AUTOSAR XML (schema 4-2-2)
package /STELLANTIS/EPT/ASWCs
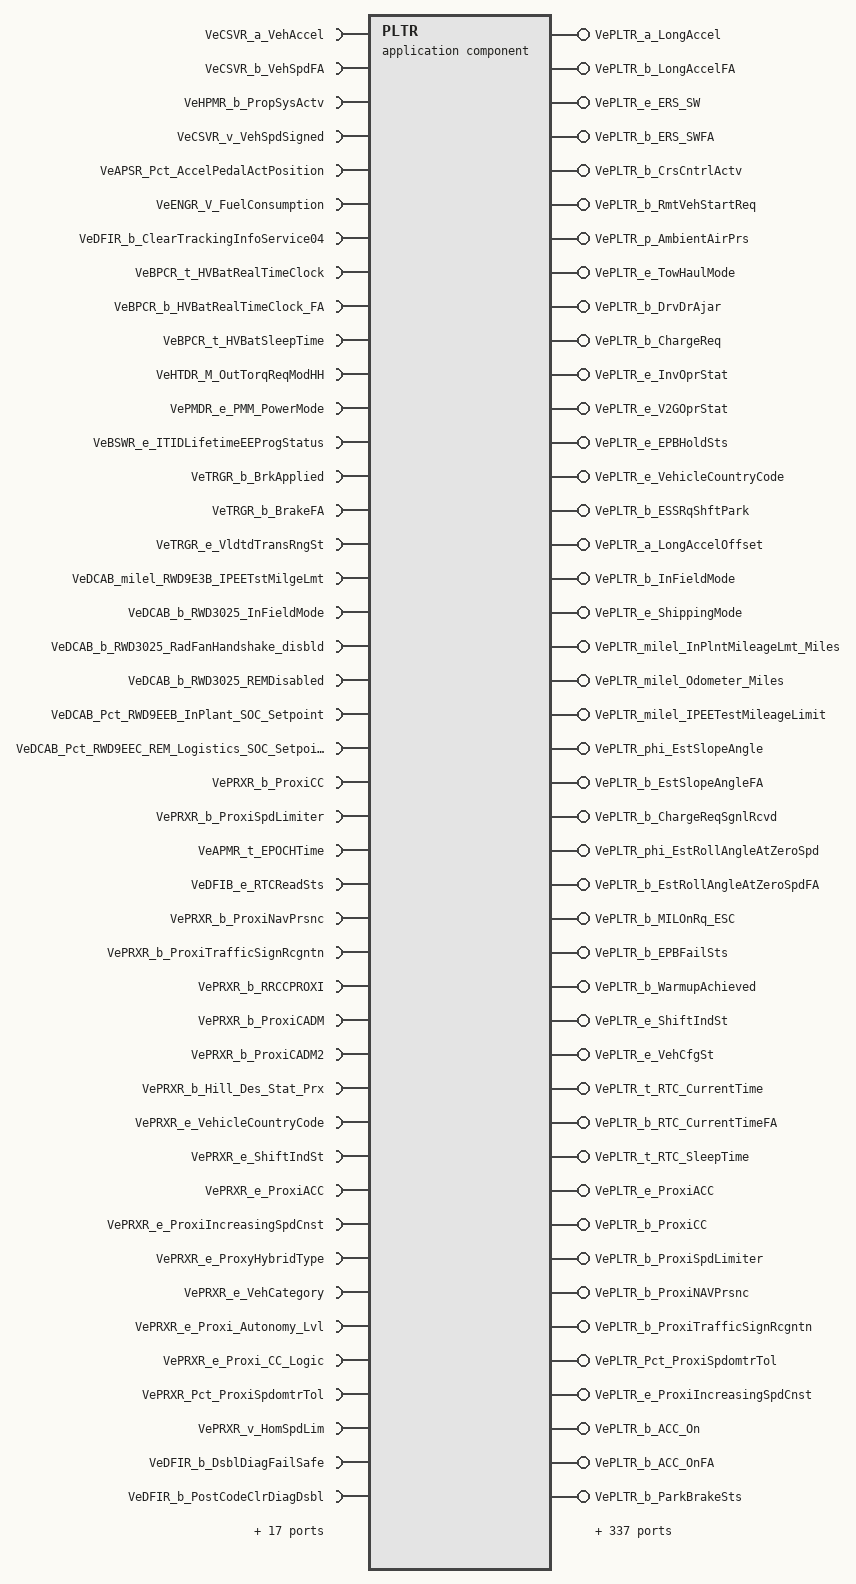
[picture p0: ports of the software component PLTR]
  application sw component type PLTR
    48 x require port:
      VeCSVR_a_VehAccel: nonqueued-receiver-com-spec{data-element=Value, init-value=0}, required-interface=VeCSVR_a_VehAccel
      VeCSVR_b_VehSpdFA: nonqueued-receiver-com-spec{data-element=Value, init-value=0}, required-interface=VeCSVR_b_VehSpdFA
      VeHPMR_b_PropSysActv: nonqueued-receiver-com-spec{data-element=Value, init-value=0}, required-interface=VeHPMR_b_PropSysActv
      VeCSVR_v_VehSpdSigned: nonqueued-receiver-com-spec{data-element=Value, init-value=0}, required-interface=VeCSVR_v_VehSpdSigned
      VeAPSR_Pct_AccelPedalActPosition: nonqueued-receiver-com-spec{data-element=Value, init-value=0}, required-interface=VeAPSR_Pct_AccelPedalActPosition
      VeENGR_V_FuelConsumption: nonqueued-receiver-com-spec{data-element=Value, init-value=0}, required-interface=VeENGR_V_FuelConsumption
      VeDFIR_b_ClearTrackingInfoService04: nonqueued-receiver-com-spec{data-element=Value, init-value=0}, required-interface=VeDFIR_b_ClearTrackingInfoService04
      VeBPCR_t_HVBatRealTimeClock: nonqueued-receiver-com-spec{data-element=Value, init-value=0}, required-interface=VeBPCR_t_HVBatRealTimeClock
      VeBPCR_b_HVBatRealTimeClock_FA: nonqueued-receiver-com-spec{data-element=Value, init-value=0}, required-interface=VeBPCR_b_HVBatRealTimeClock_FA
      VeBPCR_t_HVBatSleepTime: nonqueued-receiver-com-spec{data-element=Value, init-value=0}, required-interface=VeBPCR_t_HVBatSleepTime
      VeHTDR_M_OutTorqReqModHH: nonqueued-receiver-com-spec{data-element=Value, init-value=0}, required-interface=VeHTDR_M_OutTorqReqModHH
      VePMDR_e_PMM_PowerMode: nonqueued-receiver-com-spec{data-element=Value, init-value=CePMDR_e_PowerMode_Off}, required-interface=VePMDR_e_PMM_PowerMode
      VeBSWR_e_ITIDLifetimeEEProgStatus: nonqueued-receiver-com-spec{data-element=Value, init-value=0}, required-interface=VeBSWR_e_ITIDLifetimeEEProgStatus
      VeTRGR_b_BrkApplied: nonqueued-receiver-com-spec{data-element=Value, init-value=0}, required-interface=VeTRGR_b_BrkApplied
      VeTRGR_b_BrakeFA: nonqueued-receiver-com-spec{data-element=Value, init-value=0}, required-interface=VeTRGR_b_BrakeFA
      VeTRGR_e_VldtdTransRngSt: nonqueued-receiver-com-spec{data-element=Value, init-value=CeTRGR_e_NoSelectionAvailable}, required-interface=VeTRGR_e_VldtdTransRngSt
      VeDCAB_milel_RWD9E3B_IPEETstMilgeLmt: nonqueued-receiver-com-spec{data-element=Value, init-value=0}, required-interface=VeDCAB_milel_RWD9E3B_IPEETstMilgeLmt
      VeDCAB_b_RWD3025_InFieldMode: nonqueued-receiver-com-spec{data-element=Value, init-value=0}, required-interface=VeDCAB_b_RWD3025_InFieldMode
      VeDCAB_b_RWD3025_RadFanHandshake_disbld: nonqueued-receiver-com-spec{data-element=Value, init-value=0}, required-interface=VeDCAB_b_RWD3025_RadFanHandshake_disbld
      VeDCAB_b_RWD3025_REMDisabled: nonqueued-receiver-com-spec{data-element=Value, init-value=0}, required-interface=VeDCAB_b_RWD3025_REMDisabled
      VeDCAB_Pct_RWD9EEB_InPlant_SOC_Setpoint: nonqueued-receiver-com-spec{data-element=Value, init-value=0}, required-interface=VeDCAB_Pct_RWD9EEB_InPlant_SOC_Setpoint
      VeDCAB_Pct_RWD9EEC_REM_Logistics_SOC_Setpoint: nonqueued-receiver-com-spec{data-element=Value, init-value=0}, required-interface=VeDCAB_Pct_RWD9EEC_REM_Logistics_SOC_Setpoint
      VePRXR_b_ProxiCC: nonqueued-receiver-com-spec{data-element=Value, init-value=0}, required-interface=VePRXR_b_ProxiCC
      VePRXR_b_ProxiSpdLimiter: nonqueued-receiver-com-spec{data-element=Value, init-value=0}, required-interface=VePRXR_b_ProxiSpdLimiter
      VeAPMR_t_EPOCHTime: nonqueued-receiver-com-spec{data-element=Value, init-value=0}, required-interface=VeAPMR_t_EPOCHTime
      VeDFIB_e_RTCReadSts: nonqueued-receiver-com-spec{data-element=Value, init-value=CeDFIB_e_RTCCallInit}, required-interface=VeDFIB_e_RTCReadSts
      VePRXR_b_ProxiNavPrsnc: nonqueued-receiver-com-spec{data-element=Value, init-value=0}, required-interface=VePRXR_b_ProxiNavPrsnc
      VePRXR_b_ProxiTrafficSignRcgntn: nonqueued-receiver-com-spec{data-element=Value, init-value=0}, required-interface=VePRXR_b_ProxiTrafficSignRcgntn
      VePRXR_b_RRCCPROXI: nonqueued-receiver-com-spec{data-element=Value, init-value=0}, required-interface=VePRXR_b_RRCCPROXI
      VePRXR_b_ProxiCADM: nonqueued-receiver-com-spec{data-element=Value, init-value=0}, required-interface=VePRXR_b_ProxiCADM
      VePRXR_b_ProxiCADM2: nonqueued-receiver-com-spec{data-element=Value, init-value=0}, required-interface=VePRXR_b_ProxiCADM2
      VePRXR_b_Hill_Des_Stat_Prx: nonqueued-receiver-com-spec{data-element=Value, init-value=0}, required-interface=VePRXR_b_Hill_Des_Stat_Prx
      VePRXR_e_VehicleCountryCode: nonqueued-receiver-com-spec{data-element=Value, init-value=CePRXR_e_VCC_OTHERS}, required-interface=VePRXR_e_VehicleCountryCode
      VePRXR_e_ShiftIndSt: nonqueued-receiver-com-spec{data-element=Value, init-value=CePRXR_e_NotPresent}, required-interface=VePRXR_e_ShiftIndSt
      VePRXR_e_ProxiACC: nonqueued-receiver-com-spec{data-element=Value, init-value=CePRXR_e_ACC_Absent}, required-interface=VePRXR_e_ProxiACC
      VePRXR_e_ProxiIncreasingSpdCnst: nonqueued-receiver-com-spec{data-element=Value, init-value=CePRXR_e_Increasing_0}, required-interface=VePRXR_e_ProxiIncreasingSpdCnst
      VePRXR_e_ProxyHybridType: nonqueued-receiver-com-spec{data-element=Value, init-value=CePRXR_e_NotApplicable}, required-interface=VePRXR_e_ProxyHybridType
      VePRXR_e_VehCategory: nonqueued-receiver-com-spec{data-element=Value, init-value=CePRXR_e_Category_M1}, required-interface=VePRXR_e_VehCategory
      VePRXR_e_Proxi_Autonomy_Lvl: nonqueued-receiver-com-spec{data-element=Value, init-value=CePRXR_e_None_Level1}, required-interface=VePRXR_e_Proxi_Autonomy_Lvl
      VePRXR_e_Proxi_CC_Logic: nonqueued-receiver-com-spec{data-element=Value, init-value=CePRXR_e_Logic1}, required-interface=VePRXR_e_Proxi_CC_Logic
      VePRXR_Pct_ProxiSpdomtrTol: nonqueued-receiver-com-spec{data-element=Value, init-value=0}, required-interface=VePRXR_Pct_ProxiSpdomtrTol
      VePRXR_v_HomSpdLim: nonqueued-receiver-com-spec{data-element=Value, init-value=0}, required-interface=VePRXR_v_HomSpdLim
      VeDFIR_b_DsblDiagFailSafe: nonqueued-receiver-com-spec{data-element=Value, init-value=0}, required-interface=VeDFIR_b_DsblDiagFailSafe
      VeDFIR_b_PostCodeClrDiagDsbl: nonqueued-receiver-com-spec{data-element=Value, init-value=0}, required-interface=VeDFIR_b_PostCodeClrDiagDsbl
      VeDFIR_b_IsDiagGlobalConditionsValid: nonqueued-receiver-com-spec{data-element=Value, init-value=0}, required-interface=VeDFIR_b_IsDiagGlobalConditionsValid
      VeDMAB_y_StatusByte_IgnKeyOffTmrPerfTooFast: nonqueued-receiver-com-spec{data-element=Value, init-value=0}, required-interface=VeDMAB_y_StatusByte_IgnKeyOffTmrPerfTooFast
      VeDFIB_b_RTCChipErr: nonqueued-receiver-com-spec{data-element=Value, init-value=0}, required-interface=VeDFIB_b_RTCChipErr
      VeDMAB_y_StatusByte_ECUInplantmodeAct: nonqueued-receiver-com-spec{data-element=Value, init-value=0}, required-interface=VeDMAB_y_StatusByte_ECUInplantmodeAct
    368 x provide port:
      VePLTR_a_LongAccel: nonqueued-sender-com-spec{data-element=Value, init-value=0}, provided-interface=VePLTR_a_LongAccel
      VePLTR_b_LongAccelFA: nonqueued-sender-com-spec{data-element=Value, init-value=0}, provided-interface=VePLTR_b_LongAccelFA
      VePLTR_e_ERS_SW: nonqueued-sender-com-spec{data-element=Value, init-value=CeTRGR_e_ERSBttn_NotActvtd}, provided-interface=VePLTR_e_ERS_SW
      VePLTR_b_ERS_SWFA: nonqueued-sender-com-spec{data-element=Value, init-value=0}, provided-interface=VePLTR_b_ERS_SWFA
      VePLTR_b_CrsCntrlActv: nonqueued-sender-com-spec{data-element=Value, init-value=0}, provided-interface=VePLTR_b_CrsCntrlActv
      VePLTR_b_RmtVehStartReq: nonqueued-sender-com-spec{data-element=Value, init-value=0}, provided-interface=VePLTR_b_RmtVehStartReq
      VePLTR_p_AmbientAirPrs: nonqueued-sender-com-spec{data-element=Value, init-value=0}, provided-interface=VePLTR_p_AmbientAirPrs
      VePLTR_e_TowHaulMode: nonqueued-sender-com-spec{data-element=Value, init-value=CePLTR_e_Towing_MD_RQ_OFF}, provided-interface=VePLTR_e_TowHaulMode
      VePLTR_b_DrvDrAjar: nonqueued-sender-com-spec{data-element=Value, init-value=0}, provided-interface=VePLTR_b_DrvDrAjar
      VePLTR_b_ChargeReq: nonqueued-sender-com-spec{data-element=Value, init-value=0}, provided-interface=VePLTR_b_ChargeReq
      VePLTR_e_InvOprStat: nonqueued-sender-com-spec{data-element=Value, init-value=CePLTR_e_NoPlgIn_Tools}, provided-interface=VePLTR_e_InvOprStat
      VePLTR_e_V2GOprStat: nonqueued-sender-com-spec{data-element=Value, init-value=CePLTR_e_NoPlgIn}, provided-interface=VePLTR_e_V2GOprStat
      VePLTR_e_EPBHoldSts: nonqueued-sender-com-spec{data-element=Value, init-value=CePLTR_e_EPBHoldSts_REL}, provided-interface=VePLTR_e_EPBHoldSts
      VePLTR_e_VehicleCountryCode: nonqueued-sender-com-spec{data-element=Value, init-value=CePLTR_e_VCC_OTHERS}, provided-interface=VePLTR_e_VehicleCountryCode
      VePLTR_b_ESSRqShftPark: nonqueued-sender-com-spec{data-element=Value, init-value=0}, provided-interface=VePLTR_b_ESSRqShftPark
      VePLTR_a_LongAccelOffset: nonqueued-sender-com-spec{data-element=Value, init-value=0}, provided-interface=VePLTR_a_LongAccelOffset
      VePLTR_b_InFieldMode: nonqueued-sender-com-spec{data-element=Value, init-value=0}, provided-interface=VePLTR_b_InFieldMode
      VePLTR_e_ShippingMode: nonqueued-sender-com-spec{data-element=Value, init-value=CePLTR_e_ShipingMode_CUST_MD}, provided-interface=VePLTR_e_ShippingMode
      VePLTR_milel_InPlntMileageLmt_Miles: nonqueued-sender-com-spec{data-element=Value, init-value=0}, provided-interface=VePLTR_milel_InPlntMileageLmt_Miles
      VePLTR_milel_Odometer_Miles: nonqueued-sender-com-spec{data-element=Value, init-value=0}, provided-interface=VePLTR_milel_Odometer_Miles
      VePLTR_milel_IPEETestMileageLimit: nonqueued-sender-com-spec{data-element=Value, init-value=0}, provided-interface=VePLTR_milel_IPEETestMileageLimit
      VePLTR_phi_EstSlopeAngle: nonqueued-sender-com-spec{data-element=Value, init-value=0}, provided-interface=VePLTR_phi_EstSlopeAngle
      VePLTR_b_EstSlopeAngleFA: nonqueued-sender-com-spec{data-element=Value, init-value=0}, provided-interface=VePLTR_b_EstSlopeAngleFA
      VePLTR_b_ChargeReqSgnlRcvd: nonqueued-sender-com-spec{data-element=Value, init-value=0}, provided-interface=VePLTR_b_ChargeReqSgnlRcvd
      VePLTR_phi_EstRollAngleAtZeroSpd: nonqueued-sender-com-spec{data-element=Value, init-value=0}, provided-interface=VePLTR_phi_EstRollAngleAtZeroSpd
      VePLTR_b_EstRollAngleAtZeroSpdFA: nonqueued-sender-com-spec{data-element=Value, init-value=0}, provided-interface=VePLTR_b_EstRollAngleAtZeroSpdFA
      VePLTR_b_MILOnRq_ESC: nonqueued-sender-com-spec{data-element=Value, init-value=0}, provided-interface=VePLTR_b_MILOnRq_ESC
      VePLTR_b_EPBFailSts: nonqueued-sender-com-spec{data-element=Value, init-value=0}, provided-interface=VePLTR_b_EPBFailSts
      VePLTR_b_WarmupAchieved: nonqueued-sender-com-spec{data-element=Value, init-value=0}, provided-interface=VePLTR_b_WarmupAchieved
      VePLTR_e_ShiftIndSt: nonqueued-sender-com-spec{data-element=Value, init-value=CePLTR_e_NotPresent}, provided-interface=VePLTR_e_ShiftIndSt
      VePLTR_e_VehCfgSt: nonqueued-sender-com-spec{data-element=Value, init-value=CePLTR_e_NotAvailable}, provided-interface=VePLTR_e_VehCfgSt
      VePLTR_t_RTC_CurrentTime: nonqueued-sender-com-spec{data-element=Value, init-value=0}, provided-interface=VePLTR_t_RTC_CurrentTime
      VePLTR_b_RTC_CurrentTimeFA: nonqueued-sender-com-spec{data-element=Value, init-value=0}, provided-interface=VePLTR_b_RTC_CurrentTimeFA
      VePLTR_t_RTC_SleepTime: nonqueued-sender-com-spec{data-element=Value, init-value=0}, provided-interface=VePLTR_t_RTC_SleepTime
      VePLTR_e_ProxiACC: nonqueued-sender-com-spec{data-element=Value, init-value=CePLTR_e_ACC_Absent}, provided-interface=VePLTR_e_ProxiACC
      VePLTR_b_ProxiCC: nonqueued-sender-com-spec{data-element=Value, init-value=0}, provided-interface=VePLTR_b_ProxiCC
      VePLTR_b_ProxiSpdLimiter: nonqueued-sender-com-spec{data-element=Value, init-value=0}, provided-interface=VePLTR_b_ProxiSpdLimiter
      VePLTR_b_ProxiNAVPrsnc: nonqueued-sender-com-spec{data-element=Value, init-value=0}, provided-interface=VePLTR_b_ProxiNAVPrsnc
      VePLTR_b_ProxiTrafficSignRcgntn: nonqueued-sender-com-spec{data-element=Value, init-value=0}, provided-interface=VePLTR_b_ProxiTrafficSignRcgntn
      VePLTR_Pct_ProxiSpdomtrTol: nonqueued-sender-com-spec{data-element=Value, init-value=0}, provided-interface=VePLTR_Pct_ProxiSpdomtrTol
      VePLTR_e_ProxiIncreasingSpdCnst: nonqueued-sender-com-spec{data-element=Value, init-value=CePLTR_e_Increasing_0}, provided-interface=VePLTR_e_ProxiIncreasingSpdCnst
      VePLTR_b_ACC_On: nonqueued-sender-com-spec{data-element=Value, init-value=0}, provided-interface=VePLTR_b_ACC_On
      VePLTR_b_ACC_OnFA: nonqueued-sender-com-spec{data-element=Value, init-value=0}, provided-interface=VePLTR_b_ACC_OnFA
      VePLTR_b_ParkBrakeSts: nonqueued-sender-com-spec{data-element=Value, init-value=0}, provided-interface=VePLTR_b_ParkBrakeSts
      VePLTR_b_SpeedUnit: nonqueued-sender-com-spec{data-element=Value, init-value=0}, provided-interface=VePLTR_b_SpeedUnit
      VePLTR_e_ACCSystemSts: nonqueued-sender-com-spec{data-element=Value, init-value=CePLTR_e_Off}, provided-interface=VePLTR_e_ACCSystemSts
      VePLTR_b_InternalLightSts: nonqueued-sender-com-spec{data-element=Value, init-value=0}, provided-interface=VePLTR_b_InternalLightSts
      VePLTR_b_RmtVehStartReqFA: nonqueued-sender-com-spec{data-element=Value, init-value=0}, provided-interface=VePLTR_b_RmtVehStartReqFA
      VePLTR_b_DrvDrAjarFA: nonqueued-sender-com-spec{data-element=Value, init-value=0}, provided-interface=VePLTR_b_DrvDrAjarFA
      VePLTR_i_ShippingModeRaw: nonqueued-sender-com-spec{data-element=Value, init-value=0}, provided-interface=VePLTR_i_ShippingModeRaw
      VePLTR_b_REMDisabled: nonqueued-sender-com-spec{data-element=Value, init-value=0}, provided-interface=VePLTR_b_REMDisabled
      VePLTR_Pct_InPlant_SOCSetPt: nonqueued-sender-com-spec{data-element=Value, init-value=0}, provided-interface=VePLTR_Pct_InPlant_SOCSetPt
      VePLTR_Pct_REMLogisticSOCSetPt: nonqueued-sender-com-spec{data-element=Value, init-value=0}, provided-interface=VePLTR_Pct_REMLogisticSOCSetPt
      VePLTR_b_InPlantAllowCharge: nonqueued-sender-com-spec{data-element=Value, init-value=0}, provided-interface=VePLTR_b_InPlantAllowCharge
      VePLTR_e_Prmry_TransShiftPstn: nonqueued-sender-com-spec{data-element=Value, init-value=CeTRGR_e_NoSelectionAvailable}, provided-interface=VePLTR_e_Prmry_TransShiftPstn
      VePLTR_b_Prmry_TransShiftPstnFA: nonqueued-sender-com-spec{data-element=Value, init-value=0}, provided-interface=VePLTR_b_Prmry_TransShiftPstnFA
      VePLTR_e_ESMTransRngSt: nonqueued-sender-com-spec{data-element=Value, init-value=CeTRGR_e_NoSelectionAvailable}, provided-interface=VePLTR_e_ESMTransRngSt
      VePLTR_e_AutoPosCorrMd: nonqueued-sender-com-spec{data-element=Value, init-value=CeTRGR_e_AutoPosCorrMd_Off}, provided-interface=VePLTR_e_AutoPosCorrMd
      VePLTR_b_ShftLckFlt: nonqueued-sender-com-spec{data-element=Value, init-value=0}, provided-interface=VePLTR_b_ShftLckFlt
      VePLTR_b_RackFaultFA: nonqueued-sender-com-spec{data-element=Value, init-value=0}, provided-interface=VePLTR_b_RackFaultFA
      VePLTR_b_ShftSnsFA: nonqueued-sender-com-spec{data-element=Value, init-value=0}, provided-interface=VePLTR_b_ShftSnsFA
      VePLTR_b_ShiftDspFlt: nonqueued-sender-com-spec{data-element=Value, init-value=0}, provided-interface=VePLTR_b_ShiftDspFlt
      VePLTR_y_GatedParkSwFlt: nonqueued-sender-com-spec{data-element=Value, init-value=0}, provided-interface=VePLTR_y_GatedParkSwFlt
      VePLTR_e_ShiftLeverPosReq: nonqueued-sender-com-spec{data-element=Value, init-value=CeTRGR_e_NoSelectionAvailable}, provided-interface=VePLTR_e_ShiftLeverPosReq
      VePLTR_b_ShiftLeverFailSts: nonqueued-sender-com-spec{data-element=Value, init-value=0}, provided-interface=VePLTR_b_ShiftLeverFailSts
      VePLTR_b_PRNDFailSts: nonqueued-sender-com-spec{data-element=Value, init-value=0}, provided-interface=VePLTR_b_PRNDFailSts
      VePLTR_b_RFHub_ForcePark: nonqueued-sender-com-spec{data-element=Value, init-value=0}, provided-interface=VePLTR_b_RFHub_ForcePark
      VePLTR_e_Scndry_TransShiftPstn: nonqueued-sender-com-spec{data-element=Value, init-value=CeTRGR_e_NoSelectionAvailable}, provided-interface=VePLTR_e_Scndry_TransShiftPstn
      VePLTR_b_Scndry_TransShiftPstnFA: nonqueued-sender-com-spec{data-element=Value, init-value=0}, provided-interface=VePLTR_b_Scndry_TransShiftPstnFA
      VePLTR_e_RationalisedRngSt: nonqueued-sender-com-spec{data-element=Value, init-value=CeTRGR_e_NoSelectionAvailable}, provided-interface=VePLTR_e_RationalisedRngSt
      VePLTR_e_ValidatePstn: nonqueued-sender-com-spec{data-element=Value, init-value=CeTRGR_e_NoSelectionAvailable}, provided-interface=VePLTR_e_ValidatePstn
      VePLTR_b_ManualMode: nonqueued-sender-com-spec{data-element=Value, init-value=0}, provided-interface=VePLTR_b_ManualMode
      VePLTR_e_ProxyHybridType: nonqueued-sender-com-spec{data-element=Value, init-value=CePLTR_e_NotApplicable}, provided-interface=VePLTR_e_ProxyHybridType
      VePLTR_b_EPBHoldStsFA: nonqueued-sender-com-spec{data-element=Value, init-value=0}, provided-interface=VePLTR_b_EPBHoldStsFA
      VePLTR_Cnt_TotalEngRunTime_Recent: nonqueued-sender-com-spec{data-element=Value, init-value=0}, provided-interface=VePLTR_Cnt_TotalEngRunTime_Recent
      VePLTR_Cnt_TotalEngRunTime_Lifetime: nonqueued-sender-com-spec{data-element=Value, init-value=0}, provided-interface=VePLTR_Cnt_TotalEngRunTime_Lifetime
      VePLTR_Cnt_TotalIdleEngRunTime_Recent: nonqueued-sender-com-spec{data-element=Value, init-value=0}, provided-interface=VePLTR_Cnt_TotalIdleEngRunTime_Recent
      VePLTR_Cnt_TotalIdleEngRunTime_Lifetime: nonqueued-sender-com-spec{data-element=Value, init-value=0}, provided-interface=VePLTR_Cnt_TotalIdleEngRunTime_Lifetime
      VePLTR_e_Proxi_Autonomy_Lvl: nonqueued-sender-com-spec{data-element=Value, init-value=CePLTR_e_None_Level1}, provided-interface=VePLTR_e_Proxi_Autonomy_Lvl
      VePLTR_e_Proxi_CC_Logic: nonqueued-sender-com-spec{data-element=Value, init-value=CePLTR_e_Logic1}, provided-interface=VePLTR_e_Proxi_CC_Logic
      VePLTR_b_Hill_Des_Stat_Prx: nonqueued-sender-com-spec{data-element=Value, init-value=0}, provided-interface=VePLTR_b_Hill_Des_Stat_Prx
      VePLTR_e_MRM_Status: nonqueued-sender-com-spec{data-element=Value, init-value=CePLTR_e_Not_Active}, provided-interface=VePLTR_e_MRM_Status
      VePLTR_b_MRM_Status_FA: nonqueued-sender-com-spec{data-element=Value, init-value=0}, provided-interface=VePLTR_b_MRM_Status_FA
      VePLTR_e_LSMDExtReleaseLockReq: nonqueued-sender-com-spec{data-element=Value, init-value=CePLTR_e_NotActive}, provided-interface=VePLTR_e_LSMDExtReleaseLockReq
      VePLTR_b_HotEnablerReq: nonqueued-sender-com-spec{data-element=Value, init-value=0}, provided-interface=VePLTR_b_HotEnablerReq
      VePLTR_b_SpeedUnit_FA: nonqueued-sender-com-spec{data-element=Value, init-value=0}, provided-interface=VePLTR_b_SpeedUnit_FA
      VePLTR_b_ACCSystemSts_FA: nonqueued-sender-com-spec{data-element=Value, init-value=0}, provided-interface=VePLTR_b_ACCSystemSts_FA
      VePLTR_Pct_EstSlopeAnglePct: nonqueued-sender-com-spec{data-element=Value, init-value=0}, provided-interface=VePLTR_Pct_EstSlopeAnglePct
      VePLTR_b_RadFanHndShk_dsbld: nonqueued-sender-com-spec{data-element=Value, init-value=0}, provided-interface=VePLTR_b_RadFanHndShk_dsbld
      VePLTR_v_HomSpdLim: nonqueued-sender-com-spec{data-element=Value, init-value=0}, provided-interface=VePLTR_v_HomSpdLim
      VePLTR_e_VehCategory: nonqueued-sender-com-spec{data-element=Value, init-value=CePLTR_e_Category_M1}, provided-interface=VePLTR_e_VehCategory
      VePLTR_b_HDCEnabledCAN: nonqueued-sender-com-spec{data-element=Value, init-value=0}, provided-interface=VePLTR_b_HDCEnabledCAN
      VePLTR_b_HDCEnabledCAN_FA: nonqueued-sender-com-spec{data-element=Value, init-value=0}, provided-interface=VePLTR_b_HDCEnabledCAN_FA
      VePLTR_phi_LwsAngle: nonqueued-sender-com-spec{data-element=Value, init-value=0}, provided-interface=VePLTR_phi_LwsAngle
      VePLTR_dphi_LwsSpeed: nonqueued-sender-com-spec{data-element=Value, init-value=0}, provided-interface=VePLTR_dphi_LwsSpeed
      VePLTR_e_LwsAngleType: nonqueued-sender-com-spec{data-element=Value, init-value=CePLTR_e_Absolute}, provided-interface=VePLTR_e_LwsAngleType
      VePLTR_a_LongAccel_ORC: nonqueued-sender-com-spec{data-element=Value, init-value=0}, provided-interface=VePLTR_a_LongAccel_ORC
      VePLTR_a_LatAccel_ORC: nonqueued-sender-com-spec{data-element=Value, init-value=0}, provided-interface=VePLTR_a_LatAccel_ORC
      VePLTR_dphi_YawRate_ORC: nonqueued-sender-com-spec{data-element=Value, init-value=0}, provided-interface=VePLTR_dphi_YawRate_ORC
      VePLTR_b_LongAccelFailSts_ORC: nonqueued-sender-com-spec{data-element=Value, init-value=0}, provided-interface=VePLTR_b_LongAccelFailSts_ORC
      VePLTR_b_LatAccelFailSts_ORC: nonqueued-sender-com-spec{data-element=Value, init-value=0}, provided-interface=VePLTR_b_LatAccelFailSts_ORC
      VePLTR_b_YawRateFailSts_ORC: nonqueued-sender-com-spec{data-element=Value, init-value=0}, provided-interface=VePLTR_b_YawRateFailSts_ORC
      VePLTR_e_MRM_Status_C2_FA: nonqueued-sender-com-spec{data-element=Value, init-value=0}, provided-interface=VePLTR_e_MRM_Status_C2_FA
      VePLTR_e_MRM_Status_C2: nonqueued-sender-com-spec{data-element=Value, init-value=CePLTR_e_Not_Active}, provided-interface=VePLTR_e_MRM_Status_C2
      VePLTR_b_ProxiCADM: nonqueued-sender-com-spec{data-element=Value, init-value=0}, provided-interface=VePLTR_b_ProxiCADM
      VePLTR_b_ProxiCADM2: nonqueued-sender-com-spec{data-element=Value, init-value=0}, provided-interface=VePLTR_b_ProxiCADM2
      VePLTR_W_Inverter_PowerDraw: nonqueued-sender-com-spec{data-element=Value, init-value=0}, provided-interface=VePLTR_W_Inverter_PowerDraw
      VePLTR_b_Inverter_PowerDraw_FA: nonqueued-sender-com-spec{data-element=Value, init-value=0}, provided-interface=VePLTR_b_Inverter_PowerDraw_FA
      VePLTR_b_Worksite_Inverter_Active: nonqueued-sender-com-spec{data-element=Value, init-value=0}, provided-interface=VePLTR_b_Worksite_Inverter_Active
      VePLTR_b_Worksite_Inverter_Active_FA: nonqueued-sender-com-spec{data-element=Value, init-value=0}, provided-interface=VePLTR_b_Worksite_Inverter_Active_FA
      VePLTR_e_Worksite_Inverter_Sts: nonqueued-sender-com-spec{data-element=Value, init-value=CePLTR_e_WSInverterSts_NOT_ACTIVE}, provided-interface=VePLTR_e_Worksite_Inverter_Sts
      VePLTR_b_DAI_Enbl: nonqueued-sender-com-spec{data-element=Value, init-value=0}, provided-interface=VePLTR_b_DAI_Enbl
      VePLTR_b_AmbientAirPrsFA: nonqueued-sender-com-spec{data-element=Value, init-value=0}, provided-interface=VePLTR_b_AmbientAirPrsFA
      VePLTR_pmbar_AmbientAirPrs: nonqueued-sender-com-spec{data-element=Value, init-value=0}, provided-interface=VePLTR_pmbar_AmbientAirPrs
      VePLTR_b_FuelLevelLowClster: nonqueued-sender-com-spec{data-element=Value, init-value=0}, provided-interface=VePLTR_b_FuelLevelLowClster
      VePLTR_b_CC_Type: nonqueued-sender-com-spec{data-element=Value, init-value=0}, provided-interface=VePLTR_b_CC_Type
      VePLTR_a_LatAccel: nonqueued-sender-com-spec{data-element=Value, init-value=0}, provided-interface=VePLTR_a_LatAccel
      VePLTR_b_DriverDetected: nonqueued-sender-com-spec{data-element=Value, init-value=0}, provided-interface=VePLTR_b_DriverDetected
      VePLTR_b_RRCCPROXI: nonqueued-sender-com-spec{data-element=Value, init-value=0}, provided-interface=VePLTR_b_RRCCPROXI
      VePLTR_e_BSM_AxleTrq_Enbld: nonqueued-sender-com-spec{data-element=Value, init-value=CePLTR_e_No_Req}, provided-interface=VePLTR_e_BSM_AxleTrq_Enbld
      VePLTR_e_FaultSts_ECUInplantmodeAct: nonqueued-sender-com-spec{data-element=Value, init-value=CeDFIB_e_Init}, provided-interface=VePLTR_e_FaultSts_ECUInplantmodeAct
      VePLTR_e_HAS_TelltaleSts: nonqueued-sender-com-spec{data-element=Value, init-value=CePLTR_e_HAS_TelltaleSts_OFF}, provided-interface=VePLTR_e_HAS_TelltaleSts
      VePLTR_b_HAS_TelltaleSts_FA: nonqueued-sender-com-spec{data-element=Value, init-value=0}, provided-interface=VePLTR_b_HAS_TelltaleSts_FA
      VePLTR_e_AEBSystemSts: nonqueued-sender-com-spec{data-element=Value, init-value=CePLTR_e_FCW_Off}, provided-interface=VePLTR_e_AEBSystemSts
      VePLTR_b_AEBSystemSts_FA: nonqueued-sender-com-spec{data-element=Value, init-value=0}, provided-interface=VePLTR_b_AEBSystemSts_FA
      VePLTR_e_Command_15Sts: nonqueued-sender-com-spec{data-element=Value, init-value=CePLTR_e_Not_Pressed}, provided-interface=VePLTR_e_Command_15Sts
      VePLTR_b_Command_15Sts_FA: nonqueued-sender-com-spec{data-element=Value, init-value=0}, provided-interface=VePLTR_b_Command_15Sts_FA
      VePLTR_b_LHRDoorSts: nonqueued-sender-com-spec{data-element=Value, init-value=0}, provided-interface=VePLTR_b_LHRDoorSts
      VePLTR_b_LHRDoorSts_FA: nonqueued-sender-com-spec{data-element=Value, init-value=0}, provided-interface=VePLTR_b_LHRDoorSts_FA
      VePLTR_b_PsngrDoorSts: nonqueued-sender-com-spec{data-element=Value, init-value=0}, provided-interface=VePLTR_b_PsngrDoorSts
      VePLTR_b_PsngrDoorSts_FA: nonqueued-sender-com-spec{data-element=Value, init-value=0}, provided-interface=VePLTR_b_PsngrDoorSts_FA
      VePLTR_b_ParkBrakeSts_FA: nonqueued-sender-com-spec{data-element=Value, init-value=0}, provided-interface=VePLTR_b_ParkBrakeSts_FA
      VePLTR_b_RHatchSts: nonqueued-sender-com-spec{data-element=Value, init-value=0}, provided-interface=VePLTR_b_RHatchSts
      VePLTR_b_RHatchSts_FA: nonqueued-sender-com-spec{data-element=Value, init-value=0}, provided-interface=VePLTR_b_RHatchSts_FA
      VePLTR_b_RHRDoorSts: nonqueued-sender-com-spec{data-element=Value, init-value=0}, provided-interface=VePLTR_b_RHRDoorSts
      VePLTR_b_RHRDoorSts_FA: nonqueued-sender-com-spec{data-element=Value, init-value=0}, provided-interface=VePLTR_b_RHRDoorSts_FA
      VePLTR_b_ImmoParkReq: nonqueued-sender-com-spec{data-element=Value, init-value=0}, provided-interface=VePLTR_b_ImmoParkReq
      VePLTR_b_LatAccelFA: nonqueued-sender-com-spec{data-element=Value, init-value=0}, provided-interface=VePLTR_b_LatAccelFA
      VePLTR_b_LwsAngleFA: nonqueued-sender-com-spec{data-element=Value, init-value=0}, provided-interface=VePLTR_b_LwsAngleFA
      VePLTR_e_eBurn_Stages: nonqueued-sender-com-spec{data-element=Value, init-value=CePLTR_e_eBurn_NormalStage}, provided-interface=VePLTR_e_eBurn_Stages
      VePLTR_b_eBurn_Stages_FA: nonqueued-sender-com-spec{data-element=Value, init-value=0}, provided-interface=VePLTR_b_eBurn_Stages_FA
      VePLTR_l_TravelDistance: nonqueued-sender-com-spec{data-element=Value, init-value=0}, provided-interface=VePLTR_l_TravelDistance
      VePLTR_b_TravelDistance_FA: nonqueued-sender-com-spec{data-element=Value, init-value=0}, provided-interface=VePLTR_b_TravelDistance_FA
      VePLTR_e_FaultSts_IgnKeyOffTmrPerfTooFast: nonqueued-sender-com-spec{data-element=Value, init-value=CeDFIB_e_Init}, provided-interface=VePLTR_e_FaultSts_IgnKeyOffTmrPerfTooFast
      VePLTR_t_HCPOffTime: nonqueued-sender-com-spec{data-element=Value, init-value=0}, provided-interface=VePLTR_t_HCPOffTime
      VePLTR_b_HCPOffTimeFA: nonqueued-sender-com-spec{data-element=Value, init-value=0}, provided-interface=VePLTR_b_HCPOffTimeFA
      VePLTR_b_BatteryWasDisconnected: nonqueued-sender-com-spec{data-element=Value, init-value=0}, provided-interface=VePLTR_b_BatteryWasDisconnected
      VePLTR_e_SelectSpdSts: nonqueued-sender-com-spec{data-element=Value, init-value=CePLTR_e_SelectSpdSts_OFF}, provided-interface=VePLTR_e_SelectSpdSts
      VePLTR_b_SelectSpdSts_FA: nonqueued-sender-com-spec{data-element=Value, init-value=0}, provided-interface=VePLTR_b_SelectSpdSts_FA
      VePLTR_e_ParkingGearShiftReq_BSM: nonqueued-sender-com-spec{data-element=Value, init-value=CePLTR_e_GearShiftReq_Idle}, provided-interface=VePLTR_e_ParkingGearShiftReq_BSM
      VePLTR_b_ParkingGearShiftReq_BSM_FA: nonqueued-sender-com-spec{data-element=Value, init-value=0}, provided-interface=VePLTR_b_ParkingGearShiftReq_BSM_FA
      VePLTR_Pct_Slope: nonqueued-sender-com-spec{data-element=Value, init-value=0}, provided-interface=VePLTR_Pct_Slope
      VePLTR_b_Slope_FA: nonqueued-sender-com-spec{data-element=Value, init-value=0}, provided-interface=VePLTR_b_Slope_FA
      VePLTR_y_FobSearchResult: nonqueued-sender-com-spec{data-element=Value, init-value=0}, provided-interface=VePLTR_y_FobSearchResult
      VePLTR_b_FobSearchResult_FA: nonqueued-sender-com-spec{data-element=Value, init-value=0}, provided-interface=VePLTR_b_FobSearchResult_FA
      VePLTR_b_Secure_Idle_Req: nonqueued-sender-com-spec{data-element=Value, init-value=0}, provided-interface=VePLTR_b_Secure_Idle_Req
      VePLTR_b_Secure_Idle_Req_FA: nonqueued-sender-com-spec{data-element=Value, init-value=0}, provided-interface=VePLTR_b_Secure_Idle_Req_FA
      VePLTR_e_HiBmLvr_Stat: nonqueued-sender-com-spec{data-element=Value, init-value=CePLTR_e_HiBmLvr_Stat_Idle}, provided-interface=VePLTR_e_HiBmLvr_Stat
      VePLTR_b_HiBmLvr_Stat_FA: nonqueued-sender-com-spec{data-element=Value, init-value=0}, provided-interface=VePLTR_b_HiBmLvr_Stat_FA
      VePLTR_b_RearFogLightSts: nonqueued-sender-com-spec{data-element=Value, init-value=0}, provided-interface=VePLTR_b_RearFogLightSts
      VePLTR_y_AUD_LVL: nonqueued-sender-com-spec{data-element=Value, init-value=0}, provided-interface=VePLTR_y_AUD_LVL
      VePLTR_b_AUD_LVL_FA: nonqueued-sender-com-spec{data-element=Value, init-value=0}, provided-interface=VePLTR_b_AUD_LVL_FA
      VePLTR_b_ADS_SrvSys: nonqueued-sender-com-spec{data-element=Value, init-value=0}, provided-interface=VePLTR_b_ADS_SrvSys
      VePLTR_b_ADS_SrvSys_FA: nonqueued-sender-com-spec{data-element=Value, init-value=0}, provided-interface=VePLTR_b_ADS_SrvSys_FA
      VePLTR_b_ASCM_Srv: nonqueued-sender-com-spec{data-element=Value, init-value=0}, provided-interface=VePLTR_b_ASCM_Srv
      VePLTR_b_ASCM_Srv_FA: nonqueued-sender-com-spec{data-element=Value, init-value=0}, provided-interface=VePLTR_b_ASCM_Srv_FA
      VePLTR_e_ASCM_Stat: nonqueued-sender-com-spec{data-element=Value, init-value=CePLTR_e_ASCM_Stat_NONE}, provided-interface=VePLTR_e_ASCM_Stat
      VePLTR_b_ASCM_Stat_FA: nonqueued-sender-com-spec{data-element=Value, init-value=0}, provided-interface=VePLTR_b_ASCM_Stat_FA
      VePLTR_b_ASCM_SysFail: nonqueued-sender-com-spec{data-element=Value, init-value=0}, provided-interface=VePLTR_b_ASCM_SysFail
      VePLTR_b_ASCM_SysFail_FA: nonqueued-sender-com-spec{data-element=Value, init-value=0}, provided-interface=VePLTR_b_ASCM_SysFail_FA
      VePLTR_b_DriverSeatBeltStsFA: nonqueued-sender-com-spec{data-element=Value, init-value=0}, provided-interface=VePLTR_b_DriverSeatBeltStsFA
      VePLTR_e_DriverSeatBeltSts: nonqueued-sender-com-spec{data-element=Value, init-value=CePLTR_e_DRV_SEATBELT_OK}, provided-interface=VePLTR_e_DriverSeatBeltSts
      VePLTR_kl_Odometer_Km: nonqueued-sender-com-spec{data-element=Value, init-value=0}, provided-interface=VePLTR_kl_Odometer_Km
      VePLTR_b_Odometer_KmFA: nonqueued-sender-com-spec{data-element=Value, init-value=0}, provided-interface=VePLTR_b_Odometer_KmFA
      VePLTR_dVh_FuelConsumption_avrg: nonqueued-sender-com-spec{data-element=Value, init-value=0}, provided-interface=VePLTR_dVh_FuelConsumption_avrg
      VePLTR_b_ClrTrackingInfo: nonqueued-sender-com-spec{data-element=Value, init-value=0}, provided-interface=VePLTR_b_ClrTrackingInfo
      VePLTR_e_ECMVtdFreeze: nonqueued-sender-com-spec{data-element=Value, init-value=CePLTR_e_NoReset}, provided-interface=VePLTR_e_ECMVtdFreeze
      VePLTR_b_ResetFlagLifetime_EEerror: nonqueued-sender-com-spec{data-element=Value, init-value=0}, provided-interface=VePLTR_b_ResetFlagLifetime_EEerror
      VePLTR_b_ResetFlagRecent_EEerror: nonqueued-sender-com-spec{data-element=Value, init-value=0}, provided-interface=VePLTR_b_ResetFlagRecent_EEerror
      FsftPLTR_Pct_Slope: server-com-spec=FsftPLTR_Pct_Slope, provided-interface=FsftPLTR_Pct_Slope
      FsftPLTR_a_LongAccel: server-com-spec=FsftPLTR_a_LongAccel, provided-interface=FsftPLTR_a_LongAccel
      FsftPLTR_a_LongAccelOffset: server-com-spec=FsftPLTR_a_LongAccelOffset, provided-interface=FsftPLTR_a_LongAccelOffset
      FsftPLTR_a_TransAccel: server-com-spec=FsftPLTR_a_TransAccel, provided-interface=FsftPLTR_a_TransAccel
      FsftPLTR_a_TransAccelOffset: server-com-spec=FsftPLTR_a_TransAccelOffset, provided-interface=FsftPLTR_a_TransAccelOffset
      FsftPLTR_b_ACC_On: server-com-spec=FsftPLTR_b_ACC_On, provided-interface=FsftPLTR_b_ACC_On
      FsftPLTR_b_ASCM_Srv: server-com-spec=FsftPLTR_b_ASCM_Srv, provided-interface=FsftPLTR_b_ASCM_Srv
      FsftPLTR_b_ASCM_SysFail: server-com-spec=FsftPLTR_b_ASCM_SysFail, provided-interface=FsftPLTR_b_ASCM_SysFail
      FsftPLTR_b_ASCM_SysSys: server-com-spec=FsftPLTR_b_ASCM_SysSys, provided-interface=FsftPLTR_b_ASCM_SysSys
      FsftPLTR_b_ChargeReq: server-com-spec=FsftPLTR_b_ChargeReq, provided-interface=FsftPLTR_b_ChargeReq
      FsftPLTR_b_DrvDrAjar: server-com-spec=FsftPLTR_b_DrvDrAjar, provided-interface=FsftPLTR_b_DrvDrAjar
      FsftPLTR_b_EPBFailSts: server-com-spec=FsftPLTR_b_EPBFailSts, provided-interface=FsftPLTR_b_EPBFailSts
      FsftPLTR_b_ESSActvEBrake: server-com-spec=FsftPLTR_b_ESSActvEBrake, provided-interface=FsftPLTR_b_ESSActvEBrake
      FsftPLTR_b_ESSRqShftPark: server-com-spec=FsftPLTR_b_ESSRqShftPark, provided-interface=FsftPLTR_b_ESSRqShftPark
      FsftPLTR_b_HDCEnabledCAN: server-com-spec=FsftPLTR_b_HDCEnabledCAN, provided-interface=FsftPLTR_b_HDCEnabledCAN
      FsftPLTR_b_ImmoParkReq: server-com-spec=FsftPLTR_b_ImmoParkReq, provided-interface=FsftPLTR_b_ImmoParkReq
      FsftPLTR_b_Inverter_PowerDraw: server-com-spec=FsftPLTR_b_Inverter_PowerDraw, provided-interface=FsftPLTR_b_Inverter_PowerDraw
      FsftPLTR_b_LHRDoorSts: server-com-spec=FsftPLTR_b_LHRDoorSts, provided-interface=FsftPLTR_b_LHRDoorSts
      FsftPLTR_b_MILOnRq_ESC: server-com-spec=FsftPLTR_b_MILOnRq_ESC, provided-interface=FsftPLTR_b_MILOnRq_ESC
      FsftPLTR_b_ParkBrakeSts: server-com-spec=FsftPLTR_b_ParkBrakeSts, provided-interface=FsftPLTR_b_ParkBrakeSts
      FsftPLTR_b_Prmry_AutoPosCorrMd: server-com-spec=FsftPLTR_b_Prmry_AutoPosCorrMd, provided-interface=FsftPLTR_b_Prmry_AutoPosCorrMd
      FsftPLTR_b_Prmry_ForcePark: server-com-spec=FsftPLTR_b_Prmry_ForcePark, provided-interface=FsftPLTR_b_Prmry_ForcePark
      FsftPLTR_b_Prmry_ManualMode: server-com-spec=FsftPLTR_b_Prmry_ManualMode, provided-interface=FsftPLTR_b_Prmry_ManualMode
      FsftPLTR_b_Prmry_PRNDFailSts: server-com-spec=FsftPLTR_b_Prmry_PRNDFailSts, provided-interface=FsftPLTR_b_Prmry_PRNDFailSts
      FsftPLTR_b_Prmry_PRND_ValidatePstn: server-com-spec=FsftPLTR_b_Prmry_PRND_ValidatePstn, provided-interface=FsftPLTR_b_Prmry_PRND_ValidatePstn
      FsftPLTR_b_Prmry_RackDetentSensorFA: server-com-spec=FsftPLTR_b_Prmry_RackDetentSensorFA, provided-interface=FsftPLTR_b_Prmry_RackDetentSensorFA
      FsftPLTR_b_Prmry_ShiftLeverFailSts: server-com-spec=FsftPLTR_b_Prmry_ShiftLeverFailSts, provided-interface=FsftPLTR_b_Prmry_ShiftLeverFailSts
      FsftPLTR_b_Prmry_ShiftLeverPositionReq: server-com-spec=FsftPLTR_b_Prmry_ShiftLeverPositionReq, provided-interface=FsftPLTR_b_Prmry_ShiftLeverPositionReq
      FsftPLTR_b_Prmry_ShiftLockFA: server-com-spec=FsftPLTR_b_Prmry_ShiftLockFA, provided-interface=FsftPLTR_b_Prmry_ShiftLockFA
      FsftPLTR_b_Prmry_ShiftSnsFA: server-com-spec=FsftPLTR_b_Prmry_ShiftSnsFA, provided-interface=FsftPLTR_b_Prmry_ShiftSnsFA
      FsftPLTR_b_Prmry_ShifterDispFA: server-com-spec=FsftPLTR_b_Prmry_ShifterDispFA, provided-interface=FsftPLTR_b_Prmry_ShifterDispFA
      FsftPLTR_b_Prmry_TransShiftPstn: server-com-spec=FsftPLTR_b_Prmry_TransShiftPstn, provided-interface=FsftPLTR_b_Prmry_TransShiftPstn
      FsftPLTR_b_PsngrDoorSts: server-com-spec=FsftPLTR_b_PsngrDoorSts, provided-interface=FsftPLTR_b_PsngrDoorSts
      FsftPLTR_b_RHRDoorSts: server-com-spec=FsftPLTR_b_RHRDoorSts, provided-interface=FsftPLTR_b_RHRDoorSts
      FsftPLTR_b_RHatchSts: server-com-spec=FsftPLTR_b_RHatchSts, provided-interface=FsftPLTR_b_RHatchSts
      FsftPLTR_b_RmtVehStartReq: server-com-spec=FsftPLTR_b_RmtVehStartReq, provided-interface=FsftPLTR_b_RmtVehStartReq
      FsftPLTR_b_Scndry_AutoPosCorrMd: server-com-spec=FsftPLTR_b_Scndry_AutoPosCorrMd, provided-interface=FsftPLTR_b_Scndry_AutoPosCorrMd
      FsftPLTR_b_Scndry_ForcePark: server-com-spec=FsftPLTR_b_Scndry_ForcePark, provided-interface=FsftPLTR_b_Scndry_ForcePark
      FsftPLTR_b_Scndry_PRNDFailSts: server-com-spec=FsftPLTR_b_Scndry_PRNDFailSts, provided-interface=FsftPLTR_b_Scndry_PRNDFailSts
      FsftPLTR_b_Scndry_PRND_ValidatePstn: server-com-spec=FsftPLTR_b_Scndry_PRND_ValidatePstn, provided-interface=FsftPLTR_b_Scndry_PRND_ValidatePstn
      FsftPLTR_b_Scndry_RackDetentSensorFA: server-com-spec=FsftPLTR_b_Scndry_RackDetentSensorFA, provided-interface=FsftPLTR_b_Scndry_RackDetentSensorFA
      FsftPLTR_b_Scndry_ShiftLeverFailSts: server-com-spec=FsftPLTR_b_Scndry_ShiftLeverFailSts, provided-interface=FsftPLTR_b_Scndry_ShiftLeverFailSts
      FsftPLTR_b_Scndry_ShiftLeverPositionReq: server-com-spec=FsftPLTR_b_Scndry_ShiftLeverPositionReq, provided-interface=FsftPLTR_b_Scndry_ShiftLeverPositionReq
      FsftPLTR_b_Scndry_ShiftLockFA: server-com-spec=FsftPLTR_b_Scndry_ShiftLockFA, provided-interface=FsftPLTR_b_Scndry_ShiftLockFA
      FsftPLTR_b_Scndry_ShiftSnsFA: server-com-spec=FsftPLTR_b_Scndry_ShiftSnsFA, provided-interface=FsftPLTR_b_Scndry_ShiftSnsFA
      FsftPLTR_b_Scndry_ShifterDispFA: server-com-spec=FsftPLTR_b_Scndry_ShifterDispFA, provided-interface=FsftPLTR_b_Scndry_ShifterDispFA
      FsftPLTR_b_Scndry_TransShiftPstn: server-com-spec=FsftPLTR_b_Scndry_TransShiftPstn, provided-interface=FsftPLTR_b_Scndry_TransShiftPstn
      FsftPLTR_b_Secure_Idle_Req: server-com-spec=FsftPLTR_b_Secure_Idle_Req, provided-interface=FsftPLTR_b_Secure_Idle_Req
      FsftPLTR_b_SpeedUnit: server-com-spec=FsftPLTR_b_SpeedUnit, provided-interface=FsftPLTR_b_SpeedUnit
      FsftPLTR_b_Worksite_Inverter_Active: server-com-spec=FsftPLTR_b_Worksite_Inverter_Active, provided-interface=FsftPLTR_b_Worksite_Inverter_Active
      FsftPLTR_e_ACCSystemSts: server-com-spec=FsftPLTR_e_ACCSystemSts, provided-interface=FsftPLTR_e_ACCSystemSts
      FsftPLTR_e_AEBSystemSts: server-com-spec=FsftPLTR_e_AEBSystemSts, provided-interface=FsftPLTR_e_AEBSystemSts
      FsftPLTR_e_ASCM_Stat: server-com-spec=FsftPLTR_e_ASCM_Stat, provided-interface=FsftPLTR_e_ASCM_Stat
      FsftPLTR_e_Command_15Sts: server-com-spec=FsftPLTR_e_Command_15Sts, provided-interface=FsftPLTR_e_Command_15Sts
      FsftPLTR_e_DriverDoorOnOffSts: server-com-spec=FsftPLTR_e_DriverDoorOnOffSts, provided-interface=FsftPLTR_e_DriverDoorOnOffSts
      FsftPLTR_e_DriverSeatBeltSts: server-com-spec=FsftPLTR_e_DriverSeatBeltSts, provided-interface=FsftPLTR_e_DriverSeatBeltSts
      FsftPLTR_e_DrvrSeatSnsrSts: server-com-spec=FsftPLTR_e_DrvrSeatSnsrSts, provided-interface=FsftPLTR_e_DrvrSeatSnsrSts
      FsftPLTR_e_EPBHoldSt: server-com-spec=FsftPLTR_e_EPBHoldSt, provided-interface=FsftPLTR_e_EPBHoldSt
      FsftPLTR_e_ERS_SW: server-com-spec=FsftPLTR_e_ERS_SW, provided-interface=FsftPLTR_e_ERS_SW
      FsftPLTR_e_HAS_TelltaleSts: server-com-spec=FsftPLTR_e_HAS_TelltaleSts, provided-interface=FsftPLTR_e_HAS_TelltaleSts
      FsftPLTR_e_HiBmLvr_Stat: server-com-spec=FsftPLTR_e_HiBmLvr_Stat, provided-interface=FsftPLTR_e_HiBmLvr_Stat
      FsftPLTR_e_LSMDExtReleaseLockReq: server-com-spec=FsftPLTR_e_LSMDExtReleaseLockReq, provided-interface=FsftPLTR_e_LSMDExtReleaseLockReq
      FsftPLTR_e_MRM_Status: server-com-spec=FsftPLTR_e_MRM_Status, provided-interface=FsftPLTR_e_MRM_Status
      FsftPLTR_e_MRM_Status_C2: server-com-spec=FsftPLTR_e_MRM_Status_C2, provided-interface=FsftPLTR_e_MRM_Status_C2
      FsftPLTR_e_ParkingGearShiftReq_BSM: server-com-spec=FsftPLTR_e_ParkingGearShiftReq_BSM, provided-interface=FsftPLTR_e_ParkingGearShiftReq_BSM
      FsftPLTR_e_SelectSpdSts: server-com-spec=FsftPLTR_e_SelectSpdSts, provided-interface=FsftPLTR_e_SelectSpdSts
      FsftPLTR_e_TowHaulMode: server-com-spec=FsftPLTR_e_TowHaulMode, provided-interface=FsftPLTR_e_TowHaulMode
      FsftPLTR_e_VehicleCountryCode: server-com-spec=FsftPLTR_e_VehicleCountryCode, provided-interface=FsftPLTR_e_VehicleCountryCode
      FsftPLTR_e_eBurn_Stages: server-com-spec=FsftPLTR_e_eBurn_Stages, provided-interface=FsftPLTR_e_eBurn_Stages
      FsftPLTR_l_Odometer_Km: server-com-spec=FsftPLTR_l_Odometer_Km, provided-interface=FsftPLTR_l_Odometer_Km
      FsftPLTR_l_TravelDistance: server-com-spec=FsftPLTR_l_TravelDistance, provided-interface=FsftPLTR_l_TravelDistance
      FsftPLTR_p_AmbientAirPrs: server-com-spec=FsftPLTR_p_AmbientAirPrs, provided-interface=FsftPLTR_p_AmbientAirPrs
      FsftPLTR_phi_LwsAngle: server-com-spec=FsftPLTR_phi_LwsAngle, provided-interface=FsftPLTR_phi_LwsAngle
      FsftPLTR_t_GPS_UTC_Second: server-com-spec=FsftPLTR_t_GPS_UTC_Second, provided-interface=FsftPLTR_t_GPS_UTC_Second
      FsftPLTR_tdy_GPS_Date_Day: server-com-spec=FsftPLTR_tdy_GPS_Date_Day, provided-interface=FsftPLTR_tdy_GPS_Date_Day
      FsftPLTR_thr_GPS_UTC_Hour: server-com-spec=FsftPLTR_thr_GPS_UTC_Hour, provided-interface=FsftPLTR_thr_GPS_UTC_Hour
      FsftPLTR_tmn_GPS_UTC_Minute: server-com-spec=FsftPLTR_tmn_GPS_UTC_Minute, provided-interface=FsftPLTR_tmn_GPS_UTC_Minute
      FsftPLTR_tmt_GPS_Date_Month: server-com-spec=FsftPLTR_tmt_GPS_Date_Month, provided-interface=FsftPLTR_tmt_GPS_Date_Month
      FsftPLTR_tyr_GPS_Date_Year: server-com-spec=FsftPLTR_tyr_GPS_Date_Year, provided-interface=FsftPLTR_tyr_GPS_Date_Year
      FsftPLTR_y_AUD_LVL: server-com-spec=FsftPLTR_y_AUD_LVL, provided-interface=FsftPLTR_y_AUD_LVL
      FsftPLTR_y_FobSearchResult: server-com-spec=FsftPLTR_y_FobSearchResult, provided-interface=FsftPLTR_y_FobSearchResult
      PokePLTR_Pct_Slope: server-com-spec{operation=PokePLTR_Pct_Slope, queue-length=1}, provided-interface=PokePLTR_Pct_Slope
      PokePLTR_ReInit_EEPROM: server-com-spec=PokePLTR_ReInit_EEPROM, provided-interface=PokePLTR_ReInit_EEPROM
      PokePLTR_W_Inverter_PowerDraw: server-com-spec{operation=PokePLTR_W_Inverter_PowerDraw, queue-length=1}, provided-interface=PokePLTR_W_Inverter_PowerDraw
      PokePLTR_a_LatAccel_ORC: server-com-spec{operation=PokePLTR_a_LatAccel_ORC, queue-length=1}, provided-interface=PokePLTR_a_LatAccel_ORC
      PokePLTR_a_LongAccel: server-com-spec{operation=PokePLTR_a_LongAccel, queue-length=1}, provided-interface=PokePLTR_a_LongAccel
      PokePLTR_a_LongAccelOffset: server-com-spec{operation=PokePLTR_a_LongAccelOffset, queue-length=1}, provided-interface=PokePLTR_a_LongAccelOffset
      PokePLTR_a_LongAccel_ORC: server-com-spec{operation=PokePLTR_a_LongAccel_ORC, queue-length=1}, provided-interface=PokePLTR_a_LongAccel_ORC
      PokePLTR_a_TransAccel: server-com-spec{operation=PokePLTR_a_TransAccel, queue-length=1}, provided-interface=PokePLTR_a_TransAccel
      PokePLTR_a_TransAccelOffset: server-com-spec{operation=PokePLTR_a_TransAccelOffset, queue-length=1}, provided-interface=PokePLTR_a_TransAccelOffset
      PokePLTR_b_ACCEnbld: server-com-spec{operation=PokePLTR_b_ACCEnbld, queue-length=1}, provided-interface=PokePLTR_b_ACCEnbld
      PokePLTR_b_ACC_On: server-com-spec{operation=PokePLTR_b_ACC_On, queue-length=1}, provided-interface=PokePLTR_b_ACC_On
      PokePLTR_b_ASCM_Srv: server-com-spec{operation=PokePLTR_b_ASCM_Srv, queue-length=1}, provided-interface=PokePLTR_b_ASCM_Srv
      PokePLTR_b_ASCM_SysFail: server-com-spec{operation=PokePLTR_b_ASCM_SysFail, queue-length=1}, provided-interface=PokePLTR_b_ASCM_SysFail
      PokePLTR_b_ASCM_SysSys: server-com-spec{operation=PokePLTR_b_ASCM_SysSys, queue-length=1}, provided-interface=PokePLTR_b_ASCM_SysSys
      PokePLTR_b_CC_Type: server-com-spec{operation=PokePLTR_b_CC_Type, queue-length=1}, provided-interface=PokePLTR_b_CC_Type
      PokePLTR_b_ChargeReq: server-com-spec{operation=PokePLTR_b_ChargeReq, queue-length=1}, provided-interface=PokePLTR_b_ChargeReq
      PokePLTR_b_CrsCntrlActv: server-com-spec{operation=PokePLTR_b_CrsCntrlActv, queue-length=1}, provided-interface=PokePLTR_b_CrsCntrlActv
      PokePLTR_b_DoorFailSts: server-com-spec{operation=PokePLTR_b_DoorFailSts, queue-length=1}, provided-interface=PokePLTR_b_DoorFailSts
      PokePLTR_b_DriverSeatBeltSts: server-com-spec{operation=PokePLTR_b_DriverSeatBeltSts, queue-length=1}, provided-interface=PokePLTR_b_DriverSeatBeltSts
      PokePLTR_b_DrvDrAjar: server-com-spec{operation=PokePLTR_b_DrvDrAjar, queue-length=1}, provided-interface=PokePLTR_b_DrvDrAjar
      PokePLTR_b_DrvrSeatSnsrFailSts: server-com-spec{operation=PokePLTR_b_DrvrSeatSnsrFailSts, queue-length=1}, provided-interface=PokePLTR_b_DrvrSeatSnsrFailSts
      PokePLTR_b_EPBFailSts: server-com-spec{operation=PokePLTR_b_EPBFailSts, queue-length=1}, provided-interface=PokePLTR_b_EPBFailSts
      PokePLTR_b_ESSActvEBrake: server-com-spec{operation=PokePLTR_b_ESSActvEBrake, queue-length=1}, provided-interface=PokePLTR_b_ESSActvEBrake
      PokePLTR_b_ESSRqShftPark: server-com-spec{operation=PokePLTR_b_ESSRqShftPark, queue-length=1}, provided-interface=PokePLTR_b_ESSRqShftPark
      PokePLTR_b_FuelLevelLowClster: server-com-spec{operation=PokePLTR_b_FuelLevelLowClster, queue-length=1}, provided-interface=PokePLTR_b_FuelLevelLowClster
      PokePLTR_b_HDCEnabledCAN: server-com-spec{operation=PokePLTR_b_HDCEnabledCAN, queue-length=1}, provided-interface=PokePLTR_b_HDCEnabledCAN
      PokePLTR_b_HotEnablerReq: server-com-spec{operation=PokePLTR_b_HotEnablerReq, queue-length=1}, provided-interface=PokePLTR_b_HotEnablerReq
      PokePLTR_b_ImmoParkReq: server-com-spec{operation=PokePLTR_b_ImmoParkReq, queue-length=1}, provided-interface=PokePLTR_b_ImmoParkReq
      PokePLTR_b_InPlantAllowCharge: server-com-spec{operation=PokePLTR_b_InPlantAllowCharge, queue-length=1}, provided-interface=PokePLTR_b_InPlantAllowCharge
      PokePLTR_b_InternalLightSts: server-com-spec{operation=PokePLTR_b_InternalLightSts, queue-length=1}, provided-interface=PokePLTR_b_InternalLightSts
      PokePLTR_b_LHRDoorSts: server-com-spec{operation=PokePLTR_b_LHRDoorSts, queue-length=1}, provided-interface=PokePLTR_b_LHRDoorSts
      PokePLTR_b_LatAccelFailSts_ORC: server-com-spec{operation=PokePLTR_b_LatAccelFailSts_ORC, queue-length=1}, provided-interface=PokePLTR_b_LatAccelFailSts_ORC
      PokePLTR_b_LongAccelFailSts_ORC: server-com-spec{operation=PokePLTR_b_LongAccelFailSts_ORC, queue-length=1}, provided-interface=PokePLTR_b_LongAccelFailSts_ORC
      PokePLTR_b_MILOnRq_ESC: server-com-spec{operation=PokePLTR_b_MILOnRq_ESC, queue-length=1}, provided-interface=PokePLTR_b_MILOnRq_ESC
      PokePLTR_b_ParkBrakeSts: server-com-spec{operation=PokePLTR_b_ParkBrakeSts, queue-length=1}, provided-interface=PokePLTR_b_ParkBrakeSts
      PokePLTR_b_Prmry_ManualMode: server-com-spec{operation=PokePLTR_b_Prmry_ManualMode, queue-length=1}, provided-interface=PokePLTR_b_Prmry_ManualMode
      PokePLTR_b_Prmry_PRNDFailSts: server-com-spec{operation=PokePLTR_b_Prmry_PRNDFailSts, queue-length=1}, provided-interface=PokePLTR_b_Prmry_PRNDFailSts
      PokePLTR_b_Prmry_RFHub_ForcePark: server-com-spec{operation=PokePLTR_b_Prmry_RFHub_ForcePark, queue-length=1}, provided-interface=PokePLTR_b_Prmry_RFHub_ForcePark
      PokePLTR_b_Prmry_RackDetentSensorFA: server-com-spec{operation=PokePLTR_b_Prmry_RackDetentSensorFA, queue-length=1}, provided-interface=PokePLTR_b_Prmry_RackDetentSensorFA
      PokePLTR_b_Prmry_ShiftLeverFailSts: server-com-spec{operation=PokePLTR_b_Prmry_ShiftLeverFailSts, queue-length=1}, provided-interface=PokePLTR_b_Prmry_ShiftLeverFailSts
      PokePLTR_b_Prmry_ShiftLockFA: server-com-spec{operation=PokePLTR_b_Prmry_ShiftLockFA, queue-length=1}, provided-interface=PokePLTR_b_Prmry_ShiftLockFA
      PokePLTR_b_Prmry_ShiftSnsFA: server-com-spec{operation=PokePLTR_b_Prmry_ShiftSnsFA, queue-length=1}, provided-interface=PokePLTR_b_Prmry_ShiftSnsFA
      PokePLTR_b_Prmry_ShifterDispFA: server-com-spec{operation=PokePLTR_b_Prmry_ShifterDispFA, queue-length=1}, provided-interface=PokePLTR_b_Prmry_ShifterDispFA
      PokePLTR_b_PsngrDoorSts: server-com-spec{operation=PokePLTR_b_PsngrDoorSts, queue-length=1}, provided-interface=PokePLTR_b_PsngrDoorSts
      PokePLTR_b_RHRDoorSts: server-com-spec{operation=PokePLTR_b_RHRDoorSts, queue-length=1}, provided-interface=PokePLTR_b_RHRDoorSts
      PokePLTR_b_RHatchSts: server-com-spec{operation=PokePLTR_b_RHatchSts, queue-length=1}, provided-interface=PokePLTR_b_RHatchSts
      PokePLTR_b_RearFogLightSts: server-com-spec{operation=PokePLTR_b_RearFogLightSts, queue-length=1}, provided-interface=PokePLTR_b_RearFogLightSts
      PokePLTR_b_RmtVehStartReq: server-com-spec{operation=PokePLTR_b_RmtVehStartReq, queue-length=1}, provided-interface=PokePLTR_b_RmtVehStartReq
      PokePLTR_b_Scndry_PRNDFailSts: server-com-spec{operation=PokePLTR_b_Scndry_PRNDFailSts, queue-length=1}, provided-interface=PokePLTR_b_Scndry_PRNDFailSts
      PokePLTR_b_Scndry_RFHub_ForcePark: server-com-spec{operation=PokePLTR_b_Scndry_RFHub_ForcePark, queue-length=1}, provided-interface=PokePLTR_b_Scndry_RFHub_ForcePark
      PokePLTR_b_Scndry_RackDetentSensorFA: server-com-spec{operation=PokePLTR_b_Scndry_RackDetentSensorFA, queue-length=1}, provided-interface=PokePLTR_b_Scndry_RackDetentSensorFA
      PokePLTR_b_Scndry_ShiftLeverFailSts: server-com-spec{operation=PokePLTR_b_Scndry_ShiftLeverFailSts, queue-length=1}, provided-interface=PokePLTR_b_Scndry_ShiftLeverFailSts
      PokePLTR_b_Scndry_ShiftLockFA: server-com-spec{operation=PokePLTR_b_Scndry_ShiftLockFA, queue-length=1}, provided-interface=PokePLTR_b_Scndry_ShiftLockFA
      PokePLTR_b_Scndry_ShiftSnsFA: server-com-spec{operation=PokePLTR_b_Scndry_ShiftSnsFA, queue-length=1}, provided-interface=PokePLTR_b_Scndry_ShiftSnsFA
      PokePLTR_b_Scndry_ShifterDispFA: server-com-spec{operation=PokePLTR_b_Scndry_ShifterDispFA, queue-length=1}, provided-interface=PokePLTR_b_Scndry_ShifterDispFA
      PokePLTR_b_Secure_Idle_Req: server-com-spec{operation=PokePLTR_b_Secure_Idle_Req, queue-length=1}, provided-interface=PokePLTR_b_Secure_Idle_Req
      PokePLTR_b_SpeedUnit: server-com-spec{operation=PokePLTR_b_SpeedUnit, queue-length=1}, provided-interface=PokePLTR_b_SpeedUnit
      PokePLTR_b_Worksite_Inverter_Active: server-com-spec{operation=PokePLTR_b_Worksite_Inverter_Active, queue-length=1}, provided-interface=PokePLTR_b_Worksite_Inverter_Active
      PokePLTR_b_YawRateFailSts_ORC: server-com-spec{operation=PokePLTR_b_YawRateFailSts_ORC, queue-length=1}, provided-interface=PokePLTR_b_YawRateFailSts_ORC
      PokePLTR_dphi_LwsSpeed: server-com-spec{operation=PokePLTR_dphi_LwsSpeed, queue-length=1}, provided-interface=PokePLTR_dphi_LwsSpeed
      PokePLTR_dphi_YawRate_ORC: server-com-spec{operation=PokePLTR_dphi_YawRate_ORC, queue-length=1}, provided-interface=PokePLTR_dphi_YawRate_ORC
      PokePLTR_e_ACCSystemSts: server-com-spec{operation=PokePLTR_e_ACCSystemSts, queue-length=1}, provided-interface=PokePLTR_e_ACCSystemSts
      PokePLTR_e_AEBSystemSts: server-com-spec{operation=PokePLTR_e_AEBSystemSts, queue-length=1}, provided-interface=PokePLTR_e_AEBSystemSts
      PokePLTR_e_ASCM_Stat: server-com-spec{operation=PokePLTR_e_ASCM_Stat, queue-length=1}, provided-interface=PokePLTR_e_ASCM_Stat
      PokePLTR_e_BSM_AxleTrq_Enbld: server-com-spec{operation=PokePLTR_e_BSM_AxleTrq_Enbld, queue-length=1}, provided-interface=PokePLTR_e_BSM_AxleTrq_Enbld
      PokePLTR_e_Command_15Sts: server-com-spec{operation=PokePLTR_e_Command_15Sts, queue-length=1}, provided-interface=PokePLTR_e_Command_15Sts
      PokePLTR_e_DriverDoorOnOffSts: server-com-spec{operation=PokePLTR_e_DriverDoorOnOffSts, queue-length=1}, provided-interface=PokePLTR_e_DriverDoorOnOffSts
      PokePLTR_e_DrvrSeatSnsrSts: server-com-spec{operation=PokePLTR_e_DrvrSeatSnsrSts, queue-length=1}, provided-interface=PokePLTR_e_DrvrSeatSnsrSts
      PokePLTR_e_ECMVtdFreeze: server-com-spec{operation=PokePLTR_e_ECMVtdFreeze, queue-length=1}, provided-interface=PokePLTR_e_ECMVtdFreeze
      PokePLTR_e_EPBHoldSt: server-com-spec{operation=PokePLTR_e_EPBHoldSt, queue-length=1}, provided-interface=PokePLTR_e_EPBHoldSt
      PokePLTR_e_ERS_SW: server-com-spec{operation=PokePLTR_e_ERS_SW, queue-length=1}, provided-interface=PokePLTR_e_ERS_SW
      PokePLTR_e_GatedParkSw_FaultSts: server-com-spec{operation=PokePLTR_e_GatedParkSw_FaultSts, queue-length=1}, provided-interface=PokePLTR_e_GatedParkSw_FaultSts
      PokePLTR_e_HAS_TelltaleSts: server-com-spec{operation=PokePLTR_e_HAS_TelltaleSts, queue-length=1}, provided-interface=PokePLTR_e_HAS_TelltaleSts
      PokePLTR_e_HiBmLvr_Stat: server-com-spec{operation=PokePLTR_e_HiBmLvr_Stat, queue-length=1}, provided-interface=PokePLTR_e_HiBmLvr_Stat
      PokePLTR_e_InvrOprStatus: server-com-spec{operation=PokePLTR_e_InvrOprStatus, queue-length=1}, provided-interface=PokePLTR_e_InvrOprStatus
      PokePLTR_e_LSMDExtReleaseLockReq: server-com-spec{operation=PokePLTR_e_LSMDExtReleaseLockReq, queue-length=1}, provided-interface=PokePLTR_e_LSMDExtReleaseLockReq
      PokePLTR_e_LwsAngleType: server-com-spec{operation=PokePLTR_e_LwsAngleType, queue-length=1}, provided-interface=PokePLTR_e_LwsAngleType
      PokePLTR_e_MRM_Status: server-com-spec{operation=PokePLTR_e_MRM_Status, queue-length=1}, provided-interface=PokePLTR_e_MRM_Status
      PokePLTR_e_MRM_Status_C2: server-com-spec{operation=PokePLTR_e_MRM_Status_C2, queue-length=1}, provided-interface=PokePLTR_e_MRM_Status_C2
      PokePLTR_e_ParkingGearShiftReq_BSM: server-com-spec{operation=PokePLTR_e_ParkingGearShiftReq_BSM, queue-length=1}, provided-interface=PokePLTR_e_ParkingGearShiftReq_BSM
      PokePLTR_e_Prmry_AutoPosCorrMd: server-com-spec{operation=PokePLTR_e_Prmry_AutoPosCorrMd, queue-length=1}, provided-interface=PokePLTR_e_Prmry_AutoPosCorrMd
      PokePLTR_e_Prmry_PRND_ValidatePstn: server-com-spec{operation=PokePLTR_e_Prmry_PRND_ValidatePstn, queue-length=1}, provided-interface=PokePLTR_e_Prmry_PRND_ValidatePstn
      PokePLTR_e_Prmry_ShiftLeverPositionReq: server-com-spec{operation=PokePLTR_e_Prmry_ShiftLeverPositionReq, queue-length=1}, provided-interface=PokePLTR_e_Prmry_ShiftLeverPositionReq
      PokePLTR_e_Prmry_TransShiftPstn: server-com-spec{operation=PokePLTR_e_Prmry_TransShiftPstn, queue-length=1}, provided-interface=PokePLTR_e_Prmry_TransShiftPstn
      PokePLTR_e_Scndry_AutoPosCorrMd: server-com-spec{operation=PokePLTR_e_Scndry_AutoPosCorrMd, queue-length=1}, provided-interface=PokePLTR_e_Scndry_AutoPosCorrMd
      PokePLTR_e_Scndry_PRND_ValidatePstn: server-com-spec{operation=PokePLTR_e_Scndry_PRND_ValidatePstn, queue-length=1}, provided-interface=PokePLTR_e_Scndry_PRND_ValidatePstn
      PokePLTR_e_Scndry_ShiftLeverPositionReq: server-com-spec{operation=PokePLTR_e_Scndry_ShiftLeverPositionReq, queue-length=1}, provided-interface=PokePLTR_e_Scndry_ShiftLeverPositionReq
      PokePLTR_e_Scndry_TransShiftPstn: server-com-spec{operation=PokePLTR_e_Scndry_TransShiftPstn, queue-length=1}, provided-interface=PokePLTR_e_Scndry_TransShiftPstn
      PokePLTR_e_SelectSpdSts: server-com-spec{operation=PokePLTR_e_SelectSpdSts, queue-length=1}, provided-interface=PokePLTR_e_SelectSpdSts
      PokePLTR_e_ShipingMode: server-com-spec{operation=PokePLTR_e_ShipingMode, queue-length=1}, provided-interface=PokePLTR_e_ShipingMode
      PokePLTR_e_TowHaulMode: server-com-spec{operation=PokePLTR_e_TowHaulMode, queue-length=1}, provided-interface=PokePLTR_e_TowHaulMode
      PokePLTR_e_V2GOprStat: server-com-spec{operation=PokePLTR_e_V2GOprStat, queue-length=1}, provided-interface=PokePLTR_e_V2GOprStat
      PokePLTR_e_VehCfgSt: server-com-spec{operation=PokePLTR_e_VehCfgSt, queue-length=1}, provided-interface=PokePLTR_e_VehCfgSt
      PokePLTR_e_Worksite_Inverter_Sts: server-com-spec{operation=PokePLTR_e_Worksite_Inverter_Sts, queue-length=1}, provided-interface=PokePLTR_e_Worksite_Inverter_Sts
      PokePLTR_e_eBurn_Stages: server-com-spec{operation=PokePLTR_e_eBurn_Stages, queue-length=1}, provided-interface=PokePLTR_e_eBurn_Stages
      PokePLTR_l_Odometer_Km: server-com-spec{operation=PokePLTR_l_Odometer_Km, queue-length=1}, provided-interface=PokePLTR_l_Odometer_Km
      PokePLTR_l_TravelDistance: server-com-spec{operation=PokePLTR_l_TravelDistance, queue-length=1}, provided-interface=PokePLTR_l_TravelDistance
      PokePLTR_p_AmbientAirPrs: server-com-spec{operation=PokePLTR_p_AmbientAirPrs, queue-length=1}, provided-interface=PokePLTR_p_AmbientAirPrs
      PokePLTR_phi_LwsAngle: server-com-spec{operation=PokePLTR_phi_LwsAngle, queue-length=1}, provided-interface=PokePLTR_phi_LwsAngle
      PokePLTR_t_GPS_UTC_Second: server-com-spec{operation=PokePLTR_t_GPS_UTC_Second, queue-length=1}, provided-interface=PokePLTR_t_GPS_UTC_Second
      PokePLTR_tdy_GPS_Date_Day: server-com-spec{operation=PokePLTR_tdy_GPS_Date_Day, queue-length=1}, provided-interface=PokePLTR_tdy_GPS_Date_Day
      PokePLTR_thr_GPS_UTC_Hour: server-com-spec{operation=PokePLTR_thr_GPS_UTC_Hour, queue-length=1}, provided-interface=PokePLTR_thr_GPS_UTC_Hour
      PokePLTR_tmn_GPS_UTC_Minute: server-com-spec{operation=PokePLTR_tmn_GPS_UTC_Minute, queue-length=1}, provided-interface=PokePLTR_tmn_GPS_UTC_Minute
      PokePLTR_tmt_GPS_Date_Month: server-com-spec{operation=PokePLTR_tmt_GPS_Date_Month, queue-length=1}, provided-interface=PokePLTR_tmt_GPS_Date_Month
      PokePLTR_tyr_GPS_Date_Year: server-com-spec{operation=PokePLTR_tyr_GPS_Date_Year, queue-length=1}, provided-interface=PokePLTR_tyr_GPS_Date_Year
      PokePLTR_y_AUD_LVL: server-com-spec{operation=PokePLTR_y_AUD_LVL, queue-length=1}, provided-interface=PokePLTR_y_AUD_LVL
      PokePLTR_y_FobSearchResult: server-com-spec{operation=PokePLTR_y_FobSearchResult, queue-length=1}, provided-interface=PokePLTR_y_FobSearchResult
      TmotPLTR_b_ChargeReq: server-com-spec=TmotPLTR_b_ChargeReq, provided-interface=TmotPLTR_b_ChargeReq
    13 x require port:
      EePLTR_t_RTCTime_Rx: nv-require-com-spec{init-value=0, variable=EePLTR_t_RTCTime}, required-interface=EePLTR_t_RTCTime
      EePLTR_e_RTCStatus_Rx: nv-require-com-spec{init-value=0, variable=EePLTR_e_RTCStatus}, required-interface=EePLTR_e_RTCStatus
      EePLTR_t_PowerdownTime_Rx: nv-require-com-spec{init-value=0, variable=EePLTR_t_PowerdownTime}, required-interface=EePLTR_t_PowerdownTime
      EePLTR_e_ShippingMode_Rx: nv-require-com-spec{init-value=0, variable=EePLTR_e_ShippingMode}, required-interface=EePLTR_e_ShippingMode
      EePLTR_b_RTC_CurrentTimeFA_Rx: nv-require-com-spec{init-value=0, variable=EePLTR_b_RTC_CurrentTimeFA}, required-interface=EePLTR_b_RTC_CurrentTimeFA
      AePLTR_b_InFieldMode_Rx: nv-require-com-spec{init-value=0, variable=AePLTR_b_InFieldMode}, required-interface=AePLTR_b_InFieldMode
      AePLTR_milel_IPEETestMileageLimit_Rx: nv-require-com-spec{init-value=0, variable=AePLTR_milel_IPEETestMileageLimit}, required-interface=AePLTR_milel_IPEETestMileageLimit
      AePLTR_Pct_IP_SOCSetPt_Rx: nv-require-com-spec{init-value=0, variable=AePLTR_Pct_IP_SOCSetPt}, required-interface=AePLTR_Pct_IP_SOCSetPt
      AePLTR_Pct_CS_SOCSetPt_Rx: nv-require-com-spec{init-value=0, variable=AePLTR_Pct_CS_SOCSetPt}, required-interface=AePLTR_Pct_CS_SOCSetPt
      AePLTR_b_RadFanHandshake_disbld_Rx: nv-require-com-spec{init-value=0, variable=AePLTR_b_RadFanHandshake_disbld}, required-interface=AePLTR_b_RadFanHandshake_disbld
      AePLTR_b_REMDisabled_Rx: nv-require-com-spec{init-value=0, variable=AePLTR_b_REMDisabled}, required-interface=AePLTR_b_REMDisabled
      AePLTR_milel_OdometerLimit_Rx: nv-require-com-spec{init-value=0, variable=AePLTR_milel_OdometerLimit}, required-interface=AePLTR_milel_OdometerLimit
      AePLTR_b_PwrOffOk_Rx: nv-require-com-spec{init-value=0, variable=AePLTR_b_PwrOffOk}, required-interface=AePLTR_b_PwrOffOk
    13 x provide port:
      EePLTR_t_RTCTime: nv-provide-com-spec{ram-block-init-value=0, variable=EePLTR_t_RTCTime}, provided-interface=EePLTR_t_RTCTime
      EePLTR_e_RTCStatus: nv-provide-com-spec{ram-block-init-value=0, variable=EePLTR_e_RTCStatus}, provided-interface=EePLTR_e_RTCStatus
      EePLTR_t_PowerdownTime: nv-provide-com-spec{ram-block-init-value=0, variable=EePLTR_t_PowerdownTime}, provided-interface=EePLTR_t_PowerdownTime
      EePLTR_e_ShippingMode: nv-provide-com-spec{ram-block-init-value=0, variable=EePLTR_e_ShippingMode}, provided-interface=EePLTR_e_ShippingMode
      EePLTR_b_RTC_CurrentTimeFA: nv-provide-com-spec{ram-block-init-value=0, variable=EePLTR_b_RTC_CurrentTimeFA}, provided-interface=EePLTR_b_RTC_CurrentTimeFA
      AePLTR_b_InFieldMode: nv-provide-com-spec{ram-block-init-value=0, variable=AePLTR_b_InFieldMode}, provided-interface=AePLTR_b_InFieldMode
      AePLTR_milel_IPEETestMileageLimit: nv-provide-com-spec{ram-block-init-value=0, variable=AePLTR_milel_IPEETestMileageLimit}, provided-interface=AePLTR_milel_IPEETestMileageLimit
      AePLTR_Pct_IP_SOCSetPt: nv-provide-com-spec{ram-block-init-value=0, variable=AePLTR_Pct_IP_SOCSetPt}, provided-interface=AePLTR_Pct_IP_SOCSetPt
      AePLTR_Pct_CS_SOCSetPt: nv-provide-com-spec{ram-block-init-value=0, variable=AePLTR_Pct_CS_SOCSetPt}, provided-interface=AePLTR_Pct_CS_SOCSetPt
      AePLTR_b_RadFanHandshake_disbld: nv-provide-com-spec{ram-block-init-value=0, variable=AePLTR_b_RadFanHandshake_disbld}, provided-interface=AePLTR_b_RadFanHandshake_disbld
      AePLTR_b_REMDisabled: nv-provide-com-spec{ram-block-init-value=0, variable=AePLTR_b_REMDisabled}, provided-interface=AePLTR_b_REMDisabled
      AePLTR_milel_OdometerLimit: nv-provide-com-spec{ram-block-init-value=0, variable=AePLTR_milel_OdometerLimit}, provided-interface=AePLTR_milel_OdometerLimit
      AePLTR_b_PwrOffOk: nv-provide-com-spec{ram-block-init-value=0, variable=AePLTR_b_PwrOffOk}, provided-interface=AePLTR_b_PwrOffOk
    behavior IB_PLTR: data-type-mapping=msADTtoIDTMapping, handle-termination-and-restart=NO-SUPPORT, included-data-type-set=data-type=TePLTR_e_RTCSyncDiagStat
      4 x timing event:
        Event_MedTEB: start-on-event=PLTR_MedTEB, period=0.01
        Event_MedTED: start-on-event=PLTR_MedTED, period=0.02
        Event_MedTEH: start-on-event=PLTR_MedTEH, period=0.1
        Event_SlowTEF: start-on-event=PLTR_SlowTEF, period=1
      189 x operation invoked event:
        Event_FsftPLTR_Pct_Slope: start-on-event=FsftPLTR_Pct_Slope, operation=FsftPLTR_Pct_Slope.FsftPLTR_Pct_Slope
        Event_FsftPLTR_a_LongAccel: start-on-event=FsftPLTR_a_LongAccel, operation=FsftPLTR_a_LongAccel.FsftPLTR_a_LongAccel
        Event_FsftPLTR_a_LongAccelOffset: start-on-event=FsftPLTR_a_LongAccelOffset, operation=FsftPLTR_a_LongAccelOffset.FsftPLTR_a_LongAccelOffset
        Event_FsftPLTR_a_TransAccel: start-on-event=FsftPLTR_a_TransAccel, operation=FsftPLTR_a_TransAccel.FsftPLTR_a_TransAccel
        Event_FsftPLTR_a_TransAccelOffset: start-on-event=FsftPLTR_a_TransAccelOffset, operation=FsftPLTR_a_TransAccelOffset.FsftPLTR_a_TransAccelOffset
        Event_FsftPLTR_b_ACC_On: start-on-event=FsftPLTR_b_ACC_On, operation=FsftPLTR_b_ACC_On.FsftPLTR_b_ACC_On
        Event_FsftPLTR_b_ASCM_Srv: start-on-event=FsftPLTR_b_ASCM_Srv, operation=FsftPLTR_b_ASCM_Srv.FsftPLTR_b_ASCM_Srv
        Event_FsftPLTR_b_ASCM_SysFail: start-on-event=FsftPLTR_b_ASCM_SysFail, operation=FsftPLTR_b_ASCM_SysFail.FsftPLTR_b_ASCM_SysFail
        Event_FsftPLTR_b_ASCM_SysSys: start-on-event=FsftPLTR_b_ASCM_SysSys, operation=FsftPLTR_b_ASCM_SysSys.FsftPLTR_b_ASCM_SysSys
        Event_FsftPLTR_b_ChargeReq: start-on-event=FsftPLTR_b_ChargeReq, operation=FsftPLTR_b_ChargeReq.FsftPLTR_b_ChargeReq
        Event_FsftPLTR_b_DrvDrAjar: start-on-event=FsftPLTR_b_DrvDrAjar, operation=FsftPLTR_b_DrvDrAjar.FsftPLTR_b_DrvDrAjar
        Event_FsftPLTR_b_EPBFailSts: start-on-event=FsftPLTR_b_EPBFailSts, operation=FsftPLTR_b_EPBFailSts.FsftPLTR_b_EPBFailSts
        Event_FsftPLTR_b_ESSActvEBrake: start-on-event=FsftPLTR_b_ESSActvEBrake, operation=FsftPLTR_b_ESSActvEBrake.FsftPLTR_b_ESSActvEBrake
        Event_FsftPLTR_b_ESSRqShftPark: start-on-event=FsftPLTR_b_ESSRqShftPark, operation=FsftPLTR_b_ESSRqShftPark.FsftPLTR_b_ESSRqShftPark
        Event_FsftPLTR_b_HDCEnabledCAN: start-on-event=FsftPLTR_b_HDCEnabledCAN, operation=FsftPLTR_b_HDCEnabledCAN.FsftPLTR_b_HDCEnabledCAN
        Event_FsftPLTR_b_ImmoParkReq: start-on-event=FsftPLTR_b_ImmoParkReq, operation=FsftPLTR_b_ImmoParkReq.FsftPLTR_b_ImmoParkReq
        Event_FsftPLTR_b_Inverter_PowerDraw: start-on-event=FsftPLTR_b_Inverter_PowerDraw, operation=FsftPLTR_b_Inverter_PowerDraw.FsftPLTR_b_Inverter_PowerDraw
        Event_FsftPLTR_b_LHRDoorSts: start-on-event=FsftPLTR_b_LHRDoorSts, operation=FsftPLTR_b_LHRDoorSts.FsftPLTR_b_LHRDoorSts
        Event_FsftPLTR_b_MILOnRq_ESC: start-on-event=FsftPLTR_b_MILOnRq_ESC, operation=FsftPLTR_b_MILOnRq_ESC.FsftPLTR_b_MILOnRq_ESC
        Event_FsftPLTR_b_ParkBrakeSts: start-on-event=FsftPLTR_b_ParkBrakeSts, operation=FsftPLTR_b_ParkBrakeSts.FsftPLTR_b_ParkBrakeSts
        Event_FsftPLTR_b_Prmry_AutoPosCorrMd: start-on-event=FsftPLTR_b_Prmry_AutoPosCorrMd, operation=FsftPLTR_b_Prmry_AutoPosCorrMd.FsftPLTR_b_Prmry_AutoPosCorrMd
        Event_FsftPLTR_b_Prmry_ForcePark: start-on-event=FsftPLTR_b_Prmry_ForcePark, operation=FsftPLTR_b_Prmry_ForcePark.FsftPLTR_b_Prmry_ForcePark
        Event_FsftPLTR_b_Prmry_ManualMode: start-on-event=FsftPLTR_b_Prmry_ManualMode, operation=FsftPLTR_b_Prmry_ManualMode.FsftPLTR_b_Prmry_ManualMode
        Event_FsftPLTR_b_Prmry_PRNDFailSts: start-on-event=FsftPLTR_b_Prmry_PRNDFailSts, operation=FsftPLTR_b_Prmry_PRNDFailSts.FsftPLTR_b_Prmry_PRNDFailSts
        Event_FsftPLTR_b_Prmry_PRND_ValidatePstn: start-on-event=FsftPLTR_b_Prmry_PRND_ValidatePstn, operation=FsftPLTR_b_Prmry_PRND_ValidatePstn.FsftPLTR_b_Prmry_PRND_ValidatePstn
        Event_FsftPLTR_b_Prmry_RackDetentSensorFA: start-on-event=FsftPLTR_b_Prmry_RackDetentSensorFA, operation=FsftPLTR_b_Prmry_RackDetentSensorFA.FsftPLTR_b_Prmry_RackDetentSensorFA
        Event_FsftPLTR_b_Prmry_ShiftLeverFailSts: start-on-event=FsftPLTR_b_Prmry_ShiftLeverFailSts, operation=FsftPLTR_b_Prmry_ShiftLeverFailSts.FsftPLTR_b_Prmry_ShiftLeverFailSts
        Event_FsftPLTR_b_Prmry_ShiftLeverPositionReq: start-on-event=FsftPLTR_b_Prmry_ShiftLeverPositionReq, operation=FsftPLTR_b_Prmry_ShiftLeverPositionReq.FsftPLTR_b_Prmry_ShiftLeverPositionReq
        Event_FsftPLTR_b_Prmry_ShiftLockFA: start-on-event=FsftPLTR_b_Prmry_ShiftLockFA, operation=FsftPLTR_b_Prmry_ShiftLockFA.FsftPLTR_b_Prmry_ShiftLockFA
        Event_FsftPLTR_b_Prmry_ShiftSnsFA: start-on-event=FsftPLTR_b_Prmry_ShiftSnsFA, operation=FsftPLTR_b_Prmry_ShiftSnsFA.FsftPLTR_b_Prmry_ShiftSnsFA
        Event_FsftPLTR_b_Prmry_ShifterDispFA: start-on-event=FsftPLTR_b_Prmry_ShifterDispFA, operation=FsftPLTR_b_Prmry_ShifterDispFA.FsftPLTR_b_Prmry_ShifterDispFA
        Event_FsftPLTR_b_Prmry_TransShiftPstn: start-on-event=FsftPLTR_b_Prmry_TransShiftPstn, operation=FsftPLTR_b_Prmry_TransShiftPstn.FsftPLTR_b_Prmry_TransShiftPstn
        Event_FsftPLTR_b_PsngrDoorSts: start-on-event=FsftPLTR_b_PsngrDoorSts, operation=FsftPLTR_b_PsngrDoorSts.FsftPLTR_b_PsngrDoorSts
        Event_FsftPLTR_b_RHRDoorSts: start-on-event=FsftPLTR_b_RHRDoorSts, operation=FsftPLTR_b_RHRDoorSts.FsftPLTR_b_RHRDoorSts
        Event_FsftPLTR_b_RHatchSts: start-on-event=FsftPLTR_b_RHatchSts, operation=FsftPLTR_b_RHatchSts.FsftPLTR_b_RHatchSts
        Event_FsftPLTR_b_RmtVehStartReq: start-on-event=FsftPLTR_b_RmtVehStartReq, operation=FsftPLTR_b_RmtVehStartReq.FsftPLTR_b_RmtVehStartReq
        Event_FsftPLTR_b_Scndry_AutoPosCorrMd: start-on-event=FsftPLTR_b_Scndry_AutoPosCorrMd, operation=FsftPLTR_b_Scndry_AutoPosCorrMd.FsftPLTR_b_Scndry_AutoPosCorrMd
        Event_FsftPLTR_b_Scndry_ForcePark: start-on-event=FsftPLTR_b_Scndry_ForcePark, operation=FsftPLTR_b_Scndry_ForcePark.FsftPLTR_b_Scndry_ForcePark
        Event_FsftPLTR_b_Scndry_PRNDFailSts: start-on-event=FsftPLTR_b_Scndry_PRNDFailSts, operation=FsftPLTR_b_Scndry_PRNDFailSts.FsftPLTR_b_Scndry_PRNDFailSts
        Event_FsftPLTR_b_Scndry_PRND_ValidatePstn: start-on-event=FsftPLTR_b_Scndry_PRND_ValidatePstn, operation=FsftPLTR_b_Scndry_PRND_ValidatePstn.FsftPLTR_b_Scndry_PRND_ValidatePstn
        Event_FsftPLTR_b_Scndry_RackDetentSensorFA: start-on-event=FsftPLTR_b_Scndry_RackDetentSensorFA, operation=FsftPLTR_b_Scndry_RackDetentSensorFA.FsftPLTR_b_Scndry_RackDetentSensorFA
        Event_FsftPLTR_b_Scndry_ShiftLeverFailSts: start-on-event=FsftPLTR_b_Scndry_ShiftLeverFailSts, operation=FsftPLTR_b_Scndry_ShiftLeverFailSts.FsftPLTR_b_Scndry_ShiftLeverFailSts
        Event_FsftPLTR_b_Scndry_ShiftLeverPositionReq: start-on-event=FsftPLTR_b_Scndry_ShiftLeverPositionReq, operation=FsftPLTR_b_Scndry_ShiftLeverPositionReq.FsftPLTR_b_Scndry_ShiftLeverPositionReq
        Event_FsftPLTR_b_Scndry_ShiftLockFA: start-on-event=FsftPLTR_b_Scndry_ShiftLockFA, operation=FsftPLTR_b_Scndry_ShiftLockFA.FsftPLTR_b_Scndry_ShiftLockFA
        Event_FsftPLTR_b_Scndry_ShiftSnsFA: start-on-event=FsftPLTR_b_Scndry_ShiftSnsFA, operation=FsftPLTR_b_Scndry_ShiftSnsFA.FsftPLTR_b_Scndry_ShiftSnsFA
        Event_FsftPLTR_b_Scndry_ShifterDispFA: start-on-event=FsftPLTR_b_Scndry_ShifterDispFA, operation=FsftPLTR_b_Scndry_ShifterDispFA.FsftPLTR_b_Scndry_ShifterDispFA
        Event_FsftPLTR_b_Scndry_TransShiftPstn: start-on-event=FsftPLTR_b_Scndry_TransShiftPstn, operation=FsftPLTR_b_Scndry_TransShiftPstn.FsftPLTR_b_Scndry_TransShiftPstn
        Event_FsftPLTR_b_Secure_Idle_Req: start-on-event=FsftPLTR_b_Secure_Idle_Req, operation=FsftPLTR_b_Secure_Idle_Req.FsftPLTR_b_Secure_Idle_Req
        Event_FsftPLTR_b_SpeedUnit: start-on-event=FsftPLTR_b_SpeedUnit, operation=FsftPLTR_b_SpeedUnit.FsftPLTR_b_SpeedUnit
        Event_FsftPLTR_b_Worksite_Inverter_Active: start-on-event=FsftPLTR_b_Worksite_Inverter_Active, operation=FsftPLTR_b_Worksite_Inverter_Active.FsftPLTR_b_Worksite_Inverter_Active
        Event_FsftPLTR_e_ACCSystemSts: start-on-event=FsftPLTR_e_ACCSystemSts, operation=FsftPLTR_e_ACCSystemSts.FsftPLTR_e_ACCSystemSts
        Event_FsftPLTR_e_AEBSystemSts: start-on-event=FsftPLTR_e_AEBSystemSts, operation=FsftPLTR_e_AEBSystemSts.FsftPLTR_e_AEBSystemSts
        Event_FsftPLTR_e_ASCM_Stat: start-on-event=FsftPLTR_e_ASCM_Stat, operation=FsftPLTR_e_ASCM_Stat.FsftPLTR_e_ASCM_Stat
        Event_FsftPLTR_e_Command_15Sts: start-on-event=FsftPLTR_e_Command_15Sts, operation=FsftPLTR_e_Command_15Sts.FsftPLTR_e_Command_15Sts
        Event_FsftPLTR_e_DriverDoorOnOffSts: start-on-event=FsftPLTR_e_DriverDoorOnOffSts, operation=FsftPLTR_e_DriverDoorOnOffSts.FsftPLTR_e_DriverDoorOnOffSts
        Event_FsftPLTR_e_DriverSeatBeltSts: start-on-event=FsftPLTR_e_DriverSeatBeltSts, operation=FsftPLTR_e_DriverSeatBeltSts.FsftPLTR_e_DriverSeatBeltSts
        Event_FsftPLTR_e_DrvrSeatSnsrSts: start-on-event=FsftPLTR_e_DrvrSeatSnsrSts, operation=FsftPLTR_e_DrvrSeatSnsrSts.FsftPLTR_e_DrvrSeatSnsrSts
        Event_FsftPLTR_e_EPBHoldSt: start-on-event=FsftPLTR_e_EPBHoldSt, operation=FsftPLTR_e_EPBHoldSt.FsftPLTR_e_EPBHoldSt
        Event_FsftPLTR_e_ERS_SW: start-on-event=FsftPLTR_e_ERS_SW, operation=FsftPLTR_e_ERS_SW.FsftPLTR_e_ERS_SW
        Event_FsftPLTR_e_HAS_TelltaleSts: start-on-event=FsftPLTR_e_HAS_TelltaleSts, operation=FsftPLTR_e_HAS_TelltaleSts.FsftPLTR_e_HAS_TelltaleSts
        Event_FsftPLTR_e_HiBmLvr_Stat: start-on-event=FsftPLTR_e_HiBmLvr_Stat, operation=FsftPLTR_e_HiBmLvr_Stat.FsftPLTR_e_HiBmLvr_Stat
        Event_FsftPLTR_e_LSMDExtReleaseLockReq: start-on-event=FsftPLTR_e_LSMDExtReleaseLockReq, operation=FsftPLTR_e_LSMDExtReleaseLockReq.FsftPLTR_e_LSMDExtReleaseLockReq
        Event_FsftPLTR_e_MRM_Status: start-on-event=FsftPLTR_e_MRM_Status, operation=FsftPLTR_e_MRM_Status.FsftPLTR_e_MRM_Status
        Event_FsftPLTR_e_MRM_Status_C2: start-on-event=FsftPLTR_e_MRM_Status_C2, operation=FsftPLTR_e_MRM_Status_C2.FsftPLTR_e_MRM_Status_C2
        Event_FsftPLTR_e_ParkingGearShiftReq_BSM: start-on-event=FsftPLTR_e_ParkingGearShiftReq_BSM, operation=FsftPLTR_e_ParkingGearShiftReq_BSM.FsftPLTR_e_ParkingGearShiftReq_BSM
        Event_FsftPLTR_e_SelectSpdSts: start-on-event=FsftPLTR_e_SelectSpdSts, operation=FsftPLTR_e_SelectSpdSts.FsftPLTR_e_SelectSpdSts
        Event_FsftPLTR_e_TowHaulMode: start-on-event=FsftPLTR_e_TowHaulMode, operation=FsftPLTR_e_TowHaulMode.FsftPLTR_e_TowHaulMode
        Event_FsftPLTR_e_VehicleCountryCode: start-on-event=FsftPLTR_e_VehicleCountryCode, operation=FsftPLTR_e_VehicleCountryCode.FsftPLTR_e_VehicleCountryCode
        Event_FsftPLTR_e_eBurn_Stages: start-on-event=FsftPLTR_e_eBurn_Stages, operation=FsftPLTR_e_eBurn_Stages.FsftPLTR_e_eBurn_Stages
        Event_FsftPLTR_l_Odometer_Km: start-on-event=FsftPLTR_l_Odometer_Km, operation=FsftPLTR_l_Odometer_Km.FsftPLTR_l_Odometer_Km
        Event_FsftPLTR_l_TravelDistance: start-on-event=FsftPLTR_l_TravelDistance, operation=FsftPLTR_l_TravelDistance.FsftPLTR_l_TravelDistance
        Event_FsftPLTR_p_AmbientAirPrs: start-on-event=FsftPLTR_p_AmbientAirPrs, operation=FsftPLTR_p_AmbientAirPrs.FsftPLTR_p_AmbientAirPrs
        Event_FsftPLTR_phi_LwsAngle: start-on-event=FsftPLTR_phi_LwsAngle, operation=FsftPLTR_phi_LwsAngle.FsftPLTR_phi_LwsAngle
        Event_FsftPLTR_t_GPS_UTC_Second: start-on-event=FsftPLTR_t_GPS_UTC_Second, operation=FsftPLTR_t_GPS_UTC_Second.FsftPLTR_t_GPS_UTC_Second
        Event_FsftPLTR_tdy_GPS_Date_Day: start-on-event=FsftPLTR_tdy_GPS_Date_Day, operation=FsftPLTR_tdy_GPS_Date_Day.FsftPLTR_tdy_GPS_Date_Day
        Event_FsftPLTR_thr_GPS_UTC_Hour: start-on-event=FsftPLTR_thr_GPS_UTC_Hour, operation=FsftPLTR_thr_GPS_UTC_Hour.FsftPLTR_thr_GPS_UTC_Hour
        Event_FsftPLTR_tmn_GPS_UTC_Minute: start-on-event=FsftPLTR_tmn_GPS_UTC_Minute, operation=FsftPLTR_tmn_GPS_UTC_Minute.FsftPLTR_tmn_GPS_UTC_Minute
        Event_FsftPLTR_tmt_GPS_Date_Month: start-on-event=FsftPLTR_tmt_GPS_Date_Month, operation=FsftPLTR_tmt_GPS_Date_Month.FsftPLTR_tmt_GPS_Date_Month
        Event_FsftPLTR_tyr_GPS_Date_Year: start-on-event=FsftPLTR_tyr_GPS_Date_Year, operation=FsftPLTR_tyr_GPS_Date_Year.FsftPLTR_tyr_GPS_Date_Year
        Event_FsftPLTR_y_AUD_LVL: start-on-event=FsftPLTR_y_AUD_LVL, operation=FsftPLTR_y_AUD_LVL.FsftPLTR_y_AUD_LVL
        Event_FsftPLTR_y_FobSearchResult: start-on-event=FsftPLTR_y_FobSearchResult, operation=FsftPLTR_y_FobSearchResult.FsftPLTR_y_FobSearchResult
        Event_PokePLTR_Pct_Slope: start-on-event=PokePLTR_Pct_Slope, operation=PokePLTR_Pct_Slope.PokePLTR_Pct_Slope
        Event_PokePLTR_ReInit_EEPROM: start-on-event=PokePLTR_ReInit_EEPROM, operation=PokePLTR_ReInit_EEPROM.PokePLTR_ReInit_EEPROM
        Event_PokePLTR_W_Inverter_PowerDraw: start-on-event=PokePLTR_W_Inverter_PowerDraw, operation=PokePLTR_W_Inverter_PowerDraw.PokePLTR_W_Inverter_PowerDraw
        Event_PokePLTR_a_LatAccel_ORC: start-on-event=PokePLTR_a_LatAccel_ORC, operation=PokePLTR_a_LatAccel_ORC.PokePLTR_a_LatAccel_ORC
        Event_PokePLTR_a_LongAccel: start-on-event=PokePLTR_a_LongAccel, operation=PokePLTR_a_LongAccel.PokePLTR_a_LongAccel
        Event_PokePLTR_a_LongAccelOffset: start-on-event=PokePLTR_a_LongAccelOffset, operation=PokePLTR_a_LongAccelOffset.PokePLTR_a_LongAccelOffset
        Event_PokePLTR_a_LongAccel_ORC: start-on-event=PokePLTR_a_LongAccel_ORC, operation=PokePLTR_a_LongAccel_ORC.PokePLTR_a_LongAccel_ORC
        Event_PokePLTR_a_TransAccel: start-on-event=PokePLTR_a_TransAccel, operation=PokePLTR_a_TransAccel.PokePLTR_a_TransAccel
        Event_PokePLTR_a_TransAccelOffset: start-on-event=PokePLTR_a_TransAccelOffset, operation=PokePLTR_a_TransAccelOffset.PokePLTR_a_TransAccelOffset
        Event_PokePLTR_b_ACCEnbld: start-on-event=PokePLTR_b_ACCEnbld, operation=PokePLTR_b_ACCEnbld.PokePLTR_b_ACCEnbld
        Event_PokePLTR_b_ACC_On: start-on-event=PokePLTR_b_ACC_On, operation=PokePLTR_b_ACC_On.PokePLTR_b_ACC_On
        Event_PokePLTR_b_ASCM_Srv: start-on-event=PokePLTR_b_ASCM_Srv, operation=PokePLTR_b_ASCM_Srv.PokePLTR_b_ASCM_Srv
        Event_PokePLTR_b_ASCM_SysFail: start-on-event=PokePLTR_b_ASCM_SysFail, operation=PokePLTR_b_ASCM_SysFail.PokePLTR_b_ASCM_SysFail
        Event_PokePLTR_b_ASCM_SysSys: start-on-event=PokePLTR_b_ASCM_SysSys, operation=PokePLTR_b_ASCM_SysSys.PokePLTR_b_ASCM_SysSys
        Event_PokePLTR_b_CC_Type: start-on-event=PokePLTR_b_CC_Type, operation=PokePLTR_b_CC_Type.PokePLTR_b_CC_Type
        Event_PokePLTR_b_ChargeReq: start-on-event=PokePLTR_b_ChargeReq, operation=PokePLTR_b_ChargeReq.PokePLTR_b_ChargeReq
        Event_PokePLTR_b_CrsCntrlActv: start-on-event=PokePLTR_b_CrsCntrlActv, operation=PokePLTR_b_CrsCntrlActv.PokePLTR_b_CrsCntrlActv
        Event_PokePLTR_b_DoorFailSts: start-on-event=PokePLTR_b_DoorFailSts, operation=PokePLTR_b_DoorFailSts.PokePLTR_b_DoorFailSts
        Event_PokePLTR_b_DriverSeatBeltSts: start-on-event=PokePLTR_b_DriverSeatBeltSts, operation=PokePLTR_b_DriverSeatBeltSts.PokePLTR_b_DriverSeatBeltSts
        Event_PokePLTR_b_DrvDrAjar: start-on-event=PokePLTR_b_DrvDrAjar, operation=PokePLTR_b_DrvDrAjar.PokePLTR_b_DrvDrAjar
        Event_PokePLTR_b_DrvrSeatSnsrFailSts: start-on-event=PokePLTR_b_DrvrSeatSnsrFailSts, operation=PokePLTR_b_DrvrSeatSnsrFailSts.PokePLTR_b_DrvrSeatSnsrFailSts
        Event_PokePLTR_b_EPBFailSts: start-on-event=PokePLTR_b_EPBFailSts, operation=PokePLTR_b_EPBFailSts.PokePLTR_b_EPBFailSts
        Event_PokePLTR_b_ESSActvEBrake: start-on-event=PokePLTR_b_ESSActvEBrake, operation=PokePLTR_b_ESSActvEBrake.PokePLTR_b_ESSActvEBrake
        Event_PokePLTR_b_ESSRqShftPark: start-on-event=PokePLTR_b_ESSRqShftPark, operation=PokePLTR_b_ESSRqShftPark.PokePLTR_b_ESSRqShftPark
        Event_PokePLTR_b_FuelLevelLowClster: start-on-event=PokePLTR_b_FuelLevelLowClster, operation=PokePLTR_b_FuelLevelLowClster.PokePLTR_b_FuelLevelLowClster
        Event_PokePLTR_b_HDCEnabledCAN: start-on-event=PokePLTR_b_HDCEnabledCAN, operation=PokePLTR_b_HDCEnabledCAN.PokePLTR_b_HDCEnabledCAN
        Event_PokePLTR_b_HotEnablerReq: start-on-event=PokePLTR_b_HotEnablerReq, operation=PokePLTR_b_HotEnablerReq.PokePLTR_b_HotEnablerReq
        Event_PokePLTR_b_ImmoParkReq: start-on-event=PokePLTR_b_ImmoParkReq, operation=PokePLTR_b_ImmoParkReq.PokePLTR_b_ImmoParkReq
        Event_PokePLTR_b_InPlantAllowCharge: start-on-event=PokePLTR_b_InPlantAllowCharge, operation=PokePLTR_b_InPlantAllowCharge.PokePLTR_b_InPlantAllowCharge
        Event_PokePLTR_b_InternalLightSts: start-on-event=PokePLTR_b_InternalLightSts, operation=PokePLTR_b_InternalLightSts.PokePLTR_b_InternalLightSts
        Event_PokePLTR_b_LHRDoorSts: start-on-event=PokePLTR_b_LHRDoorSts, operation=PokePLTR_b_LHRDoorSts.PokePLTR_b_LHRDoorSts
        Event_PokePLTR_b_LatAccelFailSts_ORC: start-on-event=PokePLTR_b_LatAccelFailSts_ORC, operation=PokePLTR_b_LatAccelFailSts_ORC.PokePLTR_b_LatAccelFailSts_ORC
        Event_PokePLTR_b_LongAccelFailSts_ORC: start-on-event=PokePLTR_b_LongAccelFailSts_ORC, operation=PokePLTR_b_LongAccelFailSts_ORC.PokePLTR_b_LongAccelFailSts_ORC
        Event_PokePLTR_b_MILOnRq_ESC: start-on-event=PokePLTR_b_MILOnRq_ESC, operation=PokePLTR_b_MILOnRq_ESC.PokePLTR_b_MILOnRq_ESC
        Event_PokePLTR_b_ParkBrakeSts: start-on-event=PokePLTR_b_ParkBrakeSts, operation=PokePLTR_b_ParkBrakeSts.PokePLTR_b_ParkBrakeSts
        Event_PokePLTR_b_Prmry_ManualMode: start-on-event=PokePLTR_b_Prmry_ManualMode, operation=PokePLTR_b_Prmry_ManualMode.PokePLTR_b_Prmry_ManualMode
        Event_PokePLTR_b_Prmry_PRNDFailSts: start-on-event=PokePLTR_b_Prmry_PRNDFailSts, operation=PokePLTR_b_Prmry_PRNDFailSts.PokePLTR_b_Prmry_PRNDFailSts
        Event_PokePLTR_b_Prmry_RFHub_ForcePark: start-on-event=PokePLTR_b_Prmry_RFHub_ForcePark, operation=PokePLTR_b_Prmry_RFHub_ForcePark.PokePLTR_b_Prmry_RFHub_ForcePark
        Event_PokePLTR_b_Prmry_RackDetentSensorFA: start-on-event=PokePLTR_b_Prmry_RackDetentSensorFA, operation=PokePLTR_b_Prmry_RackDetentSensorFA.PokePLTR_b_Prmry_RackDetentSensorFA
        Event_PokePLTR_b_Prmry_ShiftLeverFailSts: start-on-event=PokePLTR_b_Prmry_ShiftLeverFailSts, operation=PokePLTR_b_Prmry_ShiftLeverFailSts.PokePLTR_b_Prmry_ShiftLeverFailSts
        Event_PokePLTR_b_Prmry_ShiftLockFA: start-on-event=PokePLTR_b_Prmry_ShiftLockFA, operation=PokePLTR_b_Prmry_ShiftLockFA.PokePLTR_b_Prmry_ShiftLockFA
        Event_PokePLTR_b_Prmry_ShiftSnsFA: start-on-event=PokePLTR_b_Prmry_ShiftSnsFA, operation=PokePLTR_b_Prmry_ShiftSnsFA.PokePLTR_b_Prmry_ShiftSnsFA
        Event_PokePLTR_b_Prmry_ShifterDispFA: start-on-event=PokePLTR_b_Prmry_ShifterDispFA, operation=PokePLTR_b_Prmry_ShifterDispFA.PokePLTR_b_Prmry_ShifterDispFA
        Event_PokePLTR_b_PsngrDoorSts: start-on-event=PokePLTR_b_PsngrDoorSts, operation=PokePLTR_b_PsngrDoorSts.PokePLTR_b_PsngrDoorSts
        Event_PokePLTR_b_RHRDoorSts: start-on-event=PokePLTR_b_RHRDoorSts, operation=PokePLTR_b_RHRDoorSts.PokePLTR_b_RHRDoorSts
        Event_PokePLTR_b_RHatchSts: start-on-event=PokePLTR_b_RHatchSts, operation=PokePLTR_b_RHatchSts.PokePLTR_b_RHatchSts
        Event_PokePLTR_b_RearFogLightSts: start-on-event=PokePLTR_b_RearFogLightSts, operation=PokePLTR_b_RearFogLightSts.PokePLTR_b_RearFogLightSts
        Event_PokePLTR_b_RmtVehStartReq: start-on-event=PokePLTR_b_RmtVehStartReq, operation=PokePLTR_b_RmtVehStartReq.PokePLTR_b_RmtVehStartReq
        Event_PokePLTR_b_Scndry_PRNDFailSts: start-on-event=PokePLTR_b_Scndry_PRNDFailSts, operation=PokePLTR_b_Scndry_PRNDFailSts.PokePLTR_b_Scndry_PRNDFailSts
        Event_PokePLTR_b_Scndry_RFHub_ForcePark: start-on-event=PokePLTR_b_Scndry_RFHub_ForcePark, operation=PokePLTR_b_Scndry_RFHub_ForcePark.PokePLTR_b_Scndry_RFHub_ForcePark
        Event_PokePLTR_b_Scndry_RackDetentSensorFA: start-on-event=PokePLTR_b_Scndry_RackDetentSensorFA, operation=PokePLTR_b_Scndry_RackDetentSensorFA.PokePLTR_b_Scndry_RackDetentSensorFA
        Event_PokePLTR_b_Scndry_ShiftLeverFailSts: start-on-event=PokePLTR_b_Scndry_ShiftLeverFailSts, operation=PokePLTR_b_Scndry_ShiftLeverFailSts.PokePLTR_b_Scndry_ShiftLeverFailSts
        Event_PokePLTR_b_Scndry_ShiftLockFA: start-on-event=PokePLTR_b_Scndry_ShiftLockFA, operation=PokePLTR_b_Scndry_ShiftLockFA.PokePLTR_b_Scndry_ShiftLockFA
        Event_PokePLTR_b_Scndry_ShiftSnsFA: start-on-event=PokePLTR_b_Scndry_ShiftSnsFA, operation=PokePLTR_b_Scndry_ShiftSnsFA.PokePLTR_b_Scndry_ShiftSnsFA
        Event_PokePLTR_b_Scndry_ShifterDispFA: start-on-event=PokePLTR_b_Scndry_ShifterDispFA, operation=PokePLTR_b_Scndry_ShifterDispFA.PokePLTR_b_Scndry_ShifterDispFA
        Event_PokePLTR_b_Secure_Idle_Req: start-on-event=PokePLTR_b_Secure_Idle_Req, operation=PokePLTR_b_Secure_Idle_Req.PokePLTR_b_Secure_Idle_Req
        Event_PokePLTR_b_SpeedUnit: start-on-event=PokePLTR_b_SpeedUnit, operation=PokePLTR_b_SpeedUnit.PokePLTR_b_SpeedUnit
        Event_PokePLTR_b_Worksite_Inverter_Active: start-on-event=PokePLTR_b_Worksite_Inverter_Active, operation=PokePLTR_b_Worksite_Inverter_Active.PokePLTR_b_Worksite_Inverter_Active
        Event_PokePLTR_b_YawRateFailSts_ORC: start-on-event=PokePLTR_b_YawRateFailSts_ORC, operation=PokePLTR_b_YawRateFailSts_ORC.PokePLTR_b_YawRateFailSts_ORC
        Event_PokePLTR_dphi_LwsSpeed: start-on-event=PokePLTR_dphi_LwsSpeed, operation=PokePLTR_dphi_LwsSpeed.PokePLTR_dphi_LwsSpeed
        Event_PokePLTR_dphi_YawRate_ORC: start-on-event=PokePLTR_dphi_YawRate_ORC, operation=PokePLTR_dphi_YawRate_ORC.PokePLTR_dphi_YawRate_ORC
        Event_PokePLTR_e_ACCSystemSts: start-on-event=PokePLTR_e_ACCSystemSts, operation=PokePLTR_e_ACCSystemSts.PokePLTR_e_ACCSystemSts
        Event_PokePLTR_e_AEBSystemSts: start-on-event=PokePLTR_e_AEBSystemSts, operation=PokePLTR_e_AEBSystemSts.PokePLTR_e_AEBSystemSts
        Event_PokePLTR_e_ASCM_Stat: start-on-event=PokePLTR_e_ASCM_Stat, operation=PokePLTR_e_ASCM_Stat.PokePLTR_e_ASCM_Stat
        Event_PokePLTR_e_BSM_AxleTrq_Enbld: start-on-event=PokePLTR_e_BSM_AxleTrq_Enbld, operation=PokePLTR_e_BSM_AxleTrq_Enbld.PokePLTR_e_BSM_AxleTrq_Enbld
        Event_PokePLTR_e_Command_15Sts: start-on-event=PokePLTR_e_Command_15Sts, operation=PokePLTR_e_Command_15Sts.PokePLTR_e_Command_15Sts
        Event_PokePLTR_e_DriverDoorOnOffSts: start-on-event=PokePLTR_e_DriverDoorOnOffSts, operation=PokePLTR_e_DriverDoorOnOffSts.PokePLTR_e_DriverDoorOnOffSts
        Event_PokePLTR_e_DrvrSeatSnsrSts: start-on-event=PokePLTR_e_DrvrSeatSnsrSts, operation=PokePLTR_e_DrvrSeatSnsrSts.PokePLTR_e_DrvrSeatSnsrSts
        Event_PokePLTR_e_ECMVtdFreeze: start-on-event=PokePLTR_e_ECMVtdFreeze, operation=PokePLTR_e_ECMVtdFreeze.PokePLTR_e_ECMVtdFreeze
        Event_PokePLTR_e_EPBHoldSt: start-on-event=PokePLTR_e_EPBHoldSt, operation=PokePLTR_e_EPBHoldSt.PokePLTR_e_EPBHoldSt
        Event_PokePLTR_e_ERS_SW: start-on-event=PokePLTR_e_ERS_SW, operation=PokePLTR_e_ERS_SW.PokePLTR_e_ERS_SW
        Event_PokePLTR_e_GatedParkSw_FaultSts: start-on-event=PokePLTR_e_GatedParkSw_FaultSts, operation=PokePLTR_e_GatedParkSw_FaultSts.PokePLTR_e_GatedParkSw_FaultSts
        Event_PokePLTR_e_HAS_TelltaleSts: start-on-event=PokePLTR_e_HAS_TelltaleSts, operation=PokePLTR_e_HAS_TelltaleSts.PokePLTR_e_HAS_TelltaleSts
        Event_PokePLTR_e_HiBmLvr_Stat: start-on-event=PokePLTR_e_HiBmLvr_Stat, operation=PokePLTR_e_HiBmLvr_Stat.PokePLTR_e_HiBmLvr_Stat
        Event_PokePLTR_e_InvrOprStatus: start-on-event=PokePLTR_e_InvrOprStatus, operation=PokePLTR_e_InvrOprStatus.PokePLTR_e_InvrOprStatus
        Event_PokePLTR_e_LSMDExtReleaseLockReq: start-on-event=PokePLTR_e_LSMDExtReleaseLockReq, operation=PokePLTR_e_LSMDExtReleaseLockReq.PokePLTR_e_LSMDExtReleaseLockReq
        Event_PokePLTR_e_LwsAngleType: start-on-event=PokePLTR_e_LwsAngleType, operation=PokePLTR_e_LwsAngleType.PokePLTR_e_LwsAngleType
        Event_PokePLTR_e_MRM_Status: start-on-event=PokePLTR_e_MRM_Status, operation=PokePLTR_e_MRM_Status.PokePLTR_e_MRM_Status
        Event_PokePLTR_e_MRM_Status_C2: start-on-event=PokePLTR_e_MRM_Status_C2, operation=PokePLTR_e_MRM_Status_C2.PokePLTR_e_MRM_Status_C2
        Event_PokePLTR_e_ParkingGearShiftReq_BSM: start-on-event=PokePLTR_e_ParkingGearShiftReq_BSM, operation=PokePLTR_e_ParkingGearShiftReq_BSM.PokePLTR_e_ParkingGearShiftReq_BSM
        Event_PokePLTR_e_Prmry_AutoPosCorrMd: start-on-event=PokePLTR_e_Prmry_AutoPosCorrMd, operation=PokePLTR_e_Prmry_AutoPosCorrMd.PokePLTR_e_Prmry_AutoPosCorrMd
        Event_PokePLTR_e_Prmry_PRND_ValidatePstn: start-on-event=PokePLTR_e_Prmry_PRND_ValidatePstn, operation=PokePLTR_e_Prmry_PRND_ValidatePstn.PokePLTR_e_Prmry_PRND_ValidatePstn
        Event_PokePLTR_e_Prmry_ShiftLeverPositionReq: start-on-event=PokePLTR_e_Prmry_ShiftLeverPositionReq, operation=PokePLTR_e_Prmry_ShiftLeverPositionReq.PokePLTR_e_Prmry_ShiftLeverPositionReq
        Event_PokePLTR_e_Prmry_TransShiftPstn: start-on-event=PokePLTR_e_Prmry_TransShiftPstn, operation=PokePLTR_e_Prmry_TransShiftPstn.PokePLTR_e_Prmry_TransShiftPstn
        Event_PokePLTR_e_Scndry_AutoPosCorrMd: start-on-event=PokePLTR_e_Scndry_AutoPosCorrMd, operation=PokePLTR_e_Scndry_AutoPosCorrMd.PokePLTR_e_Scndry_AutoPosCorrMd
        Event_PokePLTR_e_Scndry_PRND_ValidatePstn: start-on-event=PokePLTR_e_Scndry_PRND_ValidatePstn, operation=PokePLTR_e_Scndry_PRND_ValidatePstn.PokePLTR_e_Scndry_PRND_ValidatePstn
        Event_PokePLTR_e_Scndry_ShiftLeverPositionReq: start-on-event=PokePLTR_e_Scndry_ShiftLeverPositionReq, operation=PokePLTR_e_Scndry_ShiftLeverPositionReq.PokePLTR_e_Scndry_ShiftLeverPositionReq
        Event_PokePLTR_e_Scndry_TransShiftPstn: start-on-event=PokePLTR_e_Scndry_TransShiftPstn, operation=PokePLTR_e_Scndry_TransShiftPstn.PokePLTR_e_Scndry_TransShiftPstn
        Event_PokePLTR_e_SelectSpdSts: start-on-event=PokePLTR_e_SelectSpdSts, operation=PokePLTR_e_SelectSpdSts.PokePLTR_e_SelectSpdSts
        Event_PokePLTR_e_ShipingMode: start-on-event=PokePLTR_e_ShipingMode, operation=PokePLTR_e_ShipingMode.PokePLTR_e_ShipingMode
        Event_PokePLTR_e_TowHaulMode: start-on-event=PokePLTR_e_TowHaulMode, operation=PokePLTR_e_TowHaulMode.PokePLTR_e_TowHaulMode
        Event_PokePLTR_e_V2GOprStat: start-on-event=PokePLTR_e_V2GOprStat, operation=PokePLTR_e_V2GOprStat.PokePLTR_e_V2GOprStat
        Event_PokePLTR_e_VehCfgSt: start-on-event=PokePLTR_e_VehCfgSt, operation=PokePLTR_e_VehCfgSt.PokePLTR_e_VehCfgSt
        Event_PokePLTR_e_Worksite_Inverter_Sts: start-on-event=PokePLTR_e_Worksite_Inverter_Sts, operation=PokePLTR_e_Worksite_Inverter_Sts.PokePLTR_e_Worksite_Inverter_Sts
        Event_PokePLTR_e_eBurn_Stages: start-on-event=PokePLTR_e_eBurn_Stages, operation=PokePLTR_e_eBurn_Stages.PokePLTR_e_eBurn_Stages
        Event_PokePLTR_l_Odometer_Km: start-on-event=PokePLTR_l_Odometer_Km, operation=PokePLTR_l_Odometer_Km.PokePLTR_l_Odometer_Km
        Event_PokePLTR_l_TravelDistance: start-on-event=PokePLTR_l_TravelDistance, operation=PokePLTR_l_TravelDistance.PokePLTR_l_TravelDistance
        Event_PokePLTR_p_AmbientAirPrs: start-on-event=PokePLTR_p_AmbientAirPrs, operation=PokePLTR_p_AmbientAirPrs.PokePLTR_p_AmbientAirPrs
        Event_PokePLTR_phi_LwsAngle: start-on-event=PokePLTR_phi_LwsAngle, operation=PokePLTR_phi_LwsAngle.PokePLTR_phi_LwsAngle
        Event_PokePLTR_t_GPS_UTC_Second: start-on-event=PokePLTR_t_GPS_UTC_Second, operation=PokePLTR_t_GPS_UTC_Second.PokePLTR_t_GPS_UTC_Second
        Event_PokePLTR_tdy_GPS_Date_Day: start-on-event=PokePLTR_tdy_GPS_Date_Day, operation=PokePLTR_tdy_GPS_Date_Day.PokePLTR_tdy_GPS_Date_Day
        Event_PokePLTR_thr_GPS_UTC_Hour: start-on-event=PokePLTR_thr_GPS_UTC_Hour, operation=PokePLTR_thr_GPS_UTC_Hour.PokePLTR_thr_GPS_UTC_Hour
        Event_PokePLTR_tmn_GPS_UTC_Minute: start-on-event=PokePLTR_tmn_GPS_UTC_Minute, operation=PokePLTR_tmn_GPS_UTC_Minute.PokePLTR_tmn_GPS_UTC_Minute
        Event_PokePLTR_tmt_GPS_Date_Month: start-on-event=PokePLTR_tmt_GPS_Date_Month, operation=PokePLTR_tmt_GPS_Date_Month.PokePLTR_tmt_GPS_Date_Month
        Event_PokePLTR_tyr_GPS_Date_Year: start-on-event=PokePLTR_tyr_GPS_Date_Year, operation=PokePLTR_tyr_GPS_Date_Year.PokePLTR_tyr_GPS_Date_Year
        Event_PokePLTR_y_AUD_LVL: start-on-event=PokePLTR_y_AUD_LVL, operation=PokePLTR_y_AUD_LVL.PokePLTR_y_AUD_LVL
        Event_PokePLTR_y_FobSearchResult: start-on-event=PokePLTR_y_FobSearchResult, operation=PokePLTR_y_FobSearchResult.PokePLTR_y_FobSearchResult
        Event_TmotPLTR_b_ChargeReq: start-on-event=TmotPLTR_b_ChargeReq, operation=TmotPLTR_b_ChargeReq.TmotPLTR_b_ChargeReq
      init event Event_PLTR_ac_Init: start-on-event=PLTR_ac_Init
      init event Event_PwrOn: start-on-event=PLTR_PwrOn
      init event Event_PwrOff: start-on-event=PLTR_PwrOff
      4 x data received event:
        Event_DidWrite_RWD9E3B_IPEETstMilgeLmt: start-on-event=DidWrite_RWD9E3B_IPEETstMilgeLmt, data=VeDCAB_milel_RWD9E3B_IPEETstMilgeLmt.Value
        Event_DidWrite_RWD3025_HCPModEnblr_PLTR: start-on-event=DidWrite_RWD3025_HCPModEnblr_PLTR, data=VeDCAB_b_RWD3025_InFieldMode.Value
        Event_DidWrite_RWD9EEB_InPlant_SOC_Setpoint: start-on-event=DidWrite_RWD9EEB_InPlant_SOC_Setpoint, data=VeDCAB_Pct_RWD9EEB_InPlant_SOC_Setpoint.Value
        Event_DidWrite_RWD9EEC_REM_Logistics_SOC_Setpoint: start-on-event=DidWrite_RWD9EEC_REM_Logistics_SOC_Setpoint, data=VeDCAB_Pct_RWD9EEC_REM_Logistics_SOC_Setpoint.Value
      explicit-inter-runnable-variables:
        83 x data, all with category=VALUE, sw-calibration-access=READ-ONLY:
          VePLTR_a_LongAccel_write_IRV: type=Float, init-value=0
          VePLTR_a_LongAccelOffset_write_IRV: type=Float, init-value=0
          VePLTR_a_TransAccel_write_IRV: type=Float, init-value=0
          VePLTR_a_TransAccelOffset_write_IRV: type=Float, init-value=0
          VePLTR_b_LongAccelFA_write_IRV: type=Boolean, init-value=0
          VePLTR_b_LongAccelOffsetFA_write_IRV: type=Boolean, init-value=0
          VePLTR_b_TransAccelFA_write_IRV: type=Boolean, init-value=0
          VePLTR_b_TransAccelOffsetFA_write_IRV: type=Boolean, init-value=0
          VehSpd_write_IRV: type=Float, init-value=0
          OutTorqReqModHH_write_IRV: type=Float, init-value=0
          VePLTR_b_CrsCntrlActv_write_IRV: type=Boolean, init-value=0
          VePLTR_b_ACCEnbledInit_write_IRV: type=Boolean, init-value=0
          VePLTR_b_SpeedUnit_Init_write_IRV: type=Boolean, init-value=0
          TransShiftPosInitMSG_write_IRV: type=TeTRGR_e_TransRangeState, init-value=CeTRGR_e_NoSelectionAvailable
          VePLTR_b_Prmry_TransShiftPstnFA_write_IRV: type=Boolean, init-value=0
          AutoPosCorrMd_Init_write_IRV: type=TeTRGR_e_AutoPosCorrMd, init-value=CeTRGR_e_AutoPosCorrMd_Off
          VePLTR_b_Prmry_AutoPosCorrMdFA_write_IRV: type=Boolean, init-value=0
          VePLTR_b_Prmry_ShifterDispFAFA_write_IRV: type=Boolean, init-value=0
          VePLTR_b_Prmry_ShiftLockFAFA_write_IRV: type=Boolean, init-value=0
          VePLTR_b_Prmry_ShiftSnsFAFA_write_IRV: type=Boolean, init-value=0
          VePLTR_b_Prmry_RackDetentSensorFAFA_write_IRV: type=Boolean, init-value=0
          TransShiftPos_InitMSG_write_IRV: type=TeTRGR_e_TransRangeState, init-value=CeTRGR_e_NoSelectionAvailable
          VePLTR_b_Scndry_TransShiftPstnFA_write_IRV: type=Boolean, init-value=0
          AutoPosCorrMd_Ini_write_IRV: type=TeTRGR_e_AutoPosCorrMd, init-value=CeTRGR_e_AutoPosCorrMd_Off
          VePLTR_b_Scndry_AutoPosCorrMdFA_write_IRV: type=Boolean, init-value=0
          VePLTR_b_Scndry_ShifterDispFAFA_write_IRV: type=Boolean, init-value=0
          VePLTR_b_Scndry_ShiftLockFAFA_write_IRV: type=Boolean, init-value=0
          VePLTR_b_Scndry_ShiftSnsFAFA_write_IRV: type=Boolean, init-value=0
          VePLTR_b_Scndry_RackDetentSensorFAFA_write_IRV: type=Boolean, init-value=0
          HWIO_GatedParkSWFault_write_IRV: type=SInt16, init-value=0
          ShiftLeverPositionReq_Init_write_IRV: type=TeTRGR_e_TransRangeState, init-value=CeTRGR_e_NoSelectionAvailable
          VePLTR_b_Prmry_ShiftLeverPositionReqFA_write_IRV: type=Boolean, init-value=0
          VePLTR_b_Prmry_ShiftLeverFailStsFA_write_IRV: type=Boolean, init-value=0
          VePLTR_b_Prmry_PRNDFailStsFA_write_IRV: type=Boolean, init-value=0
          ShiftLeverPositionReq_Ini_write_IRV: type=TeTRGR_e_TransRangeState, init-value=CeTRGR_e_NoSelectionAvailable
          VePLTR_b_Scndry_ShiftLeverPositionReqFA_write_IRV: type=Boolean, init-value=0
          VePLTR_b_Scndry_ShiftLeverFailStsFA_write_IRV: type=Boolean, init-value=0
          VePLTR_b_Scndry_PRNDFailStsFA_write_IRV: type=Boolean, init-value=0
          RFHub_ForcePark_Init_write_IRV: type=Boolean, init-value=0
          VePLTR_b_Prmry_ForceParkFA_write_IRV: type=Boolean, init-value=0
          RFHUB_ForcePark_Init_PwrOn_1_IRV_IRV: type=Boolean, init-value=0
          VePLTR_b_Scndry_ForceParkFA_write_IRV: type=Boolean, init-value=0
          ManualMode_Init_write_IRV: type=Boolean, init-value=0
          VePLTR_b_Prmry_ManualModeFA_write_IRV: type=Boolean, init-value=0
          PRND_ValidatePstn_Init_write_IRV: type=TeTRGR_e_TransRangeState, init-value=CeTRGR_e_NoSelectionAvailable
          VePLTR_b_Prmry_PRND_ValidatePstnFA_write_IRV: type=Boolean, init-value=0
          PRND_ValidatePstn_InitSndry_write_IRV: type=TeTRGR_e_TransRangeState, init-value=CeTRGR_e_NoSelectionAvailable
          VePLTR_b_Scndry_PRND_ValidatePstnFA_write_IRV: type=Boolean, init-value=0
          VePLTR_b_DrvDrAjar_write_IRV: type=Boolean, init-value=0
          VePLTR_b_DoorFailSts_Init_write_IRV: type=Boolean, init-value=0
          VePLTR_e_DriverSeatBeltSts_write_IRV: type=TePLTR_e_DRV_SEATBELT, init-value=CePLTR_e_DRV_SEATBELT_OK
          VePLTR_b_DriverSeatBeltStsFA_write_IRV: type=Boolean, init-value=0
          DrvrSeatSnsrSts_Init_write_IRV: type=TePLTR_e_DrvrSeatSnsrSts, init-value=CePLTR_e_DrvrSeatSnsrSts_Init
          VePLTR_b_DrvrSeatSnsrSts_FA_write_IRV: type=Boolean, init-value=0
          DrvrSeatSnsr_FailSts_Init_write_IRV: type=Boolean, init-value=0
          DriverDetected_write_IRV: type=Boolean, init-value=0
          VePLTR_e_DriverDoorOnOffSts_Init_IRV: type=TePLTR_e_DrvrDoorOnOffSts, init-value=CePLTR_e_DOOR_ON
          VePLTR_b_DriverDoorOnOffSts_FA_IRV: type=Boolean, init-value=0
          Toggle_1s_write_IRV: type=Boolean, init-value=0
          VePLTR_p_AmbientAirPrs_write_IRV: type=Float, init-value=0
          VePLTR_e_RTCTestSyncReport_Init_IRV: type=TePLTR_e_RTCSyncDiagTestReport, init-value=CePLTR_e_RTCSyncDiag_NotTested
          HVBatRealTimeClock_BPCM_write_IRV: type=UInt32, init-value=0
          HVBatRealTimeClock_FA_BPCM_write_IRV: type=Boolean, init-value=0
          HVBatSleepTime_BPCM_write_IRV: type=UInt32, init-value=0
          VePLTR_e_ECMVtdFreezeInit_write_IRV: type=TePLTR_e_ECMVtdFreeze, init-value=CePLTR_e_NoReset
          VePLTI_kl_Odometer_Km_write_IRV: type=Float, init-value=0
          VePLTI_e_ShippingMode_write_IRV: type=TePLTR_e_ShipingMode, init-value=CePLTR_e_ShipingMode_CUST_MD
          FuelLevelLowClster_Init_write_IRV: type=Boolean, init-value=0
          VePLTR_tdy_GPS_Date_Day_PwrOn_IRV: type=Float, init-value=0
          VePLTR_tmt_GPS_Date_Month_PwrOn_IRV: type=Float, init-value=0
          VePLTR_tyr_GPS_Date_Year_PwrOn_IRV: type=Float, init-value=0
          VePLTR_thr_GPS_UTC_Hour_PwrOn_IRV: type=Float, init-value=0
          VePLTR_tmn_GPS_UTC_Minute_PwrOn_IRV: type=Float, init-value=0
          VePLTR_t_GPS_UTC_Second_PwrOn_IRV: type=Float, init-value=0
          VePLTR_b_GPS_Date_DayFA_write_IRV: type=Boolean, init-value=0
          VePLTR_b_GPS_Date_MonthFA_write_IRV: type=Boolean, init-value=0
          VePLTR_b_GPS_Date_YearFA_write_IRV: type=Boolean, init-value=0
          VePLTR_b_GPS_UTC_HourFA_write_IRV: type=Boolean, init-value=0
          VePLTR_b_GPS_UTC_MinuteFA_write_IRV: type=Boolean, init-value=0
          VePLTR_b_GPS_UTC_SecondFA_write_IRV: type=Boolean, init-value=0
          VePLTR_b_RTCFltDtctd_IRV: type=Boolean, init-value=0
          VePLTR_b_BatteryWasDisconnected_Init_write_IRV: type=Boolean, init-value=0
          VePLTI_b_RTC_CurrentTimeFA_Init_write_IRV: type=Boolean, init-value=0
      200 x runnable:
        PLTR_ac_Init
          data-send-points:
            42 x access:
              OUT_VePLTR_b_ResetFlagRecent_EEerror_Value: accessed-variable=VePLTR_b_ResetFlagRecent_EEerror.Value
              OUT_VePLTR_e_ERS_SW_Value: accessed-variable=VePLTR_e_ERS_SW.Value
              OUT_VePLTR_e_TowHaulMode_Value: accessed-variable=VePLTR_e_TowHaulMode.Value
              OUT_VePLTR_e_InvOprStat_Value: accessed-variable=VePLTR_e_InvOprStat.Value
              OUT_VePLTR_e_V2GOprStat_Value: accessed-variable=VePLTR_e_V2GOprStat.Value
              OUT_VePLTR_e_EPBHoldSts_Value: accessed-variable=VePLTR_e_EPBHoldSts.Value
              OUT_VePLTR_e_VehicleCountryCode_Value: accessed-variable=VePLTR_e_VehicleCountryCode.Value
              OUT_VePLTR_e_ShippingMode_Value: accessed-variable=VePLTR_e_ShippingMode.Value
              OUT_VePLTR_e_ShiftIndSt_Value: accessed-variable=VePLTR_e_ShiftIndSt.Value
              OUT_VePLTR_e_VehCfgSt_Value: accessed-variable=VePLTR_e_VehCfgSt.Value
              OUT_VePLTR_e_ProxiACC_Value: accessed-variable=VePLTR_e_ProxiACC.Value
              OUT_VePLTR_e_ProxiIncreasingSpdCnst_Value: accessed-variable=VePLTR_e_ProxiIncreasingSpdCnst.Value
              OUT_VePLTR_e_ACCSystemSts_Value: accessed-variable=VePLTR_e_ACCSystemSts.Value
              OUT_VePLTR_e_Prmry_TransShiftPstn_Value: accessed-variable=VePLTR_e_Prmry_TransShiftPstn.Value
              OUT_VePLTR_e_ESMTransRngSt_Value: accessed-variable=VePLTR_e_ESMTransRngSt.Value
              OUT_VePLTR_e_AutoPosCorrMd_Value: accessed-variable=VePLTR_e_AutoPosCorrMd.Value
              OUT_VePLTR_e_ShiftLeverPosReq_Value: accessed-variable=VePLTR_e_ShiftLeverPosReq.Value
              OUT_VePLTR_e_Scndry_TransShiftPstn_Value: accessed-variable=VePLTR_e_Scndry_TransShiftPstn.Value
              OUT_VePLTR_e_RationalisedRngSt_Value: accessed-variable=VePLTR_e_RationalisedRngSt.Value
              OUT_VePLTR_e_ValidatePstn_Value: accessed-variable=VePLTR_e_ValidatePstn.Value
              OUT_VePLTR_e_ProxyHybridType_Value: accessed-variable=VePLTR_e_ProxyHybridType.Value
              OUT_VePLTR_e_Proxi_Autonomy_Lvl_Value: accessed-variable=VePLTR_e_Proxi_Autonomy_Lvl.Value
              OUT_VePLTR_e_Proxi_CC_Logic_Value: accessed-variable=VePLTR_e_Proxi_CC_Logic.Value
              OUT_VePLTR_e_MRM_Status_Value: accessed-variable=VePLTR_e_MRM_Status.Value
              OUT_VePLTR_e_LSMDExtReleaseLockReq_Value: accessed-variable=VePLTR_e_LSMDExtReleaseLockReq.Value
              OUT_VePLTR_e_VehCategory_Value: accessed-variable=VePLTR_e_VehCategory.Value
              OUT_VePLTR_e_LwsAngleType_Value: accessed-variable=VePLTR_e_LwsAngleType.Value
              OUT_VePLTR_e_MRM_Status_C2_Value: accessed-variable=VePLTR_e_MRM_Status_C2.Value
              OUT_VePLTR_e_Worksite_Inverter_Sts_Value: accessed-variable=VePLTR_e_Worksite_Inverter_Sts.Value
              OUT_VePLTR_e_BSM_AxleTrq_Enbld_Value: accessed-variable=VePLTR_e_BSM_AxleTrq_Enbld.Value
              OUT_VePLTR_e_FaultSts_ECUInplantmodeAct_Value: accessed-variable=VePLTR_e_FaultSts_ECUInplantmodeAct.Value
              OUT_VePLTR_e_HAS_TelltaleSts_Value: accessed-variable=VePLTR_e_HAS_TelltaleSts.Value
              OUT_VePLTR_e_AEBSystemSts_Value: accessed-variable=VePLTR_e_AEBSystemSts.Value
              OUT_VePLTR_e_Command_15Sts_Value: accessed-variable=VePLTR_e_Command_15Sts.Value
              OUT_VePLTR_e_eBurn_Stages_Value: accessed-variable=VePLTR_e_eBurn_Stages.Value
              OUT_VePLTR_e_FaultSts_IgnKeyOffTmrPerfTooFast_Value: accessed-variable=VePLTR_e_FaultSts_IgnKeyOffTmrPerfTooFast.Value
              OUT_VePLTR_e_SelectSpdSts_Value: accessed-variable=VePLTR_e_SelectSpdSts.Value
              OUT_VePLTR_e_ParkingGearShiftReq_BSM_Value: accessed-variable=VePLTR_e_ParkingGearShiftReq_BSM.Value
              OUT_VePLTR_e_HiBmLvr_Stat_Value: accessed-variable=VePLTR_e_HiBmLvr_Stat.Value
              OUT_VePLTR_e_ASCM_Stat_Value: accessed-variable=VePLTR_e_ASCM_Stat.Value
              OUT_VePLTR_e_DriverSeatBeltSts_Value: accessed-variable=VePLTR_e_DriverSeatBeltSts.Value
              OUT_VePLTR_e_ECMVtdFreeze_Value: accessed-variable=VePLTR_e_ECMVtdFreeze.Value
          written-local-variables:
            access WV_VePLTI_b_RTC_CurrentTimeFA_Init_write_IRV: accessed-variable=VePLTI_b_RTC_CurrentTimeFA_Init_write_IRV
            access WV_VePLTR_b_BatteryWasDisconnected_Init_write_IRV: accessed-variable=VePLTR_b_BatteryWasDisconnected_Init_write_IRV
            access WV_VePLTR_b_RTCFltDtctd_IRV: accessed-variable=VePLTR_b_RTCFltDtctd_IRV
        PLTR_PwrOn
          data-receive-point-by-arguments:
            13 x access:
              IN_AePLTR_Pct_CS_SOCSetPt_Rx_AePLTR_Pct_CS_SOCSetPt: accessed-variable=AePLTR_Pct_CS_SOCSetPt_Rx.AePLTR_Pct_CS_SOCSetPt
              IN_AePLTR_Pct_IP_SOCSetPt_Rx_AePLTR_Pct_IP_SOCSetPt: accessed-variable=AePLTR_Pct_IP_SOCSetPt_Rx.AePLTR_Pct_IP_SOCSetPt
              IN_AePLTR_b_InFieldMode_Rx_AePLTR_b_InFieldMode: accessed-variable=AePLTR_b_InFieldMode_Rx.AePLTR_b_InFieldMode
              IN_AePLTR_b_PwrOffOk_Rx_AePLTR_b_PwrOffOk: accessed-variable=AePLTR_b_PwrOffOk_Rx.AePLTR_b_PwrOffOk
              IN_AePLTR_b_REMDisabled_Rx_AePLTR_b_REMDisabled: accessed-variable=AePLTR_b_REMDisabled_Rx.AePLTR_b_REMDisabled
              IN_AePLTR_b_RadFanHandshake_disbld_Rx_AePLTR_b_RadFanHandshake_disbld: accessed-variable=AePLTR_b_RadFanHandshake_disbld_Rx.AePLTR_b_RadFanHandshake_disbld
              IN_AePLTR_milel_IPEETestMileageLimit_Rx_AePLTR_milel_IPEETestMileageLimit: accessed-variable=AePLTR_milel_IPEETestMileageLimit_Rx.AePLTR_milel_IPEETestMileageLimit
              IN_AePLTR_milel_OdometerLimit_Rx_AePLTR_milel_OdometerLimit: accessed-variable=AePLTR_milel_OdometerLimit_Rx.AePLTR_milel_OdometerLimit
              IN_EePLTR_b_RTC_CurrentTimeFA_Rx_EePLTR_b_RTC_CurrentTimeFA: accessed-variable=EePLTR_b_RTC_CurrentTimeFA_Rx.EePLTR_b_RTC_CurrentTimeFA
              IN_EePLTR_e_RTCStatus_Rx_EePLTR_e_RTCStatus: accessed-variable=EePLTR_e_RTCStatus_Rx.EePLTR_e_RTCStatus
              IN_EePLTR_e_ShippingMode_Rx_EePLTR_e_ShippingMode: accessed-variable=EePLTR_e_ShippingMode_Rx.EePLTR_e_ShippingMode
              IN_EePLTR_t_PowerdownTime_Rx_EePLTR_t_PowerdownTime: accessed-variable=EePLTR_t_PowerdownTime_Rx.EePLTR_t_PowerdownTime
              IN_EePLTR_t_RTCTime_Rx_EePLTR_t_RTCTime: accessed-variable=EePLTR_t_RTCTime_Rx.EePLTR_t_RTCTime
          data-send-points:
            180 x access:
              OUT_VePLTR_W_Inverter_PowerDraw_Value: accessed-variable=VePLTR_W_Inverter_PowerDraw.Value
              OUT_VePLTR_e_TowHaulMode_Value: accessed-variable=VePLTR_e_TowHaulMode.Value
              OUT_VePLTR_b_CC_Type_Value: accessed-variable=VePLTR_b_CC_Type.Value
              OUT_VePLTR_b_ACCSystemSts_FA_Value: accessed-variable=VePLTR_b_ACCSystemSts_FA.Value
              OUT_VePLTR_b_AmbientAirPrsFA_Value: accessed-variable=VePLTR_b_AmbientAirPrsFA.Value
              OUT_VePLTR_b_FuelLevelLowClster_Value: accessed-variable=VePLTR_b_FuelLevelLowClster.Value
              OUT_VePLTR_b_RRCCPROXI_Value: accessed-variable=VePLTR_b_RRCCPROXI.Value
              OUT_VePLTR_b_RmtVehStartReq_Value: accessed-variable=VePLTR_b_RmtVehStartReq.Value
              OUT_VePLTR_b_HDCEnabledCAN_FA_Value: accessed-variable=VePLTR_b_HDCEnabledCAN_FA.Value
              OUT_VePLTR_phi_LwsAngle_Value: accessed-variable=VePLTR_phi_LwsAngle.Value
              OUT_VePLTR_dphi_LwsSpeed_Value: accessed-variable=VePLTR_dphi_LwsSpeed.Value
              OUT_VePLTR_p_AmbientAirPrs_Value: accessed-variable=VePLTR_p_AmbientAirPrs.Value
              OUT_VePLTR_e_LwsAngleType_Value: accessed-variable=VePLTR_e_LwsAngleType.Value
              OUT_VePLTR_b_RadFanHndShk_dsbld_Value: accessed-variable=VePLTR_b_RadFanHndShk_dsbld.Value
              OUT_VePLTR_b_ERS_SWFA_Value: accessed-variable=VePLTR_b_ERS_SWFA.Value
              OUT_VePLTR_e_BSM_AxleTrq_Enbld_Value: accessed-variable=VePLTR_e_BSM_AxleTrq_Enbld.Value
              OUT_VePLTR_a_LongAccel_ORC_Value: accessed-variable=VePLTR_a_LongAccel_ORC.Value
              OUT_VePLTR_a_LatAccel_ORC_Value: accessed-variable=VePLTR_a_LatAccel_ORC.Value
              OUT_VePLTR_dphi_YawRate_ORC_Value: accessed-variable=VePLTR_dphi_YawRate_ORC.Value
              OUT_VePLTR_b_LongAccelFA_Value: accessed-variable=VePLTR_b_LongAccelFA.Value
              OUT_VePLTR_v_HomSpdLim_Value: accessed-variable=VePLTR_v_HomSpdLim.Value
              OUT_VePLTR_b_ChargeReq_Value: accessed-variable=VePLTR_b_ChargeReq.Value
              OUT_VePLTR_e_InvOprStat_Value: accessed-variable=VePLTR_e_InvOprStat.Value
              OUT_VePLTR_e_V2GOprStat_Value: accessed-variable=VePLTR_e_V2GOprStat.Value
              OUT_VePLTR_b_LongAccelFailSts_ORC_Value: accessed-variable=VePLTR_b_LongAccelFailSts_ORC.Value
              OUT_VePLTR_b_LatAccelFailSts_ORC_Value: accessed-variable=VePLTR_b_LatAccelFailSts_ORC.Value
              OUT_VePLTR_e_EPBHoldSts_Value: accessed-variable=VePLTR_e_EPBHoldSts.Value
              OUT_VePLTR_b_YawRateFailSts_ORC_Value: accessed-variable=VePLTR_b_YawRateFailSts_ORC.Value
              OUT_VePLTR_b_ProxiCADM_Value: accessed-variable=VePLTR_b_ProxiCADM.Value
              OUT_VePLTR_b_ProxiCADM2_Value: accessed-variable=VePLTR_b_ProxiCADM2.Value
              OUT_VePLTR_e_VehCategory_Value: accessed-variable=VePLTR_e_VehCategory.Value
              OUT_VePLTR_b_ESSRqShftPark_Value: accessed-variable=VePLTR_b_ESSRqShftPark.Value
              OUT_VePLTR_a_LongAccelOffset_Value: accessed-variable=VePLTR_a_LongAccelOffset.Value
              OUT_VePLTR_e_ShiftIndSt_Value: accessed-variable=VePLTR_e_ShiftIndSt.Value
              OUT_VePLTR_a_LatAccel_Value: accessed-variable=VePLTR_a_LatAccel.Value
              OUT_VePLTR_b_DrvDrAjar_Value: accessed-variable=VePLTR_b_DrvDrAjar.Value
              OUT_VePLTR_b_MILOnRq_ESC_Value: accessed-variable=VePLTR_b_MILOnRq_ESC.Value
              OUT_VePLTR_b_EPBFailSts_Value: accessed-variable=VePLTR_b_EPBFailSts.Value
              OUT_VePLTR_e_VehCfgSt_Value: accessed-variable=VePLTR_e_VehCfgSt.Value
              OUT_VePLTR_b_Worksite_Inverter_Active_Value: accessed-variable=VePLTR_b_Worksite_Inverter_Active.Value
              OUT_VePLTR_e_Worksite_Inverter_Sts_Value: accessed-variable=VePLTR_e_Worksite_Inverter_Sts.Value
              OUT_VePLTR_e_ProxiACC_Value: accessed-variable=VePLTR_e_ProxiACC.Value
              OUT_VePLTR_b_HDCEnabledCAN_Value: accessed-variable=VePLTR_b_HDCEnabledCAN.Value
              OUT_VePLTR_b_ProxiCC_Value: accessed-variable=VePLTR_b_ProxiCC.Value
              OUT_VePLTR_b_ProxiSpdLimiter_Value: accessed-variable=VePLTR_b_ProxiSpdLimiter.Value
              OUT_VePLTR_b_ProxiNAVPrsnc_Value: accessed-variable=VePLTR_b_ProxiNAVPrsnc.Value
              OUT_VePLTR_b_ProxiTrafficSignRcgntn_Value: accessed-variable=VePLTR_b_ProxiTrafficSignRcgntn.Value
              OUT_VePLTR_Pct_ProxiSpdomtrTol_Value: accessed-variable=VePLTR_Pct_ProxiSpdomtrTol.Value
              OUT_VePLTR_b_ACC_On_Value: accessed-variable=VePLTR_b_ACC_On.Value
              OUT_VePLTR_e_ProxiIncreasingSpdCnst_Value: accessed-variable=VePLTR_e_ProxiIncreasingSpdCnst.Value
              OUT_VePLTR_b_ACC_OnFA_Value: accessed-variable=VePLTR_b_ACC_OnFA.Value
              OUT_VePLTR_b_ParkBrakeSts_Value: accessed-variable=VePLTR_b_ParkBrakeSts.Value
              OUT_VePLTR_a_LongAccel_Value: accessed-variable=VePLTR_a_LongAccel.Value
              OUT_VePLTR_e_ACCSystemSts_Value: accessed-variable=VePLTR_e_ACCSystemSts.Value
              OUT_VePLTR_b_InternalLightSts_Value: accessed-variable=VePLTR_b_InternalLightSts.Value
              OUT_VePLTR_b_RmtVehStartReqFA_Value: accessed-variable=VePLTR_b_RmtVehStartReqFA.Value
              OUT_VePLTR_b_DrvDrAjarFA_Value: accessed-variable=VePLTR_b_DrvDrAjarFA.Value
              OUT_VePLTR_i_ShippingModeRaw_Value: accessed-variable=VePLTR_i_ShippingModeRaw.Value
              OUT_VePLTR_b_REMDisabled_Value: accessed-variable=VePLTR_b_REMDisabled.Value
              OUT_VePLTR_Pct_REMLogisticSOCSetPt_Value: accessed-variable=VePLTR_Pct_REMLogisticSOCSetPt.Value
              OUT_VePLTR_Pct_InPlant_SOCSetPt_Value: accessed-variable=VePLTR_Pct_InPlant_SOCSetPt.Value
              OUT_VePLTR_e_ERS_SW_Value: accessed-variable=VePLTR_e_ERS_SW.Value
              OUT_VePLTR_b_Inverter_PowerDraw_FA_Value: accessed-variable=VePLTR_b_Inverter_PowerDraw_FA.Value
              OUT_VePLTR_b_Worksite_Inverter_Active_FA_Value: accessed-variable=VePLTR_b_Worksite_Inverter_Active_FA.Value
              OUT_VePLTR_b_InPlantAllowCharge_Value: accessed-variable=VePLTR_b_InPlantAllowCharge.Value
              OUT_VePLTR_e_ProxyHybridType_Value: accessed-variable=VePLTR_e_ProxyHybridType.Value
              OUT_VePLTR_b_EPBHoldStsFA_Value: accessed-variable=VePLTR_b_EPBHoldStsFA.Value
              OUT_VePLTR_e_Proxi_Autonomy_Lvl_Value: accessed-variable=VePLTR_e_Proxi_Autonomy_Lvl.Value
              OUT_VePLTR_e_Proxi_CC_Logic_Value: accessed-variable=VePLTR_e_Proxi_CC_Logic.Value
              OUT_VePLTR_b_Hill_Des_Stat_Prx_Value: accessed-variable=VePLTR_b_Hill_Des_Stat_Prx.Value
              OUT_VePLTR_e_MRM_Status_Value: accessed-variable=VePLTR_e_MRM_Status.Value
              OUT_VePLTR_b_MRM_Status_FA_Value: accessed-variable=VePLTR_b_MRM_Status_FA.Value
              OUT_VePLTR_e_MRM_Status_C2_FA_Value: accessed-variable=VePLTR_e_MRM_Status_C2_FA.Value
              OUT_VePLTR_e_MRM_Status_C2_Value: accessed-variable=VePLTR_e_MRM_Status_C2.Value
              OUT_VePLTR_e_LSMDExtReleaseLockReq_Value: accessed-variable=VePLTR_e_LSMDExtReleaseLockReq.Value
              OUT_VePLTR_b_HotEnablerReq_Value: accessed-variable=VePLTR_b_HotEnablerReq.Value
              OUT_VePLTR_b_SpeedUnit_FA_Value: accessed-variable=VePLTR_b_SpeedUnit_FA.Value
              OUT_VePLTR_e_Scndry_TransShiftPstn_Value: accessed-variable=VePLTR_e_Scndry_TransShiftPstn.Value
              OUT_VePLTR_b_Scndry_TransShiftPstnFA_Value: accessed-variable=VePLTR_b_Scndry_TransShiftPstnFA.Value
              OUT_VePLTR_e_Prmry_TransShiftPstn_Value: accessed-variable=VePLTR_e_Prmry_TransShiftPstn.Value
              OUT_VePLTR_b_Prmry_TransShiftPstnFA_Value: accessed-variable=VePLTR_b_Prmry_TransShiftPstnFA.Value
              OUT_VePLTR_b_InFieldMode_Value: accessed-variable=VePLTR_b_InFieldMode.Value
              OUT_VePLTR_b_DriverDetected_Value: accessed-variable=VePLTR_b_DriverDetected.Value
              OUT_VePLTR_Cnt_TotalEngRunTime_Recent_Value: accessed-variable=VePLTR_Cnt_TotalEngRunTime_Recent.Value
              OUT_VePLTR_Cnt_TotalEngRunTime_Lifetime_Value: accessed-variable=VePLTR_Cnt_TotalEngRunTime_Lifetime.Value
              OUT_VePLTR_Cnt_TotalIdleEngRunTime_Recent_Value: accessed-variable=VePLTR_Cnt_TotalIdleEngRunTime_Recent.Value
              OUT_VePLTR_Cnt_TotalIdleEngRunTime_Lifetime_Value: accessed-variable=VePLTR_Cnt_TotalIdleEngRunTime_Lifetime.Value
              OUT_VePLTR_t_RTC_CurrentTime_Value: accessed-variable=VePLTR_t_RTC_CurrentTime.Value
              OUT_VePLTR_b_RTC_CurrentTimeFA_Value: accessed-variable=VePLTR_b_RTC_CurrentTimeFA.Value
              OUT_VePLTR_t_RTC_SleepTime_Value: accessed-variable=VePLTR_t_RTC_SleepTime.Value
              OUT_VePLTR_pmbar_AmbientAirPrs_Value: accessed-variable=VePLTR_pmbar_AmbientAirPrs.Value
              OUT_VePLTR_b_CrsCntrlActv_Value: accessed-variable=VePLTR_b_CrsCntrlActv.Value
              OUT_VePLTR_e_VehicleCountryCode_Value: accessed-variable=VePLTR_e_VehicleCountryCode.Value
              OUT_VePLTR_e_ShippingMode_Value: accessed-variable=VePLTR_e_ShippingMode.Value
              OUT_VePLTR_milel_InPlntMileageLmt_Miles_Value: accessed-variable=VePLTR_milel_InPlntMileageLmt_Miles.Value
              OUT_VePLTR_milel_Odometer_Miles_Value: accessed-variable=VePLTR_milel_Odometer_Miles.Value
              OUT_VePLTR_milel_IPEETestMileageLimit_Value: accessed-variable=VePLTR_milel_IPEETestMileageLimit.Value
              OUT_VePLTR_phi_EstSlopeAngle_Value: accessed-variable=VePLTR_phi_EstSlopeAngle.Value
              OUT_VePLTR_b_EstSlopeAngleFA_Value: accessed-variable=VePLTR_b_EstSlopeAngleFA.Value
              OUT_VePLTR_b_ChargeReqSgnlRcvd_Value: accessed-variable=VePLTR_b_ChargeReqSgnlRcvd.Value
              OUT_VePLTR_phi_EstRollAngleAtZeroSpd_Value: accessed-variable=VePLTR_phi_EstRollAngleAtZeroSpd.Value
              OUT_VePLTR_b_EstRollAngleAtZeroSpdFA_Value: accessed-variable=VePLTR_b_EstRollAngleAtZeroSpdFA.Value
              OUT_VePLTR_b_WarmupAchieved_Value: accessed-variable=VePLTR_b_WarmupAchieved.Value
              OUT_VePLTR_b_SpeedUnit_Value: accessed-variable=VePLTR_b_SpeedUnit.Value
              OUT_VePLTR_e_ESMTransRngSt_Value: accessed-variable=VePLTR_e_ESMTransRngSt.Value
              OUT_VePLTR_e_AutoPosCorrMd_Value: accessed-variable=VePLTR_e_AutoPosCorrMd.Value
              OUT_VePLTR_b_ShftLckFlt_Value: accessed-variable=VePLTR_b_ShftLckFlt.Value
              OUT_VePLTR_b_RackFaultFA_Value: accessed-variable=VePLTR_b_RackFaultFA.Value
              OUT_VePLTR_b_ShftSnsFA_Value: accessed-variable=VePLTR_b_ShftSnsFA.Value
              OUT_VePLTR_b_ShiftDspFlt_Value: accessed-variable=VePLTR_b_ShiftDspFlt.Value
              OUT_VePLTR_y_GatedParkSwFlt_Value: accessed-variable=VePLTR_y_GatedParkSwFlt.Value
              OUT_VePLTR_e_ShiftLeverPosReq_Value: accessed-variable=VePLTR_e_ShiftLeverPosReq.Value
              OUT_VePLTR_b_ShiftLeverFailSts_Value: accessed-variable=VePLTR_b_ShiftLeverFailSts.Value
              OUT_VePLTR_b_PRNDFailSts_Value: accessed-variable=VePLTR_b_PRNDFailSts.Value
              OUT_VePLTR_b_RFHub_ForcePark_Value: accessed-variable=VePLTR_b_RFHub_ForcePark.Value
              OUT_VePLTR_e_RationalisedRngSt_Value: accessed-variable=VePLTR_e_RationalisedRngSt.Value
              OUT_VePLTR_e_ValidatePstn_Value: accessed-variable=VePLTR_e_ValidatePstn.Value
              OUT_VePLTR_b_ManualMode_Value: accessed-variable=VePLTR_b_ManualMode.Value
              OUT_VePLTR_Pct_EstSlopeAnglePct_Value: accessed-variable=VePLTR_Pct_EstSlopeAnglePct.Value
              OUT_VePLTR_b_DAI_Enbl_Value: accessed-variable=VePLTR_b_DAI_Enbl.Value
              OUT_VePLTR_b_ResetFlagRecent_EEerror_Value: accessed-variable=VePLTR_b_ResetFlagRecent_EEerror.Value
              OUT_VePLTR_dVh_FuelConsumption_avrg_Value: accessed-variable=VePLTR_dVh_FuelConsumption_avrg.Value
              OUT_VePLTR_b_ClrTrackingInfo_Value: accessed-variable=VePLTR_b_ClrTrackingInfo.Value
              OUT_VePLTR_b_ResetFlagLifetime_EEerror_Value: accessed-variable=VePLTR_b_ResetFlagLifetime_EEerror.Value
              OUT_VePLTR_e_FaultSts_ECUInplantmodeAct_Value: accessed-variable=VePLTR_e_FaultSts_ECUInplantmodeAct.Value
              OUT_VePLTR_e_HAS_TelltaleSts_Value: accessed-variable=VePLTR_e_HAS_TelltaleSts.Value
              OUT_VePLTR_b_HAS_TelltaleSts_FA_Value: accessed-variable=VePLTR_b_HAS_TelltaleSts_FA.Value
              OUT_VePLTR_e_AEBSystemSts_Value: accessed-variable=VePLTR_e_AEBSystemSts.Value
              OUT_VePLTR_b_AEBSystemSts_FA_Value: accessed-variable=VePLTR_b_AEBSystemSts_FA.Value
              OUT_VePLTR_e_Command_15Sts_Value: accessed-variable=VePLTR_e_Command_15Sts.Value
              OUT_VePLTR_b_Command_15Sts_FA_Value: accessed-variable=VePLTR_b_Command_15Sts_FA.Value
              OUT_VePLTR_b_LHRDoorSts_Value: accessed-variable=VePLTR_b_LHRDoorSts.Value
              OUT_VePLTR_b_LHRDoorSts_FA_Value: accessed-variable=VePLTR_b_LHRDoorSts_FA.Value
              OUT_VePLTR_b_ParkBrakeSts_FA_Value: accessed-variable=VePLTR_b_ParkBrakeSts_FA.Value
              OUT_VePLTR_b_PsngrDoorSts_Value: accessed-variable=VePLTR_b_PsngrDoorSts.Value
              OUT_VePLTR_b_PsngrDoorSts_FA_Value: accessed-variable=VePLTR_b_PsngrDoorSts_FA.Value
              OUT_VePLTR_b_RHatchSts_Value: accessed-variable=VePLTR_b_RHatchSts.Value
              OUT_VePLTR_b_RHatchSts_FA_Value: accessed-variable=VePLTR_b_RHatchSts_FA.Value
              OUT_VePLTR_b_RHRDoorSts_Value: accessed-variable=VePLTR_b_RHRDoorSts.Value
              OUT_VePLTR_b_RHRDoorSts_FA_Value: accessed-variable=VePLTR_b_RHRDoorSts_FA.Value
              OUT_VePLTR_b_ImmoParkReq_Value: accessed-variable=VePLTR_b_ImmoParkReq.Value
              OUT_VePLTR_b_LatAccelFA_Value: accessed-variable=VePLTR_b_LatAccelFA.Value
              OUT_VePLTR_b_LwsAngleFA_Value: accessed-variable=VePLTR_b_LwsAngleFA.Value
              OUT_VePLTR_e_eBurn_Stages_Value: accessed-variable=VePLTR_e_eBurn_Stages.Value
              OUT_VePLTR_b_eBurn_Stages_FA_Value: accessed-variable=VePLTR_b_eBurn_Stages_FA.Value
              OUT_VePLTR_l_TravelDistance_Value: accessed-variable=VePLTR_l_TravelDistance.Value
              OUT_VePLTR_b_TravelDistance_FA_Value: accessed-variable=VePLTR_b_TravelDistance_FA.Value
              OUT_VePLTR_e_FaultSts_IgnKeyOffTmrPerfTooFast_Value: accessed-variable=VePLTR_e_FaultSts_IgnKeyOffTmrPerfTooFast.Value
              OUT_VePLTR_t_HCPOffTime_Value: accessed-variable=VePLTR_t_HCPOffTime.Value
              OUT_VePLTR_b_HCPOffTimeFA_Value: accessed-variable=VePLTR_b_HCPOffTimeFA.Value
              OUT_VePLTR_b_BatteryWasDisconnected_Value: accessed-variable=VePLTR_b_BatteryWasDisconnected.Value
              OUT_AePLTR_b_PwrOffOk_AePLTR_b_PwrOffOk: accessed-variable=AePLTR_b_PwrOffOk.AePLTR_b_PwrOffOk
              OUT_VePLTR_e_SelectSpdSts_Value: accessed-variable=VePLTR_e_SelectSpdSts.Value
              OUT_VePLTR_b_SelectSpdSts_FA_Value: accessed-variable=VePLTR_b_SelectSpdSts_FA.Value
              OUT_VePLTR_e_ParkingGearShiftReq_BSM_Value: accessed-variable=VePLTR_e_ParkingGearShiftReq_BSM.Value
              OUT_VePLTR_b_ParkingGearShiftReq_BSM_FA_Value: accessed-variable=VePLTR_b_ParkingGearShiftReq_BSM_FA.Value
              OUT_VePLTR_Pct_Slope_Value: accessed-variable=VePLTR_Pct_Slope.Value
              OUT_VePLTR_b_Slope_FA_Value: accessed-variable=VePLTR_b_Slope_FA.Value
              OUT_VePLTR_y_FobSearchResult_Value: accessed-variable=VePLTR_y_FobSearchResult.Value
              OUT_VePLTR_b_FobSearchResult_FA_Value: accessed-variable=VePLTR_b_FobSearchResult_FA.Value
              OUT_VePLTR_b_Secure_Idle_Req_Value: accessed-variable=VePLTR_b_Secure_Idle_Req.Value
              OUT_VePLTR_b_Secure_Idle_Req_FA_Value: accessed-variable=VePLTR_b_Secure_Idle_Req_FA.Value
              OUT_VePLTR_e_HiBmLvr_Stat_Value: accessed-variable=VePLTR_e_HiBmLvr_Stat.Value
              OUT_VePLTR_b_HiBmLvr_Stat_FA_Value: accessed-variable=VePLTR_b_HiBmLvr_Stat_FA.Value
              OUT_VePLTR_b_RearFogLightSts_Value: accessed-variable=VePLTR_b_RearFogLightSts.Value
              OUT_VePLTR_y_AUD_LVL_Value: accessed-variable=VePLTR_y_AUD_LVL.Value
              OUT_VePLTR_b_AUD_LVL_FA_Value: accessed-variable=VePLTR_b_AUD_LVL_FA.Value
              OUT_VePLTR_b_ADS_SrvSys_Value: accessed-variable=VePLTR_b_ADS_SrvSys.Value
              OUT_VePLTR_b_ADS_SrvSys_FA_Value: accessed-variable=VePLTR_b_ADS_SrvSys_FA.Value
              OUT_VePLTR_b_ASCM_Srv_Value: accessed-variable=VePLTR_b_ASCM_Srv.Value
              OUT_VePLTR_b_ASCM_Srv_FA_Value: accessed-variable=VePLTR_b_ASCM_Srv_FA.Value
              OUT_VePLTR_e_ASCM_Stat_Value: accessed-variable=VePLTR_e_ASCM_Stat.Value
              OUT_VePLTR_b_ASCM_Stat_FA_Value: accessed-variable=VePLTR_b_ASCM_Stat_FA.Value
              OUT_VePLTR_b_ASCM_SysFail_Value: accessed-variable=VePLTR_b_ASCM_SysFail.Value
              OUT_VePLTR_b_ASCM_SysFail_FA_Value: accessed-variable=VePLTR_b_ASCM_SysFail_FA.Value
              OUT_VePLTR_e_DriverSeatBeltSts_Value: accessed-variable=VePLTR_e_DriverSeatBeltSts.Value
              OUT_VePLTR_b_DriverSeatBeltStsFA_Value: accessed-variable=VePLTR_b_DriverSeatBeltStsFA.Value
              OUT_VePLTR_kl_Odometer_Km_Value: accessed-variable=VePLTR_kl_Odometer_Km.Value
              OUT_VePLTR_b_Odometer_KmFA_Value: accessed-variable=VePLTR_b_Odometer_KmFA.Value
              OUT_VePLTR_e_ECMVtdFreeze_Value: accessed-variable=VePLTR_e_ECMVtdFreeze.Value
          read-local-variables:
            4 x access:
              RV_HVBatRealTimeClock_BPCM_write_IRV: accessed-variable=HVBatRealTimeClock_BPCM_write_IRV
              RV_HVBatRealTimeClock_FA_BPCM_write_IRV: accessed-variable=HVBatRealTimeClock_FA_BPCM_write_IRV
              RV_HVBatSleepTime_BPCM_write_IRV: accessed-variable=HVBatSleepTime_BPCM_write_IRV
              RV_VePLTR_p_AmbientAirPrs_write_IRV: accessed-variable=VePLTR_p_AmbientAirPrs_write_IRV
          written-local-variables:
            82 x access:
              WV_VePLTR_b_Scndry_AutoPosCorrMdFA_write_IRV: accessed-variable=VePLTR_b_Scndry_AutoPosCorrMdFA_write_IRV
              WV_VePLTR_b_Prmry_AutoPosCorrMdFA_write_IRV: accessed-variable=VePLTR_b_Prmry_AutoPosCorrMdFA_write_IRV
              WV_AutoPosCorrMd_Ini_write_IRV: accessed-variable=AutoPosCorrMd_Ini_write_IRV
              WV_AutoPosCorrMd_Init_write_IRV: accessed-variable=AutoPosCorrMd_Init_write_IRV
              WV_DriverDetected_write_IRV: accessed-variable=DriverDetected_write_IRV
              WV_VePLTR_b_DrvrSeatSnsrSts_FA_write_IRV: accessed-variable=VePLTR_b_DrvrSeatSnsrSts_FA_write_IRV
              WV_DrvrSeatSnsrSts_Init_write_IRV: accessed-variable=DrvrSeatSnsrSts_Init_write_IRV
              WV_DrvrSeatSnsr_FailSts_Init_write_IRV: accessed-variable=DrvrSeatSnsr_FailSts_Init_write_IRV
              WV_FuelLevelLowClster_Init_write_IRV: accessed-variable=FuelLevelLowClster_Init_write_IRV
              WV_HVBatRealTimeClock_BPCM_write_IRV: accessed-variable=HVBatRealTimeClock_BPCM_write_IRV
              WV_HVBatRealTimeClock_FA_BPCM_write_IRV: accessed-variable=HVBatRealTimeClock_FA_BPCM_write_IRV
              WV_HVBatSleepTime_BPCM_write_IRV: accessed-variable=HVBatSleepTime_BPCM_write_IRV
              WV_HWIO_GatedParkSWFault_write_IRV: accessed-variable=HWIO_GatedParkSWFault_write_IRV
              WV_VePLTR_b_Prmry_ManualModeFA_write_IRV: accessed-variable=VePLTR_b_Prmry_ManualModeFA_write_IRV
              WV_ManualMode_Init_write_IRV: accessed-variable=ManualMode_Init_write_IRV
              WV_OutTorqReqModHH_write_IRV: accessed-variable=OutTorqReqModHH_write_IRV
              WV_PRND_ValidatePstn_InitSndry_write_IRV: accessed-variable=PRND_ValidatePstn_InitSndry_write_IRV
              WV_PRND_ValidatePstn_Init_write_IRV: accessed-variable=PRND_ValidatePstn_Init_write_IRV
              WV_VePLTR_b_Scndry_ForceParkFA_write_IRV: accessed-variable=VePLTR_b_Scndry_ForceParkFA_write_IRV
              WV_RFHUB_ForcePark_Init_PwrOn_1_IRV_IRV: accessed-variable=RFHUB_ForcePark_Init_PwrOn_1_IRV_IRV
              WV_VePLTR_b_Prmry_ForceParkFA_write_IRV: accessed-variable=VePLTR_b_Prmry_ForceParkFA_write_IRV
              WV_RFHub_ForcePark_Init_write_IRV: accessed-variable=RFHub_ForcePark_Init_write_IRV
              WV_VePLTR_b_Scndry_RackDetentSensorFAFA_write_IRV: accessed-variable=VePLTR_b_Scndry_RackDetentSensorFAFA_write_IRV
              WV_VePLTR_b_Prmry_RackDetentSensorFAFA_write_IRV: accessed-variable=VePLTR_b_Prmry_RackDetentSensorFAFA_write_IRV
              WV_VePLTR_b_Scndry_ShifterDispFAFA_write_IRV: accessed-variable=VePLTR_b_Scndry_ShifterDispFAFA_write_IRV
              WV_VePLTR_b_Prmry_ShifterDispFAFA_write_IRV: accessed-variable=VePLTR_b_Prmry_ShifterDispFAFA_write_IRV
              WV_VePLTR_b_Scndry_ShiftLockFAFA_write_IRV: accessed-variable=VePLTR_b_Scndry_ShiftLockFAFA_write_IRV
              WV_VePLTR_b_Prmry_ShiftLockFAFA_write_IRV: accessed-variable=VePLTR_b_Prmry_ShiftLockFAFA_write_IRV
              WV_VePLTR_b_Scndry_ShiftSnsFAFA_write_IRV: accessed-variable=VePLTR_b_Scndry_ShiftSnsFAFA_write_IRV
              WV_VePLTR_b_Prmry_ShiftSnsFAFA_write_IRV: accessed-variable=VePLTR_b_Prmry_ShiftSnsFAFA_write_IRV
              WV_VePLTR_b_Prmry_PRNDFailStsFA_write_IRV: accessed-variable=VePLTR_b_Prmry_PRNDFailStsFA_write_IRV
              WV_VePLTR_b_Scndry_ShiftLeverFailStsFA_write_IRV: accessed-variable=VePLTR_b_Scndry_ShiftLeverFailStsFA_write_IRV
              WV_VePLTR_b_Prmry_ShiftLeverFailStsFA_write_IRV: accessed-variable=VePLTR_b_Prmry_ShiftLeverFailStsFA_write_IRV
              WV_VePLTR_b_Scndry_PRNDFailStsFA_write_IRV: accessed-variable=VePLTR_b_Scndry_PRNDFailStsFA_write_IRV
              WV_VePLTR_b_Scndry_ShiftLeverPositionReqFA_write_IRV: accessed-variable=VePLTR_b_Scndry_ShiftLeverPositionReqFA_write_IRV
              WV_VePLTR_b_Prmry_ShiftLeverPositionReqFA_write_IRV: accessed-variable=VePLTR_b_Prmry_ShiftLeverPositionReqFA_write_IRV
              WV_ShiftLeverPositionReq_Ini_write_IRV: accessed-variable=ShiftLeverPositionReq_Ini_write_IRV
              WV_ShiftLeverPositionReq_Init_write_IRV: accessed-variable=ShiftLeverPositionReq_Init_write_IRV
              WV_VePLTR_b_Prmry_TransShiftPstnFA_write_IRV: accessed-variable=VePLTR_b_Prmry_TransShiftPstnFA_write_IRV
              WV_VePLTR_b_Scndry_TransShiftPstnFA_write_IRV: accessed-variable=VePLTR_b_Scndry_TransShiftPstnFA_write_IRV
              WV_Toggle_1s_write_IRV: accessed-variable=Toggle_1s_write_IRV
              WV_TransShiftPosInitMSG_write_IRV: accessed-variable=TransShiftPosInitMSG_write_IRV
              WV_TransShiftPos_InitMSG_write_IRV: accessed-variable=TransShiftPos_InitMSG_write_IRV
              WV_VePLTI_b_RTC_CurrentTimeFA_Init_write_IRV: accessed-variable=VePLTI_b_RTC_CurrentTimeFA_Init_write_IRV
              WV_VePLTI_e_ShippingMode_write_IRV: accessed-variable=VePLTI_e_ShippingMode_write_IRV
              WV_VePLTI_kl_Odometer_Km_write_IRV: accessed-variable=VePLTI_kl_Odometer_Km_write_IRV
              WV_VePLTR_a_TransAccelOffset_write_IRV: accessed-variable=VePLTR_a_TransAccelOffset_write_IRV
              WV_VePLTR_a_TransAccel_write_IRV: accessed-variable=VePLTR_a_TransAccel_write_IRV
              WV_VePLTR_a_LongAccelOffset_write_IRV: accessed-variable=VePLTR_a_LongAccelOffset_write_IRV
              WV_VePLTR_a_LongAccel_write_IRV: accessed-variable=VePLTR_a_LongAccel_write_IRV
              WV_VePLTR_b_ACCEnbledInit_write_IRV: accessed-variable=VePLTR_b_ACCEnbledInit_write_IRV
              WV_VePLTR_b_BatteryWasDisconnected_Init_write_IRV: accessed-variable=VePLTR_b_BatteryWasDisconnected_Init_write_IRV
              WV_VePLTR_b_CrsCntrlActv_write_IRV: accessed-variable=VePLTR_b_CrsCntrlActv_write_IRV
              WV_VePLTR_b_DoorFailSts_Init_write_IRV: accessed-variable=VePLTR_b_DoorFailSts_Init_write_IRV
              WV_VePLTR_b_DriverDoorOnOffSts_FA_IRV: accessed-variable=VePLTR_b_DriverDoorOnOffSts_FA_IRV
              WV_VePLTR_b_DrvDrAjar_write_IRV: accessed-variable=VePLTR_b_DrvDrAjar_write_IRV
              WV_VePLTR_b_GPS_Date_DayFA_write_IRV: accessed-variable=VePLTR_b_GPS_Date_DayFA_write_IRV
              WV_VePLTR_b_GPS_Date_MonthFA_write_IRV: accessed-variable=VePLTR_b_GPS_Date_MonthFA_write_IRV
              WV_VePLTR_b_GPS_Date_YearFA_write_IRV: accessed-variable=VePLTR_b_GPS_Date_YearFA_write_IRV
              WV_VePLTR_b_GPS_UTC_HourFA_write_IRV: accessed-variable=VePLTR_b_GPS_UTC_HourFA_write_IRV
              WV_VePLTR_b_GPS_UTC_MinuteFA_write_IRV: accessed-variable=VePLTR_b_GPS_UTC_MinuteFA_write_IRV
              WV_VePLTR_b_GPS_UTC_SecondFA_write_IRV: accessed-variable=VePLTR_b_GPS_UTC_SecondFA_write_IRV
              WV_VePLTR_b_TransAccelFA_write_IRV: accessed-variable=VePLTR_b_TransAccelFA_write_IRV
              WV_VePLTR_b_TransAccelOffsetFA_write_IRV: accessed-variable=VePLTR_b_TransAccelOffsetFA_write_IRV
              WV_VePLTR_b_LongAccelFA_write_IRV: accessed-variable=VePLTR_b_LongAccelFA_write_IRV
              WV_VePLTR_b_LongAccelOffsetFA_write_IRV: accessed-variable=VePLTR_b_LongAccelOffsetFA_write_IRV
              WV_VePLTR_b_DriverSeatBeltStsFA_write_IRV: accessed-variable=VePLTR_b_DriverSeatBeltStsFA_write_IRV
              WV_VePLTR_b_SpeedUnit_Init_write_IRV: accessed-variable=VePLTR_b_SpeedUnit_Init_write_IRV
              WV_VePLTR_e_DriverDoorOnOffSts_Init_IRV: accessed-variable=VePLTR_e_DriverDoorOnOffSts_Init_IRV
              WV_VePLTR_e_ECMVtdFreezeInit_write_IRV: accessed-variable=VePLTR_e_ECMVtdFreezeInit_write_IRV
              WV_VePLTR_e_RTCTestSyncReport_Init_IRV: accessed-variable=VePLTR_e_RTCTestSyncReport_Init_IRV
              WV_VePLTR_e_DriverSeatBeltSts_write_IRV: accessed-variable=VePLTR_e_DriverSeatBeltSts_write_IRV
              WV_VePLTR_p_AmbientAirPrs_write_IRV: accessed-variable=VePLTR_p_AmbientAirPrs_write_IRV
              WV_VePLTR_t_GPS_UTC_Second_PwrOn_IRV: accessed-variable=VePLTR_t_GPS_UTC_Second_PwrOn_IRV
              WV_VePLTR_tdy_GPS_Date_Day_PwrOn_IRV: accessed-variable=VePLTR_tdy_GPS_Date_Day_PwrOn_IRV
              WV_VePLTR_thr_GPS_UTC_Hour_PwrOn_IRV: accessed-variable=VePLTR_thr_GPS_UTC_Hour_PwrOn_IRV
              WV_VePLTR_tmn_GPS_UTC_Minute_PwrOn_IRV: accessed-variable=VePLTR_tmn_GPS_UTC_Minute_PwrOn_IRV
              WV_VePLTR_tmt_GPS_Date_Month_PwrOn_IRV: accessed-variable=VePLTR_tmt_GPS_Date_Month_PwrOn_IRV
              WV_VePLTR_tyr_GPS_Date_Year_PwrOn_IRV: accessed-variable=VePLTR_tyr_GPS_Date_Year_PwrOn_IRV
              WV_VehSpd_write_IRV: accessed-variable=VehSpd_write_IRV
              WV_VePLTR_b_Scndry_PRND_ValidatePstnFA_write_IRV: accessed-variable=VePLTR_b_Scndry_PRND_ValidatePstnFA_write_IRV
              WV_VePLTR_b_Prmry_PRND_ValidatePstnFA_write_IRV: accessed-variable=VePLTR_b_Prmry_PRND_ValidatePstnFA_write_IRV
        PLTR_MedTEB
          data-receive-point-by-arguments:
            21 x access:
              IN_VeCSVR_a_VehAccel_Value: accessed-variable=VeCSVR_a_VehAccel.Value
              IN_VeCSVR_b_VehSpdFA_Value: accessed-variable=VeCSVR_b_VehSpdFA.Value
              IN_VePMDR_e_PMM_PowerMode_Value: accessed-variable=VePMDR_e_PMM_PowerMode.Value
              IN_VePRXR_Pct_ProxiSpdomtrTol_Value: accessed-variable=VePRXR_Pct_ProxiSpdomtrTol.Value
              IN_VePRXR_b_Hill_Des_Stat_Prx_Value: accessed-variable=VePRXR_b_Hill_Des_Stat_Prx.Value
              IN_VePRXR_b_ProxiCADM_Value: accessed-variable=VePRXR_b_ProxiCADM.Value
              IN_VePRXR_b_ProxiCADM2_Value: accessed-variable=VePRXR_b_ProxiCADM2.Value
              IN_VePRXR_b_ProxiCC_Value: accessed-variable=VePRXR_b_ProxiCC.Value
              IN_VePRXR_b_ProxiNavPrsnc_Value: accessed-variable=VePRXR_b_ProxiNavPrsnc.Value
              IN_VePRXR_b_ProxiSpdLimiter_Value: accessed-variable=VePRXR_b_ProxiSpdLimiter.Value
              IN_VePRXR_b_ProxiTrafficSignRcgntn_Value: accessed-variable=VePRXR_b_ProxiTrafficSignRcgntn.Value
              IN_VePRXR_b_RRCCPROXI_Value: accessed-variable=VePRXR_b_RRCCPROXI.Value
              IN_VePRXR_e_ProxiACC_Value: accessed-variable=VePRXR_e_ProxiACC.Value
              IN_VePRXR_e_ProxiIncreasingSpdCnst_Value: accessed-variable=VePRXR_e_ProxiIncreasingSpdCnst.Value
              IN_VePRXR_e_Proxi_Autonomy_Lvl_Value: accessed-variable=VePRXR_e_Proxi_Autonomy_Lvl.Value
              IN_VePRXR_e_Proxi_CC_Logic_Value: accessed-variable=VePRXR_e_Proxi_CC_Logic.Value
              IN_VePRXR_e_ProxyHybridType_Value: accessed-variable=VePRXR_e_ProxyHybridType.Value
              IN_VePRXR_e_ShiftIndSt_Value: accessed-variable=VePRXR_e_ShiftIndSt.Value
              IN_VePRXR_e_VehCategory_Value: accessed-variable=VePRXR_e_VehCategory.Value
              IN_VePRXR_e_VehicleCountryCode_Value: accessed-variable=VePRXR_e_VehicleCountryCode.Value
              IN_VePRXR_v_HomSpdLim_Value: accessed-variable=VePRXR_v_HomSpdLim.Value
          data-send-points:
            25 x access:
              OUT_VePLTR_b_CrsCntrlActv_Value: accessed-variable=VePLTR_b_CrsCntrlActv.Value
              OUT_VePLTR_phi_EstSlopeAngle_Value: accessed-variable=VePLTR_phi_EstSlopeAngle.Value
              OUT_VePLTR_b_EstSlopeAngleFA_Value: accessed-variable=VePLTR_b_EstSlopeAngleFA.Value
              OUT_VePLTR_phi_EstRollAngleAtZeroSpd_Value: accessed-variable=VePLTR_phi_EstRollAngleAtZeroSpd.Value
              OUT_VePLTR_b_EstRollAngleAtZeroSpdFA_Value: accessed-variable=VePLTR_b_EstRollAngleAtZeroSpdFA.Value
              OUT_VePLTR_Pct_EstSlopeAnglePct_Value: accessed-variable=VePLTR_Pct_EstSlopeAnglePct.Value
              OUT_VePLTR_b_ProxiCC_Value: accessed-variable=VePLTR_b_ProxiCC.Value
              OUT_VePLTR_b_ProxiSpdLimiter_Value: accessed-variable=VePLTR_b_ProxiSpdLimiter.Value
              OUT_VePLTR_b_ProxiNAVPrsnc_Value: accessed-variable=VePLTR_b_ProxiNAVPrsnc.Value
              OUT_VePLTR_b_ProxiTrafficSignRcgntn_Value: accessed-variable=VePLTR_b_ProxiTrafficSignRcgntn.Value
              OUT_VePLTR_b_RRCCPROXI_Value: accessed-variable=VePLTR_b_RRCCPROXI.Value
              OUT_VePLTR_b_ProxiCADM_Value: accessed-variable=VePLTR_b_ProxiCADM.Value
              OUT_VePLTR_b_ProxiCADM2_Value: accessed-variable=VePLTR_b_ProxiCADM2.Value
              OUT_VePLTR_b_Hill_Des_Stat_Prx_Value: accessed-variable=VePLTR_b_Hill_Des_Stat_Prx.Value
              OUT_VePLTR_e_VehicleCountryCode_Value: accessed-variable=VePLTR_e_VehicleCountryCode.Value
              OUT_VePLTR_e_ShiftIndSt_Value: accessed-variable=VePLTR_e_ShiftIndSt.Value
              OUT_VePLTR_e_ProxiACC_Value: accessed-variable=VePLTR_e_ProxiACC.Value
              OUT_VePLTR_e_ProxiIncreasingSpdCnst_Value: accessed-variable=VePLTR_e_ProxiIncreasingSpdCnst.Value
              OUT_VePLTR_e_ProxyHybridType_Value: accessed-variable=VePLTR_e_ProxyHybridType.Value
              OUT_VePLTR_e_VehCategory_Value: accessed-variable=VePLTR_e_VehCategory.Value
              OUT_VePLTR_e_Proxi_Autonomy_Lvl_Value: accessed-variable=VePLTR_e_Proxi_Autonomy_Lvl.Value
              OUT_VePLTR_e_Proxi_CC_Logic_Value: accessed-variable=VePLTR_e_Proxi_CC_Logic.Value
              OUT_VePLTR_Pct_ProxiSpdomtrTol_Value: accessed-variable=VePLTR_Pct_ProxiSpdomtrTol.Value
              OUT_VePLTR_v_HomSpdLim_Value: accessed-variable=VePLTR_v_HomSpdLim.Value
              OUT_VePLTR_b_SpeedUnit_Value: accessed-variable=VePLTR_b_SpeedUnit.Value
          read-local-variables:
            13 x access:
              RV_OutTorqReqModHH_write_IRV: accessed-variable=OutTorqReqModHH_write_IRV
              RV_VePLTR_a_LongAccelOffset_write_IRV: accessed-variable=VePLTR_a_LongAccelOffset_write_IRV
              RV_VePLTR_a_LongAccel_write_IRV: accessed-variable=VePLTR_a_LongAccel_write_IRV
              RV_VePLTR_a_TransAccelOffset_write_IRV: accessed-variable=VePLTR_a_TransAccelOffset_write_IRV
              RV_VePLTR_a_TransAccel_write_IRV: accessed-variable=VePLTR_a_TransAccel_write_IRV
              RV_VePLTR_b_ACCEnbledInit_write_IRV: accessed-variable=VePLTR_b_ACCEnbledInit_write_IRV
              RV_VePLTR_b_CrsCntrlActv_write_IRV: accessed-variable=VePLTR_b_CrsCntrlActv_write_IRV
              RV_VePLTR_b_LongAccelFA_write_IRV: accessed-variable=VePLTR_b_LongAccelFA_write_IRV
              RV_VePLTR_b_LongAccelOffsetFA_write_IRV: accessed-variable=VePLTR_b_LongAccelOffsetFA_write_IRV
              RV_VePLTR_b_SpeedUnit_Init_write_IRV: accessed-variable=VePLTR_b_SpeedUnit_Init_write_IRV
              RV_VePLTR_b_TransAccelFA_write_IRV: accessed-variable=VePLTR_b_TransAccelFA_write_IRV
              RV_VePLTR_b_TransAccelOffsetFA_write_IRV: accessed-variable=VePLTR_b_TransAccelOffsetFA_write_IRV
              RV_VehSpd_write_IRV: accessed-variable=VehSpd_write_IRV
        PLTR_MedTED
          data-receive-point-by-arguments:
            access IN_VeTRGR_b_BrakeFA_Value: accessed-variable=VeTRGR_b_BrakeFA.Value
            access IN_VeTRGR_b_BrkApplied_Value: accessed-variable=VeTRGR_b_BrkApplied.Value
            access IN_VeTRGR_e_VldtdTransRngSt_Value: accessed-variable=VeTRGR_e_VldtdTransRngSt.Value
          data-send-points:
            16 x access:
              OUT_VePLTR_e_ESMTransRngSt_Value: accessed-variable=VePLTR_e_ESMTransRngSt.Value
              OUT_VePLTR_e_AutoPosCorrMd_Value: accessed-variable=VePLTR_e_AutoPosCorrMd.Value
              OUT_VePLTR_b_ShftLckFlt_Value: accessed-variable=VePLTR_b_ShftLckFlt.Value
              OUT_VePLTR_b_RackFaultFA_Value: accessed-variable=VePLTR_b_RackFaultFA.Value
              OUT_VePLTR_b_ShftSnsFA_Value: accessed-variable=VePLTR_b_ShftSnsFA.Value
              OUT_VePLTR_b_ShiftDspFlt_Value: accessed-variable=VePLTR_b_ShiftDspFlt.Value
              OUT_VePLTR_y_GatedParkSwFlt_Value: accessed-variable=VePLTR_y_GatedParkSwFlt.Value
              OUT_VePLTR_e_ShiftLeverPosReq_Value: accessed-variable=VePLTR_e_ShiftLeverPosReq.Value
              OUT_VePLTR_b_ShiftLeverFailSts_Value: accessed-variable=VePLTR_b_ShiftLeverFailSts.Value
              OUT_VePLTR_b_PRNDFailSts_Value: accessed-variable=VePLTR_b_PRNDFailSts.Value
              OUT_VePLTR_b_RFHub_ForcePark_Value: accessed-variable=VePLTR_b_RFHub_ForcePark.Value
              OUT_VePLTR_e_RationalisedRngSt_Value: accessed-variable=VePLTR_e_RationalisedRngSt.Value
              OUT_VePLTR_e_ValidatePstn_Value: accessed-variable=VePLTR_e_ValidatePstn.Value
              OUT_VePLTR_b_ManualMode_Value: accessed-variable=VePLTR_b_ManualMode.Value
              OUT_VePLTR_b_DriverDetected_Value: accessed-variable=VePLTR_b_DriverDetected.Value
              OUT_VePLTR_b_DAI_Enbl_Value: accessed-variable=VePLTR_b_DAI_Enbl.Value
          read-local-variables:
            45 x access:
              RV_AutoPosCorrMd_Ini_write_IRV: accessed-variable=AutoPosCorrMd_Ini_write_IRV
              RV_AutoPosCorrMd_Init_write_IRV: accessed-variable=AutoPosCorrMd_Init_write_IRV
              RV_DriverDetected_write_IRV: accessed-variable=DriverDetected_write_IRV
              RV_DrvrSeatSnsrSts_Init_write_IRV: accessed-variable=DrvrSeatSnsrSts_Init_write_IRV
              RV_DrvrSeatSnsr_FailSts_Init_write_IRV: accessed-variable=DrvrSeatSnsr_FailSts_Init_write_IRV
              RV_HWIO_GatedParkSWFault_write_IRV: accessed-variable=HWIO_GatedParkSWFault_write_IRV
              RV_ManualMode_Init_write_IRV: accessed-variable=ManualMode_Init_write_IRV
              RV_PRND_ValidatePstn_InitSndry_write_IRV: accessed-variable=PRND_ValidatePstn_InitSndry_write_IRV
              RV_PRND_ValidatePstn_Init_write_IRV: accessed-variable=PRND_ValidatePstn_Init_write_IRV
              RV_RFHUB_ForcePark_Init_PwrOn_1_IRV_IRV: accessed-variable=RFHUB_ForcePark_Init_PwrOn_1_IRV_IRV
              RV_RFHub_ForcePark_Init_write_IRV: accessed-variable=RFHub_ForcePark_Init_write_IRV
              RV_ShiftLeverPositionReq_Ini_write_IRV: accessed-variable=ShiftLeverPositionReq_Ini_write_IRV
              RV_ShiftLeverPositionReq_Init_write_IRV: accessed-variable=ShiftLeverPositionReq_Init_write_IRV
              RV_TransShiftPosInitMSG_write_IRV: accessed-variable=TransShiftPosInitMSG_write_IRV
              RV_TransShiftPos_InitMSG_write_IRV: accessed-variable=TransShiftPos_InitMSG_write_IRV
              RV_VePLTR_b_DoorFailSts_Init_write_IRV: accessed-variable=VePLTR_b_DoorFailSts_Init_write_IRV
              RV_VePLTR_b_DriverDoorOnOffSts_FA_IRV: accessed-variable=VePLTR_b_DriverDoorOnOffSts_FA_IRV
              RV_VePLTR_b_DriverSeatBeltStsFA_write_IRV: accessed-variable=VePLTR_b_DriverSeatBeltStsFA_write_IRV
              RV_VePLTR_b_DrvDrAjar_write_IRV: accessed-variable=VePLTR_b_DrvDrAjar_write_IRV
              RV_VePLTR_b_DrvrSeatSnsrSts_FA_write_IRV: accessed-variable=VePLTR_b_DrvrSeatSnsrSts_FA_write_IRV
              RV_VePLTR_b_Prmry_AutoPosCorrMdFA_write_IRV: accessed-variable=VePLTR_b_Prmry_AutoPosCorrMdFA_write_IRV
              RV_VePLTR_b_Prmry_ForceParkFA_write_IRV: accessed-variable=VePLTR_b_Prmry_ForceParkFA_write_IRV
              RV_VePLTR_b_Prmry_ManualModeFA_write_IRV: accessed-variable=VePLTR_b_Prmry_ManualModeFA_write_IRV
              RV_VePLTR_b_Prmry_PRNDFailStsFA_write_IRV: accessed-variable=VePLTR_b_Prmry_PRNDFailStsFA_write_IRV
              RV_VePLTR_b_Prmry_PRND_ValidatePstnFA_write_IRV: accessed-variable=VePLTR_b_Prmry_PRND_ValidatePstnFA_write_IRV
              RV_VePLTR_b_Prmry_RackDetentSensorFAFA_write_IRV: accessed-variable=VePLTR_b_Prmry_RackDetentSensorFAFA_write_IRV
              RV_VePLTR_b_Prmry_ShiftLeverFailStsFA_write_IRV: accessed-variable=VePLTR_b_Prmry_ShiftLeverFailStsFA_write_IRV
              RV_VePLTR_b_Prmry_ShiftLeverPositionReqFA_write_IRV: accessed-variable=VePLTR_b_Prmry_ShiftLeverPositionReqFA_write_IRV
              RV_VePLTR_b_Prmry_ShiftLockFAFA_write_IRV: accessed-variable=VePLTR_b_Prmry_ShiftLockFAFA_write_IRV
              RV_VePLTR_b_Prmry_ShiftSnsFAFA_write_IRV: accessed-variable=VePLTR_b_Prmry_ShiftSnsFAFA_write_IRV
              RV_VePLTR_b_Prmry_ShifterDispFAFA_write_IRV: accessed-variable=VePLTR_b_Prmry_ShifterDispFAFA_write_IRV
              RV_VePLTR_b_Prmry_TransShiftPstnFA_write_IRV: accessed-variable=VePLTR_b_Prmry_TransShiftPstnFA_write_IRV
              RV_VePLTR_b_Scndry_AutoPosCorrMdFA_write_IRV: accessed-variable=VePLTR_b_Scndry_AutoPosCorrMdFA_write_IRV
              RV_VePLTR_b_Scndry_ForceParkFA_write_IRV: accessed-variable=VePLTR_b_Scndry_ForceParkFA_write_IRV
              RV_VePLTR_b_Scndry_PRNDFailStsFA_write_IRV: accessed-variable=VePLTR_b_Scndry_PRNDFailStsFA_write_IRV
              RV_VePLTR_b_Scndry_PRND_ValidatePstnFA_write_IRV: accessed-variable=VePLTR_b_Scndry_PRND_ValidatePstnFA_write_IRV
              RV_VePLTR_b_Scndry_RackDetentSensorFAFA_write_IRV: accessed-variable=VePLTR_b_Scndry_RackDetentSensorFAFA_write_IRV
              RV_VePLTR_b_Scndry_ShiftLeverFailStsFA_write_IRV: accessed-variable=VePLTR_b_Scndry_ShiftLeverFailStsFA_write_IRV
              RV_VePLTR_b_Scndry_ShiftLeverPositionReqFA_write_IRV: accessed-variable=VePLTR_b_Scndry_ShiftLeverPositionReqFA_write_IRV
              RV_VePLTR_b_Scndry_ShiftLockFAFA_write_IRV: accessed-variable=VePLTR_b_Scndry_ShiftLockFAFA_write_IRV
              RV_VePLTR_b_Scndry_ShiftSnsFAFA_write_IRV: accessed-variable=VePLTR_b_Scndry_ShiftSnsFAFA_write_IRV
              RV_VePLTR_b_Scndry_ShifterDispFAFA_write_IRV: accessed-variable=VePLTR_b_Scndry_ShifterDispFAFA_write_IRV
              RV_VePLTR_b_Scndry_TransShiftPstnFA_write_IRV: accessed-variable=VePLTR_b_Scndry_TransShiftPstnFA_write_IRV
              RV_VePLTR_e_DriverDoorOnOffSts_Init_IRV: accessed-variable=VePLTR_e_DriverDoorOnOffSts_Init_IRV
              RV_VePLTR_e_DriverSeatBeltSts_write_IRV: accessed-variable=VePLTR_e_DriverSeatBeltSts_write_IRV
          written-local-variables:
            access WV_DriverDetected_write_IRV: accessed-variable=DriverDetected_write_IRV
        PLTR_MedTEH
          data-receive-point-by-arguments:
            7 x access:
              IN_VeDFIB_b_RTCChipErr_Value: accessed-variable=VeDFIB_b_RTCChipErr.Value
              IN_VeDFIR_b_ClearTrackingInfoService04_Value: accessed-variable=VeDFIR_b_ClearTrackingInfoService04.Value
              IN_VeDFIR_b_DsblDiagFailSafe_Value: accessed-variable=VeDFIR_b_DsblDiagFailSafe.Value
              IN_VeDFIR_b_IsDiagGlobalConditionsValid_Value: accessed-variable=VeDFIR_b_IsDiagGlobalConditionsValid.Value
              IN_VeDFIR_b_PostCodeClrDiagDsbl_Value: accessed-variable=VeDFIR_b_PostCodeClrDiagDsbl.Value
              IN_VeDMAB_y_StatusByte_IgnKeyOffTmrPerfTooFast_Value: accessed-variable=VeDMAB_y_StatusByte_IgnKeyOffTmrPerfTooFast.Value
              IN_VeENGR_V_FuelConsumption_Value: accessed-variable=VeENGR_V_FuelConsumption.Value
          data-send-points:
            4 x access:
              OUT_VePLTR_dVh_FuelConsumption_avrg_Value: accessed-variable=VePLTR_dVh_FuelConsumption_avrg.Value
              OUT_VePLTR_b_ClrTrackingInfo_Value: accessed-variable=VePLTR_b_ClrTrackingInfo.Value
              OUT_VePLTR_pmbar_AmbientAirPrs_Value: accessed-variable=VePLTR_pmbar_AmbientAirPrs.Value
              OUT_VePLTR_e_FaultSts_IgnKeyOffTmrPerfTooFast_Value: accessed-variable=VePLTR_e_FaultSts_IgnKeyOffTmrPerfTooFast.Value
          read-local-variables:
            access RV_Toggle_1s_write_IRV: accessed-variable=Toggle_1s_write_IRV
            access RV_VePLTR_e_RTCTestSyncReport_Init_IRV: accessed-variable=VePLTR_e_RTCTestSyncReport_Init_IRV
            access RV_VePLTR_p_AmbientAirPrs_write_IRV: accessed-variable=VePLTR_p_AmbientAirPrs_write_IRV
          written-local-variables:
            access WV_VePLTR_b_RTCFltDtctd_IRV: accessed-variable=VePLTR_b_RTCFltDtctd_IRV
        PLTR_SlowTEF
          data-receive-point-by-arguments:
            14 x access:
              IN_VeAPMR_t_EPOCHTime_Value: accessed-variable=VeAPMR_t_EPOCHTime.Value
              IN_VeAPSR_Pct_AccelPedalActPosition_Value: accessed-variable=VeAPSR_Pct_AccelPedalActPosition.Value
              IN_VeBPCR_b_HVBatRealTimeClock_FA_Value: accessed-variable=VeBPCR_b_HVBatRealTimeClock_FA.Value
              IN_VeBPCR_t_HVBatRealTimeClock_Value: accessed-variable=VeBPCR_t_HVBatRealTimeClock.Value
              IN_VeBPCR_t_HVBatSleepTime_Value: accessed-variable=VeBPCR_t_HVBatSleepTime.Value
              IN_VeCSVR_v_VehSpdSigned_Value: accessed-variable=VeCSVR_v_VehSpdSigned.Value
              IN_VeDFIB_b_RTCChipErr_Value: accessed-variable=VeDFIB_b_RTCChipErr.Value
              IN_VeDFIB_e_RTCReadSts_Value: accessed-variable=VeDFIB_e_RTCReadSts.Value
              IN_VeDFIR_b_DsblDiagFailSafe_Value: accessed-variable=VeDFIR_b_DsblDiagFailSafe.Value
              IN_VeDFIR_b_IsDiagGlobalConditionsValid_Value: accessed-variable=VeDFIR_b_IsDiagGlobalConditionsValid.Value
              IN_VeDFIR_b_PostCodeClrDiagDsbl_Value: accessed-variable=VeDFIR_b_PostCodeClrDiagDsbl.Value
              IN_VeDMAB_y_StatusByte_ECUInplantmodeAct_Value: accessed-variable=VeDMAB_y_StatusByte_ECUInplantmodeAct.Value
              IN_VeHPMR_b_PropSysActv_Value: accessed-variable=VeHPMR_b_PropSysActv.Value
              IN_VeHTDR_M_OutTorqReqModHH_Value: accessed-variable=VeHTDR_M_OutTorqReqModHH.Value
          data-send-points:
            17 x access:
              OUT_VePLTR_b_InFieldMode_Value: accessed-variable=VePLTR_b_InFieldMode.Value
              OUT_VePLTR_e_ShippingMode_Value: accessed-variable=VePLTR_e_ShippingMode.Value
              OUT_VePLTR_milel_InPlntMileageLmt_Miles_Value: accessed-variable=VePLTR_milel_InPlntMileageLmt_Miles.Value
              OUT_VePLTR_milel_Odometer_Miles_Value: accessed-variable=VePLTR_milel_Odometer_Miles.Value
              OUT_VePLTR_milel_IPEETestMileageLimit_Value: accessed-variable=VePLTR_milel_IPEETestMileageLimit.Value
              OUT_VePLTR_b_WarmupAchieved_Value: accessed-variable=VePLTR_b_WarmupAchieved.Value
              OUT_VePLTR_t_RTC_CurrentTime_Value: accessed-variable=VePLTR_t_RTC_CurrentTime.Value
              OUT_VePLTR_b_RTC_CurrentTimeFA_Value: accessed-variable=VePLTR_b_RTC_CurrentTimeFA.Value
              OUT_VePLTR_t_RTC_SleepTime_Value: accessed-variable=VePLTR_t_RTC_SleepTime.Value
              OUT_VePLTR_e_FaultSts_ECUInplantmodeAct_Value: accessed-variable=VePLTR_e_FaultSts_ECUInplantmodeAct.Value
              OUT_AePLTR_b_InFieldMode_AePLTR_b_InFieldMode: accessed-variable=AePLTR_b_InFieldMode.AePLTR_b_InFieldMode
              OUT_VePLTR_b_FuelLevelLowClster_Value: accessed-variable=VePLTR_b_FuelLevelLowClster.Value
              OUT_VePLTR_t_HCPOffTime_Value: accessed-variable=VePLTR_t_HCPOffTime.Value
              OUT_VePLTR_b_HCPOffTimeFA_Value: accessed-variable=VePLTR_b_HCPOffTimeFA.Value
              OUT_AePLTR_milel_OdometerLimit_AePLTR_milel_OdometerLimit: accessed-variable=AePLTR_milel_OdometerLimit.AePLTR_milel_OdometerLimit
              OUT_VePLTR_b_BatteryWasDisconnected_Value: accessed-variable=VePLTR_b_BatteryWasDisconnected.Value
              OUT_VePLTR_e_ECMVtdFreeze_Value: accessed-variable=VePLTR_e_ECMVtdFreeze.Value
          read-local-variables:
            16 x access:
              RV_FuelLevelLowClster_Init_write_IRV: accessed-variable=FuelLevelLowClster_Init_write_IRV
              RV_VePLTI_b_RTC_CurrentTimeFA_Init_write_IRV: accessed-variable=VePLTI_b_RTC_CurrentTimeFA_Init_write_IRV
              RV_VePLTI_e_ShippingMode_write_IRV: accessed-variable=VePLTI_e_ShippingMode_write_IRV
              RV_VePLTI_kl_Odometer_Km_write_IRV: accessed-variable=VePLTI_kl_Odometer_Km_write_IRV
              RV_VePLTR_b_BatteryWasDisconnected_Init_write_IRV: accessed-variable=VePLTR_b_BatteryWasDisconnected_Init_write_IRV
              RV_VePLTR_b_GPS_Date_DayFA_write_IRV: accessed-variable=VePLTR_b_GPS_Date_DayFA_write_IRV
              RV_VePLTR_b_GPS_Date_MonthFA_write_IRV: accessed-variable=VePLTR_b_GPS_Date_MonthFA_write_IRV
              RV_VePLTR_b_GPS_Date_YearFA_write_IRV: accessed-variable=VePLTR_b_GPS_Date_YearFA_write_IRV
              RV_VePLTR_b_GPS_UTC_HourFA_write_IRV: accessed-variable=VePLTR_b_GPS_UTC_HourFA_write_IRV
              RV_VePLTR_b_GPS_UTC_MinuteFA_write_IRV: accessed-variable=VePLTR_b_GPS_UTC_MinuteFA_write_IRV
              RV_VePLTR_b_GPS_UTC_SecondFA_write_IRV: accessed-variable=VePLTR_b_GPS_UTC_SecondFA_write_IRV
              RV_VePLTR_b_RTCFltDtctd_IRV: accessed-variable=VePLTR_b_RTCFltDtctd_IRV
              RV_VePLTR_e_ECMVtdFreezeInit_write_IRV: accessed-variable=VePLTR_e_ECMVtdFreezeInit_write_IRV
              RV_VePLTR_t_GPS_UTC_Second_PwrOn_IRV: accessed-variable=VePLTR_t_GPS_UTC_Second_PwrOn_IRV
              RV_VePLTR_thr_GPS_UTC_Hour_PwrOn_IRV: accessed-variable=VePLTR_thr_GPS_UTC_Hour_PwrOn_IRV
              RV_VePLTR_tmn_GPS_UTC_Minute_PwrOn_IRV: accessed-variable=VePLTR_tmn_GPS_UTC_Minute_PwrOn_IRV
          written-local-variables:
            7 x access:
              WV_HVBatRealTimeClock_BPCM_write_IRV: accessed-variable=HVBatRealTimeClock_BPCM_write_IRV
              WV_HVBatRealTimeClock_FA_BPCM_write_IRV: accessed-variable=HVBatRealTimeClock_FA_BPCM_write_IRV
              WV_HVBatSleepTime_BPCM_write_IRV: accessed-variable=HVBatSleepTime_BPCM_write_IRV
              WV_OutTorqReqModHH_write_IRV: accessed-variable=OutTorqReqModHH_write_IRV
              WV_Toggle_1s_write_IRV: accessed-variable=Toggle_1s_write_IRV
              WV_VePLTR_e_RTCTestSyncReport_Init_IRV: accessed-variable=VePLTR_e_RTCTestSyncReport_Init_IRV
              WV_VehSpd_write_IRV: accessed-variable=VehSpd_write_IRV
        PLTR_PwrOff
          data-send-points:
            6 x access:
              OUT_EePLTR_t_RTCTime_EePLTR_t_RTCTime: accessed-variable=EePLTR_t_RTCTime.EePLTR_t_RTCTime
              OUT_EePLTR_e_RTCStatus_EePLTR_e_RTCStatus: accessed-variable=EePLTR_e_RTCStatus.EePLTR_e_RTCStatus
              OUT_EePLTR_t_PowerdownTime_EePLTR_t_PowerdownTime: accessed-variable=EePLTR_t_PowerdownTime.EePLTR_t_PowerdownTime
              OUT_EePLTR_e_ShippingMode_EePLTR_e_ShippingMode: accessed-variable=EePLTR_e_ShippingMode.EePLTR_e_ShippingMode
              OUT_AePLTR_b_PwrOffOk_AePLTR_b_PwrOffOk: accessed-variable=AePLTR_b_PwrOffOk.AePLTR_b_PwrOffOk
              OUT_EePLTR_b_RTC_CurrentTimeFA_EePLTR_b_RTC_CurrentTimeFA: accessed-variable=EePLTR_b_RTC_CurrentTimeFA.EePLTR_b_RTC_CurrentTimeFA
        DidWrite_RWD9E3B_IPEETstMilgeLmt
          data-receive-point-by-arguments:
            access IN_VeDCAB_milel_RWD9E3B_IPEETstMilgeLmt_Value: accessed-variable=VeDCAB_milel_RWD9E3B_IPEETstMilgeLmt.Value
          data-send-points:
            access OUT_AePLTR_milel_IPEETestMileageLimit_AePLTR_milel_IPEETestMileageLimit: accessed-variable=AePLTR_milel_IPEETestMileageLimit.AePLTR_milel_IPEETestMileageLimit
        DidWrite_RWD3025_HCPModEnblr_PLTR
          data-receive-point-by-arguments:
            access IN_VeDCAB_b_RWD3025_InFieldMode_Value: accessed-variable=VeDCAB_b_RWD3025_InFieldMode.Value
            access IN_VeDCAB_b_RWD3025_REMDisabled_Value: accessed-variable=VeDCAB_b_RWD3025_REMDisabled.Value
            access IN_VeDCAB_b_RWD3025_RadFanHandshake_disbld_Value: accessed-variable=VeDCAB_b_RWD3025_RadFanHandshake_disbld.Value
          data-send-points:
            5 x access:
              OUT_AePLTR_b_InFieldMode_AePLTR_b_InFieldMode: accessed-variable=AePLTR_b_InFieldMode.AePLTR_b_InFieldMode
              OUT_VePLTR_b_RadFanHndShk_dsbld_Value: accessed-variable=VePLTR_b_RadFanHndShk_dsbld.Value
              OUT_VePLTR_b_REMDisabled_Value: accessed-variable=VePLTR_b_REMDisabled.Value
              OUT_AePLTR_b_RadFanHandshake_disbld_AePLTR_b_RadFanHandshake_disbld: accessed-variable=AePLTR_b_RadFanHandshake_disbld.AePLTR_b_RadFanHandshake_disbld
              OUT_AePLTR_b_REMDisabled_AePLTR_b_REMDisabled: accessed-variable=AePLTR_b_REMDisabled.AePLTR_b_REMDisabled
        DidWrite_RWD9EEB_InPlant_SOC_Setpoint
          data-receive-point-by-arguments:
            access IN_VeDCAB_Pct_RWD9EEB_InPlant_SOC_Setpoint_Value: accessed-variable=VeDCAB_Pct_RWD9EEB_InPlant_SOC_Setpoint.Value
          data-send-points:
            access OUT_VePLTR_Pct_InPlant_SOCSetPt_Value: accessed-variable=VePLTR_Pct_InPlant_SOCSetPt.Value
            access OUT_AePLTR_Pct_IP_SOCSetPt_AePLTR_Pct_IP_SOCSetPt: accessed-variable=AePLTR_Pct_IP_SOCSetPt.AePLTR_Pct_IP_SOCSetPt
        DidWrite_RWD9EEC_REM_Logistics_SOC_Setpoint
          data-receive-point-by-arguments:
            access IN_VeDCAB_Pct_RWD9EEC_REM_Logistics_SOC_Setpoint_Value: accessed-variable=VeDCAB_Pct_RWD9EEC_REM_Logistics_SOC_Setpoint.Value
          data-send-points:
            access OUT_VePLTR_Pct_REMLogisticSOCSetPt_Value: accessed-variable=VePLTR_Pct_REMLogisticSOCSetPt.Value
            access OUT_AePLTR_Pct_CS_SOCSetPt_AePLTR_Pct_CS_SOCSetPt: accessed-variable=AePLTR_Pct_CS_SOCSetPt.AePLTR_Pct_CS_SOCSetPt
        FsftPLTR_Pct_Slope
          data-send-points:
            access OUT_VePLTR_b_Slope_FA_Value: accessed-variable=VePLTR_b_Slope_FA.Value
        FsftPLTR_a_LongAccel
          data-send-points:
            access OUT_VePLTR_a_LongAccel_Value: accessed-variable=VePLTR_a_LongAccel.Value
            access OUT_VePLTR_b_LongAccelFA_Value: accessed-variable=VePLTR_b_LongAccelFA.Value
          written-local-variables:
            access WV_VePLTR_a_LongAccel_write_IRV: accessed-variable=VePLTR_a_LongAccel_write_IRV
            access WV_VePLTR_b_LongAccelFA_write_IRV: accessed-variable=VePLTR_b_LongAccelFA_write_IRV
        FsftPLTR_a_LongAccelOffset
          data-send-points:
            access OUT_VePLTR_a_LongAccelOffset_Value: accessed-variable=VePLTR_a_LongAccelOffset.Value
          written-local-variables:
            access WV_VePLTR_a_LongAccelOffset_write_IRV: accessed-variable=VePLTR_a_LongAccelOffset_write_IRV
            access WV_VePLTR_b_LongAccelOffsetFA_write_IRV: accessed-variable=VePLTR_b_LongAccelOffsetFA_write_IRV
        FsftPLTR_a_TransAccel
          data-send-points:
            access OUT_VePLTR_a_LatAccel_Value: accessed-variable=VePLTR_a_LatAccel.Value
            access OUT_VePLTR_b_LatAccelFA_Value: accessed-variable=VePLTR_b_LatAccelFA.Value
          written-local-variables:
            access WV_VePLTR_a_TransAccel_write_IRV: accessed-variable=VePLTR_a_TransAccel_write_IRV
            access WV_VePLTR_b_TransAccelFA_write_IRV: accessed-variable=VePLTR_b_TransAccelFA_write_IRV
        FsftPLTR_a_TransAccelOffset
          written-local-variables:
            access WV_VePLTR_a_TransAccelOffset_write_IRV: accessed-variable=VePLTR_a_TransAccelOffset_write_IRV
            access WV_VePLTR_b_TransAccelOffsetFA_write_IRV: accessed-variable=VePLTR_b_TransAccelOffsetFA_write_IRV
        FsftPLTR_b_ACC_On
          data-send-points:
            access OUT_VePLTR_b_ACC_OnFA_Value: accessed-variable=VePLTR_b_ACC_OnFA.Value
        FsftPLTR_b_ASCM_Srv
          data-send-points:
            access OUT_VePLTR_b_ASCM_Srv_FA_Value: accessed-variable=VePLTR_b_ASCM_Srv_FA.Value
        FsftPLTR_b_ASCM_SysFail
          data-send-points:
            access OUT_VePLTR_b_ASCM_SysFail_FA_Value: accessed-variable=VePLTR_b_ASCM_SysFail_FA.Value
        FsftPLTR_b_ASCM_SysSys
          data-send-points:
            access OUT_VePLTR_b_ADS_SrvSys_FA_Value: accessed-variable=VePLTR_b_ADS_SrvSys_FA.Value
        FsftPLTR_b_ChargeReq
          data-send-points:
            access OUT_VePLTR_b_ChargeReq_Value: accessed-variable=VePLTR_b_ChargeReq.Value
            access OUT_VePLTR_b_ChargeReqSgnlRcvd_Value: accessed-variable=VePLTR_b_ChargeReqSgnlRcvd.Value
        FsftPLTR_b_DrvDrAjar
          data-send-points:
            access OUT_VePLTR_b_DrvDrAjarFA_Value: accessed-variable=VePLTR_b_DrvDrAjarFA.Value
        FsftPLTR_b_EPBFailSts
          data-send-points:
            access OUT_VePLTR_b_EPBFailSts_Value: accessed-variable=VePLTR_b_EPBFailSts.Value
        FsftPLTR_b_ESSActvEBrake
        FsftPLTR_b_ESSRqShftPark
          data-send-points:
            access OUT_VePLTR_b_ESSRqShftPark_Value: accessed-variable=VePLTR_b_ESSRqShftPark.Value
        FsftPLTR_b_HDCEnabledCAN
          data-send-points:
            access OUT_VePLTR_b_HDCEnabledCAN_Value: accessed-variable=VePLTR_b_HDCEnabledCAN.Value
            access OUT_VePLTR_b_HDCEnabledCAN_FA_Value: accessed-variable=VePLTR_b_HDCEnabledCAN_FA.Value
        FsftPLTR_b_ImmoParkReq
          data-send-points:
            access OUT_VePLTR_b_ImmoParkReq_Value: accessed-variable=VePLTR_b_ImmoParkReq.Value
        FsftPLTR_b_Inverter_PowerDraw
          data-send-points:
            access OUT_VePLTR_b_Inverter_PowerDraw_FA_Value: accessed-variable=VePLTR_b_Inverter_PowerDraw_FA.Value
        FsftPLTR_b_LHRDoorSts
          data-send-points:
            access OUT_VePLTR_b_LHRDoorSts_FA_Value: accessed-variable=VePLTR_b_LHRDoorSts_FA.Value
        FsftPLTR_b_MILOnRq_ESC
          data-send-points:
            access OUT_VePLTR_b_MILOnRq_ESC_Value: accessed-variable=VePLTR_b_MILOnRq_ESC.Value
        FsftPLTR_b_ParkBrakeSts
          data-send-points:
            access OUT_VePLTR_b_ParkBrakeSts_FA_Value: accessed-variable=VePLTR_b_ParkBrakeSts_FA.Value
        FsftPLTR_b_Prmry_AutoPosCorrMd
          written-local-variables:
            access WV_VePLTR_b_Prmry_AutoPosCorrMdFA_write_IRV: accessed-variable=VePLTR_b_Prmry_AutoPosCorrMdFA_write_IRV
        FsftPLTR_b_Prmry_ForcePark
          written-local-variables:
            access WV_VePLTR_b_Prmry_ForceParkFA_write_IRV: accessed-variable=VePLTR_b_Prmry_ForceParkFA_write_IRV
        FsftPLTR_b_Prmry_ManualMode
          written-local-variables:
            access WV_VePLTR_b_Prmry_ManualModeFA_write_IRV: accessed-variable=VePLTR_b_Prmry_ManualModeFA_write_IRV
        FsftPLTR_b_Prmry_PRNDFailSts
          written-local-variables:
            access WV_VePLTR_b_Prmry_PRNDFailStsFA_write_IRV: accessed-variable=VePLTR_b_Prmry_PRNDFailStsFA_write_IRV
        FsftPLTR_b_Prmry_PRND_ValidatePstn
          written-local-variables:
            access WV_VePLTR_b_Prmry_PRND_ValidatePstnFA_write_IRV: accessed-variable=VePLTR_b_Prmry_PRND_ValidatePstnFA_write_IRV
        FsftPLTR_b_Prmry_RackDetentSensorFA
          written-local-variables:
            access WV_VePLTR_b_Prmry_RackDetentSensorFAFA_write_IRV: accessed-variable=VePLTR_b_Prmry_RackDetentSensorFAFA_write_IRV
        FsftPLTR_b_Prmry_ShiftLeverFailSts
          written-local-variables:
            access WV_VePLTR_b_Prmry_ShiftLeverFailStsFA_write_IRV: accessed-variable=VePLTR_b_Prmry_ShiftLeverFailStsFA_write_IRV
        FsftPLTR_b_Prmry_ShiftLeverPositionReq
          written-local-variables:
            access WV_VePLTR_b_Prmry_ShiftLeverPositionReqFA_write_IRV: accessed-variable=VePLTR_b_Prmry_ShiftLeverPositionReqFA_write_IRV
        FsftPLTR_b_Prmry_ShiftLockFA
          written-local-variables:
            access WV_VePLTR_b_Prmry_ShiftLockFAFA_write_IRV: accessed-variable=VePLTR_b_Prmry_ShiftLockFAFA_write_IRV
        FsftPLTR_b_Prmry_ShiftSnsFA
          written-local-variables:
            access WV_VePLTR_b_Prmry_ShiftSnsFAFA_write_IRV: accessed-variable=VePLTR_b_Prmry_ShiftSnsFAFA_write_IRV
        FsftPLTR_b_Prmry_ShifterDispFA
          written-local-variables:
            access WV_VePLTR_b_Prmry_ShifterDispFAFA_write_IRV: accessed-variable=VePLTR_b_Prmry_ShifterDispFAFA_write_IRV
        FsftPLTR_b_Prmry_TransShiftPstn
          data-send-points:
            access OUT_VePLTR_b_Prmry_TransShiftPstnFA_Value: accessed-variable=VePLTR_b_Prmry_TransShiftPstnFA.Value
          written-local-variables:
            access WV_VePLTR_b_Prmry_TransShiftPstnFA_write_IRV: accessed-variable=VePLTR_b_Prmry_TransShiftPstnFA_write_IRV
        FsftPLTR_b_PsngrDoorSts
          data-send-points:
            access OUT_VePLTR_b_PsngrDoorSts_FA_Value: accessed-variable=VePLTR_b_PsngrDoorSts_FA.Value
        FsftPLTR_b_RHRDoorSts
          data-send-points:
            access OUT_VePLTR_b_RHRDoorSts_FA_Value: accessed-variable=VePLTR_b_RHRDoorSts_FA.Value
        FsftPLTR_b_RHatchSts
          data-send-points:
            access OUT_VePLTR_b_RHatchSts_FA_Value: accessed-variable=VePLTR_b_RHatchSts_FA.Value
        FsftPLTR_b_RmtVehStartReq
          data-send-points:
            access OUT_VePLTR_b_RmtVehStartReqFA_Value: accessed-variable=VePLTR_b_RmtVehStartReqFA.Value
        FsftPLTR_b_Scndry_AutoPosCorrMd
          written-local-variables:
            access WV_VePLTR_b_Scndry_AutoPosCorrMdFA_write_IRV: accessed-variable=VePLTR_b_Scndry_AutoPosCorrMdFA_write_IRV
        FsftPLTR_b_Scndry_ForcePark
          written-local-variables:
            access WV_VePLTR_b_Scndry_ForceParkFA_write_IRV: accessed-variable=VePLTR_b_Scndry_ForceParkFA_write_IRV
        FsftPLTR_b_Scndry_PRNDFailSts
          written-local-variables:
            access WV_VePLTR_b_Scndry_PRNDFailStsFA_write_IRV: accessed-variable=VePLTR_b_Scndry_PRNDFailStsFA_write_IRV
        FsftPLTR_b_Scndry_PRND_ValidatePstn
          written-local-variables:
            access WV_VePLTR_b_Scndry_PRND_ValidatePstnFA_write_IRV: accessed-variable=VePLTR_b_Scndry_PRND_ValidatePstnFA_write_IRV
        FsftPLTR_b_Scndry_RackDetentSensorFA
          written-local-variables:
            access WV_VePLTR_b_Scndry_RackDetentSensorFAFA_write_IRV: accessed-variable=VePLTR_b_Scndry_RackDetentSensorFAFA_write_IRV
        FsftPLTR_b_Scndry_ShiftLeverFailSts
          written-local-variables:
            access WV_VePLTR_b_Scndry_ShiftLeverFailStsFA_write_IRV: accessed-variable=VePLTR_b_Scndry_ShiftLeverFailStsFA_write_IRV
        FsftPLTR_b_Scndry_ShiftLeverPositionReq
          written-local-variables:
            access WV_VePLTR_b_Scndry_ShiftLeverPositionReqFA_write_IRV: accessed-variable=VePLTR_b_Scndry_ShiftLeverPositionReqFA_write_IRV
        FsftPLTR_b_Scndry_ShiftLockFA
          written-local-variables:
            access WV_VePLTR_b_Scndry_ShiftLockFAFA_write_IRV: accessed-variable=VePLTR_b_Scndry_ShiftLockFAFA_write_IRV
        FsftPLTR_b_Scndry_ShiftSnsFA
          written-local-variables:
            access WV_VePLTR_b_Scndry_ShiftSnsFAFA_write_IRV: accessed-variable=VePLTR_b_Scndry_ShiftSnsFAFA_write_IRV
        FsftPLTR_b_Scndry_ShifterDispFA
          written-local-variables:
            access WV_VePLTR_b_Scndry_ShifterDispFAFA_write_IRV: accessed-variable=VePLTR_b_Scndry_ShifterDispFAFA_write_IRV
        FsftPLTR_b_Scndry_TransShiftPstn
          data-send-points:
            access OUT_VePLTR_b_Scndry_TransShiftPstnFA_Value: accessed-variable=VePLTR_b_Scndry_TransShiftPstnFA.Value
          written-local-variables:
            access WV_VePLTR_b_Scndry_TransShiftPstnFA_write_IRV: accessed-variable=VePLTR_b_Scndry_TransShiftPstnFA_write_IRV
        FsftPLTR_b_Secure_Idle_Req
          data-send-points:
            access OUT_VePLTR_b_Secure_Idle_Req_FA_Value: accessed-variable=VePLTR_b_Secure_Idle_Req_FA.Value
        FsftPLTR_b_SpeedUnit
          data-send-points:
            access OUT_VePLTR_b_SpeedUnit_FA_Value: accessed-variable=VePLTR_b_SpeedUnit_FA.Value
        FsftPLTR_b_Worksite_Inverter_Active
          data-send-points:
            access OUT_VePLTR_b_Worksite_Inverter_Active_FA_Value: accessed-variable=VePLTR_b_Worksite_Inverter_Active_FA.Value
        FsftPLTR_e_ACCSystemSts
          data-send-points:
            access OUT_VePLTR_b_ACCSystemSts_FA_Value: accessed-variable=VePLTR_b_ACCSystemSts_FA.Value
        FsftPLTR_e_AEBSystemSts
          data-send-points:
            access OUT_VePLTR_b_AEBSystemSts_FA_Value: accessed-variable=VePLTR_b_AEBSystemSts_FA.Value
        FsftPLTR_e_ASCM_Stat
          data-send-points:
            access OUT_VePLTR_b_ASCM_Stat_FA_Value: accessed-variable=VePLTR_b_ASCM_Stat_FA.Value
        FsftPLTR_e_Command_15Sts
          data-send-points:
            access OUT_VePLTR_b_Command_15Sts_FA_Value: accessed-variable=VePLTR_b_Command_15Sts_FA.Value
        FsftPLTR_e_DriverDoorOnOffSts
          written-local-variables:
            access WV_VePLTR_b_DriverDoorOnOffSts_FA_IRV: accessed-variable=VePLTR_b_DriverDoorOnOffSts_FA_IRV
        FsftPLTR_e_DriverSeatBeltSts
          data-send-points:
            access OUT_VePLTR_e_DriverSeatBeltSts_Value: accessed-variable=VePLTR_e_DriverSeatBeltSts.Value
            access OUT_VePLTR_b_DriverSeatBeltStsFA_Value: accessed-variable=VePLTR_b_DriverSeatBeltStsFA.Value
          written-local-variables:
            access WV_VePLTR_b_DriverSeatBeltStsFA_write_IRV: accessed-variable=VePLTR_b_DriverSeatBeltStsFA_write_IRV
            access WV_VePLTR_e_DriverSeatBeltSts_write_IRV: accessed-variable=VePLTR_e_DriverSeatBeltSts_write_IRV
        FsftPLTR_e_DrvrSeatSnsrSts
          written-local-variables:
            access WV_VePLTR_b_DrvrSeatSnsrSts_FA_write_IRV: accessed-variable=VePLTR_b_DrvrSeatSnsrSts_FA_write_IRV
        FsftPLTR_e_EPBHoldSt
          data-send-points:
            access OUT_VePLTR_e_EPBHoldSts_Value: accessed-variable=VePLTR_e_EPBHoldSts.Value
            access OUT_VePLTR_b_EPBHoldStsFA_Value: accessed-variable=VePLTR_b_EPBHoldStsFA.Value
        FsftPLTR_e_ERS_SW
          data-send-points:
            access OUT_VePLTR_b_ERS_SWFA_Value: accessed-variable=VePLTR_b_ERS_SWFA.Value
        FsftPLTR_e_HAS_TelltaleSts
          data-send-points:
            access OUT_VePLTR_b_HAS_TelltaleSts_FA_Value: accessed-variable=VePLTR_b_HAS_TelltaleSts_FA.Value
        FsftPLTR_e_HiBmLvr_Stat
          data-send-points:
            access OUT_VePLTR_b_HiBmLvr_Stat_FA_Value: accessed-variable=VePLTR_b_HiBmLvr_Stat_FA.Value
        FsftPLTR_e_LSMDExtReleaseLockReq
        FsftPLTR_e_MRM_Status
          data-send-points:
            access OUT_VePLTR_b_MRM_Status_FA_Value: accessed-variable=VePLTR_b_MRM_Status_FA.Value
        FsftPLTR_e_MRM_Status_C2
          data-send-points:
            access OUT_VePLTR_e_MRM_Status_C2_FA_Value: accessed-variable=VePLTR_e_MRM_Status_C2_FA.Value
        FsftPLTR_e_ParkingGearShiftReq_BSM
          data-send-points:
            access OUT_VePLTR_b_ParkingGearShiftReq_BSM_FA_Value: accessed-variable=VePLTR_b_ParkingGearShiftReq_BSM_FA.Value
        FsftPLTR_e_SelectSpdSts
          data-send-points:
            access OUT_VePLTR_b_SelectSpdSts_FA_Value: accessed-variable=VePLTR_b_SelectSpdSts_FA.Value
        FsftPLTR_e_TowHaulMode
          data-send-points:
            access OUT_VePLTR_e_TowHaulMode_Value: accessed-variable=VePLTR_e_TowHaulMode.Value
        FsftPLTR_e_VehicleCountryCode
        FsftPLTR_e_eBurn_Stages
          data-send-points:
            access OUT_VePLTR_b_eBurn_Stages_FA_Value: accessed-variable=VePLTR_b_eBurn_Stages_FA.Value
        FsftPLTR_l_Odometer_Km
          data-send-points:
            access OUT_VePLTR_b_Odometer_KmFA_Value: accessed-variable=VePLTR_b_Odometer_KmFA.Value
        FsftPLTR_l_TravelDistance
          data-send-points:
            access OUT_VePLTR_b_TravelDistance_FA_Value: accessed-variable=VePLTR_b_TravelDistance_FA.Value
        FsftPLTR_p_AmbientAirPrs
          data-send-points:
            access OUT_VePLTR_p_AmbientAirPrs_Value: accessed-variable=VePLTR_p_AmbientAirPrs.Value
            access OUT_VePLTR_b_AmbientAirPrsFA_Value: accessed-variable=VePLTR_b_AmbientAirPrsFA.Value
          written-local-variables:
            access WV_VePLTR_p_AmbientAirPrs_write_IRV: accessed-variable=VePLTR_p_AmbientAirPrs_write_IRV
        FsftPLTR_phi_LwsAngle
          data-send-points:
            access OUT_VePLTR_b_LwsAngleFA_Value: accessed-variable=VePLTR_b_LwsAngleFA.Value
        FsftPLTR_t_GPS_UTC_Second
          written-local-variables:
            access WV_VePLTR_b_GPS_UTC_SecondFA_write_IRV: accessed-variable=VePLTR_b_GPS_UTC_SecondFA_write_IRV
        FsftPLTR_tdy_GPS_Date_Day
          written-local-variables:
            access WV_VePLTR_b_GPS_Date_DayFA_write_IRV: accessed-variable=VePLTR_b_GPS_Date_DayFA_write_IRV
        FsftPLTR_thr_GPS_UTC_Hour
          written-local-variables:
            access WV_VePLTR_b_GPS_UTC_HourFA_write_IRV: accessed-variable=VePLTR_b_GPS_UTC_HourFA_write_IRV
        FsftPLTR_tmn_GPS_UTC_Minute
          written-local-variables:
            access WV_VePLTR_b_GPS_UTC_MinuteFA_write_IRV: accessed-variable=VePLTR_b_GPS_UTC_MinuteFA_write_IRV
        FsftPLTR_tmt_GPS_Date_Month
          written-local-variables:
            access WV_VePLTR_b_GPS_Date_MonthFA_write_IRV: accessed-variable=VePLTR_b_GPS_Date_MonthFA_write_IRV
        FsftPLTR_tyr_GPS_Date_Year
          written-local-variables:
            access WV_VePLTR_b_GPS_Date_YearFA_write_IRV: accessed-variable=VePLTR_b_GPS_Date_YearFA_write_IRV
        FsftPLTR_y_AUD_LVL
          data-send-points:
            access OUT_VePLTR_b_AUD_LVL_FA_Value: accessed-variable=VePLTR_b_AUD_LVL_FA.Value
        FsftPLTR_y_FobSearchResult
          data-send-points:
            access OUT_VePLTR_b_FobSearchResult_FA_Value: accessed-variable=VePLTR_b_FobSearchResult_FA.Value
        PokePLTR_Pct_Slope
          data-send-points:
            access OUT_VePLTR_Pct_Slope_Value: accessed-variable=VePLTR_Pct_Slope.Value
            access OUT_VePLTR_b_Slope_FA_Value: accessed-variable=VePLTR_b_Slope_FA.Value
        PokePLTR_ReInit_EEPROM
          data-receive-point-by-arguments:
            access IN_VeBSWR_e_ITIDLifetimeEEProgStatus_Value: accessed-variable=VeBSWR_e_ITIDLifetimeEEProgStatus.Value
          data-send-points:
            access OUT_VePLTR_b_ResetFlagLifetime_EEerror_Value: accessed-variable=VePLTR_b_ResetFlagLifetime_EEerror.Value
        PokePLTR_W_Inverter_PowerDraw
          data-send-points:
            access OUT_VePLTR_W_Inverter_PowerDraw_Value: accessed-variable=VePLTR_W_Inverter_PowerDraw.Value
            access OUT_VePLTR_b_Inverter_PowerDraw_FA_Value: accessed-variable=VePLTR_b_Inverter_PowerDraw_FA.Value
        PokePLTR_a_LatAccel_ORC
          data-send-points:
            access OUT_VePLTR_a_LatAccel_ORC_Value: accessed-variable=VePLTR_a_LatAccel_ORC.Value
        PokePLTR_a_LongAccel
          data-send-points:
            access OUT_VePLTR_a_LongAccel_Value: accessed-variable=VePLTR_a_LongAccel.Value
            access OUT_VePLTR_b_LongAccelFA_Value: accessed-variable=VePLTR_b_LongAccelFA.Value
          written-local-variables:
            access WV_VePLTR_a_LongAccel_write_IRV: accessed-variable=VePLTR_a_LongAccel_write_IRV
            access WV_VePLTR_b_LongAccelFA_write_IRV: accessed-variable=VePLTR_b_LongAccelFA_write_IRV
        PokePLTR_a_LongAccelOffset
          data-send-points:
            access OUT_VePLTR_a_LongAccelOffset_Value: accessed-variable=VePLTR_a_LongAccelOffset.Value
          written-local-variables:
            access WV_VePLTR_a_LongAccelOffset_write_IRV: accessed-variable=VePLTR_a_LongAccelOffset_write_IRV
            access WV_VePLTR_b_LongAccelOffsetFA_write_IRV: accessed-variable=VePLTR_b_LongAccelOffsetFA_write_IRV
        PokePLTR_a_LongAccel_ORC
          data-send-points:
            access OUT_VePLTR_a_LongAccel_ORC_Value: accessed-variable=VePLTR_a_LongAccel_ORC.Value
        PokePLTR_a_TransAccel
          data-send-points:
            access OUT_VePLTR_a_LatAccel_Value: accessed-variable=VePLTR_a_LatAccel.Value
            access OUT_VePLTR_b_LatAccelFA_Value: accessed-variable=VePLTR_b_LatAccelFA.Value
          written-local-variables:
            access WV_VePLTR_a_TransAccel_write_IRV: accessed-variable=VePLTR_a_TransAccel_write_IRV
            access WV_VePLTR_b_TransAccelFA_write_IRV: accessed-variable=VePLTR_b_TransAccelFA_write_IRV
        PokePLTR_a_TransAccelOffset
          written-local-variables:
            access WV_VePLTR_a_TransAccelOffset_write_IRV: accessed-variable=VePLTR_a_TransAccelOffset_write_IRV
            access WV_VePLTR_b_TransAccelOffsetFA_write_IRV: accessed-variable=VePLTR_b_TransAccelOffsetFA_write_IRV
        PokePLTR_b_ACCEnbld
          written-local-variables:
            access WV_VePLTR_b_ACCEnbledInit_write_IRV: accessed-variable=VePLTR_b_ACCEnbledInit_write_IRV
        PokePLTR_b_ACC_On
          data-send-points:
            access OUT_VePLTR_b_ACC_On_Value: accessed-variable=VePLTR_b_ACC_On.Value
            access OUT_VePLTR_b_ACC_OnFA_Value: accessed-variable=VePLTR_b_ACC_OnFA.Value
        PokePLTR_b_ASCM_Srv
          data-send-points:
            access OUT_VePLTR_b_ASCM_Srv_Value: accessed-variable=VePLTR_b_ASCM_Srv.Value
            access OUT_VePLTR_b_ASCM_Srv_FA_Value: accessed-variable=VePLTR_b_ASCM_Srv_FA.Value
        PokePLTR_b_ASCM_SysFail
          data-send-points:
            access OUT_VePLTR_b_ASCM_SysFail_Value: accessed-variable=VePLTR_b_ASCM_SysFail.Value
            access OUT_VePLTR_b_ASCM_SysFail_FA_Value: accessed-variable=VePLTR_b_ASCM_SysFail_FA.Value
        PokePLTR_b_ASCM_SysSys
          data-send-points:
            access OUT_VePLTR_b_ADS_SrvSys_Value: accessed-variable=VePLTR_b_ADS_SrvSys.Value
            access OUT_VePLTR_b_ADS_SrvSys_FA_Value: accessed-variable=VePLTR_b_ADS_SrvSys_FA.Value
        PokePLTR_b_CC_Type
          data-send-points:
            access OUT_VePLTR_b_CC_Type_Value: accessed-variable=VePLTR_b_CC_Type.Value
        PokePLTR_b_ChargeReq
          data-send-points:
            access OUT_VePLTR_b_ChargeReq_Value: accessed-variable=VePLTR_b_ChargeReq.Value
            access OUT_VePLTR_b_ChargeReqSgnlRcvd_Value: accessed-variable=VePLTR_b_ChargeReqSgnlRcvd.Value
        PokePLTR_b_CrsCntrlActv
          written-local-variables:
            access WV_VePLTR_b_CrsCntrlActv_write_IRV: accessed-variable=VePLTR_b_CrsCntrlActv_write_IRV
        PokePLTR_b_DoorFailSts
          written-local-variables:
            access WV_VePLTR_b_DoorFailSts_Init_write_IRV: accessed-variable=VePLTR_b_DoorFailSts_Init_write_IRV
        PokePLTR_b_DriverSeatBeltSts
          data-send-points:
            access OUT_VePLTR_e_DriverSeatBeltSts_Value: accessed-variable=VePLTR_e_DriverSeatBeltSts.Value
            access OUT_VePLTR_b_DriverSeatBeltStsFA_Value: accessed-variable=VePLTR_b_DriverSeatBeltStsFA.Value
          written-local-variables:
            access WV_VePLTR_b_DriverSeatBeltStsFA_write_IRV: accessed-variable=VePLTR_b_DriverSeatBeltStsFA_write_IRV
            access WV_VePLTR_e_DriverSeatBeltSts_write_IRV: accessed-variable=VePLTR_e_DriverSeatBeltSts_write_IRV
        PokePLTR_b_DrvDrAjar
          data-send-points:
            access OUT_VePLTR_b_DrvDrAjar_Value: accessed-variable=VePLTR_b_DrvDrAjar.Value
          written-local-variables:
            access WV_VePLTR_b_DrvDrAjar_write_IRV: accessed-variable=VePLTR_b_DrvDrAjar_write_IRV
        PokePLTR_b_DrvrSeatSnsrFailSts
          written-local-variables:
            access WV_DrvrSeatSnsr_FailSts_Init_write_IRV: accessed-variable=DrvrSeatSnsr_FailSts_Init_write_IRV
        PokePLTR_b_EPBFailSts
          data-send-points:
            access OUT_VePLTR_b_EPBFailSts_Value: accessed-variable=VePLTR_b_EPBFailSts.Value
        PokePLTR_b_ESSActvEBrake
        PokePLTR_b_ESSRqShftPark
          data-send-points:
            access OUT_VePLTR_b_ESSRqShftPark_Value: accessed-variable=VePLTR_b_ESSRqShftPark.Value
        PokePLTR_b_FuelLevelLowClster
          written-local-variables:
            access WV_FuelLevelLowClster_Init_write_IRV: accessed-variable=FuelLevelLowClster_Init_write_IRV
        PokePLTR_b_HDCEnabledCAN
          data-send-points:
            access OUT_VePLTR_b_HDCEnabledCAN_Value: accessed-variable=VePLTR_b_HDCEnabledCAN.Value
            access OUT_VePLTR_b_HDCEnabledCAN_FA_Value: accessed-variable=VePLTR_b_HDCEnabledCAN_FA.Value
        PokePLTR_b_HotEnablerReq
          data-send-points:
            access OUT_VePLTR_b_HotEnablerReq_Value: accessed-variable=VePLTR_b_HotEnablerReq.Value
        PokePLTR_b_ImmoParkReq
          data-send-points:
            access OUT_VePLTR_b_ImmoParkReq_Value: accessed-variable=VePLTR_b_ImmoParkReq.Value
        PokePLTR_b_InPlantAllowCharge
          data-send-points:
            access OUT_VePLTR_b_InPlantAllowCharge_Value: accessed-variable=VePLTR_b_InPlantAllowCharge.Value
        PokePLTR_b_InternalLightSts
          data-send-points:
            access OUT_VePLTR_b_InternalLightSts_Value: accessed-variable=VePLTR_b_InternalLightSts.Value
        PokePLTR_b_LHRDoorSts
          data-send-points:
            access OUT_VePLTR_b_LHRDoorSts_Value: accessed-variable=VePLTR_b_LHRDoorSts.Value
            access OUT_VePLTR_b_LHRDoorSts_FA_Value: accessed-variable=VePLTR_b_LHRDoorSts_FA.Value
        PokePLTR_b_LatAccelFailSts_ORC
          data-send-points:
            access OUT_VePLTR_b_LatAccelFailSts_ORC_Value: accessed-variable=VePLTR_b_LatAccelFailSts_ORC.Value
        PokePLTR_b_LongAccelFailSts_ORC
          data-send-points:
            access OUT_VePLTR_b_LongAccelFailSts_ORC_Value: accessed-variable=VePLTR_b_LongAccelFailSts_ORC.Value
        PokePLTR_b_MILOnRq_ESC
          data-send-points:
            access OUT_VePLTR_b_MILOnRq_ESC_Value: accessed-variable=VePLTR_b_MILOnRq_ESC.Value
        PokePLTR_b_ParkBrakeSts
          data-send-points:
            access OUT_VePLTR_b_ParkBrakeSts_Value: accessed-variable=VePLTR_b_ParkBrakeSts.Value
            access OUT_VePLTR_b_ParkBrakeSts_FA_Value: accessed-variable=VePLTR_b_ParkBrakeSts_FA.Value
        PokePLTR_b_Prmry_ManualMode
          written-local-variables:
            access WV_VePLTR_b_Prmry_ManualModeFA_write_IRV: accessed-variable=VePLTR_b_Prmry_ManualModeFA_write_IRV
            access WV_ManualMode_Init_write_IRV: accessed-variable=ManualMode_Init_write_IRV
        PokePLTR_b_Prmry_PRNDFailSts
          written-local-variables:
            access WV_VePLTR_b_Prmry_PRNDFailStsFA_write_IRV: accessed-variable=VePLTR_b_Prmry_PRNDFailStsFA_write_IRV
        PokePLTR_b_Prmry_RFHub_ForcePark
          written-local-variables:
            access WV_VePLTR_b_Prmry_ForceParkFA_write_IRV: accessed-variable=VePLTR_b_Prmry_ForceParkFA_write_IRV
            access WV_RFHub_ForcePark_Init_write_IRV: accessed-variable=RFHub_ForcePark_Init_write_IRV
        PokePLTR_b_Prmry_RackDetentSensorFA
          written-local-variables:
            access WV_VePLTR_b_Prmry_RackDetentSensorFAFA_write_IRV: accessed-variable=VePLTR_b_Prmry_RackDetentSensorFAFA_write_IRV
        PokePLTR_b_Prmry_ShiftLeverFailSts
          written-local-variables:
            access WV_VePLTR_b_Prmry_ShiftLeverFailStsFA_write_IRV: accessed-variable=VePLTR_b_Prmry_ShiftLeverFailStsFA_write_IRV
        PokePLTR_b_Prmry_ShiftLockFA
          written-local-variables:
            access WV_VePLTR_b_Prmry_ShiftLockFAFA_write_IRV: accessed-variable=VePLTR_b_Prmry_ShiftLockFAFA_write_IRV
        PokePLTR_b_Prmry_ShiftSnsFA
          written-local-variables:
            access WV_VePLTR_b_Prmry_ShiftSnsFAFA_write_IRV: accessed-variable=VePLTR_b_Prmry_ShiftSnsFAFA_write_IRV
        PokePLTR_b_Prmry_ShifterDispFA
          written-local-variables:
            access WV_VePLTR_b_Prmry_ShifterDispFAFA_write_IRV: accessed-variable=VePLTR_b_Prmry_ShifterDispFAFA_write_IRV
        PokePLTR_b_PsngrDoorSts
          data-send-points:
            access OUT_VePLTR_b_PsngrDoorSts_Value: accessed-variable=VePLTR_b_PsngrDoorSts.Value
            access OUT_VePLTR_b_PsngrDoorSts_FA_Value: accessed-variable=VePLTR_b_PsngrDoorSts_FA.Value
        PokePLTR_b_RHRDoorSts
          data-send-points:
            access OUT_VePLTR_b_RHRDoorSts_Value: accessed-variable=VePLTR_b_RHRDoorSts.Value
            access OUT_VePLTR_b_RHRDoorSts_FA_Value: accessed-variable=VePLTR_b_RHRDoorSts_FA.Value
        PokePLTR_b_RHatchSts
          data-send-points:
            access OUT_VePLTR_b_RHatchSts_Value: accessed-variable=VePLTR_b_RHatchSts.Value
            access OUT_VePLTR_b_RHatchSts_FA_Value: accessed-variable=VePLTR_b_RHatchSts_FA.Value
        PokePLTR_b_RearFogLightSts
          data-send-points:
            access OUT_VePLTR_b_RearFogLightSts_Value: accessed-variable=VePLTR_b_RearFogLightSts.Value
        PokePLTR_b_RmtVehStartReq
          data-send-points:
            access OUT_VePLTR_b_RmtVehStartReq_Value: accessed-variable=VePLTR_b_RmtVehStartReq.Value
        PokePLTR_b_Scndry_PRNDFailSts
          written-local-variables:
            access WV_VePLTR_b_Scndry_PRNDFailStsFA_write_IRV: accessed-variable=VePLTR_b_Scndry_PRNDFailStsFA_write_IRV
        PokePLTR_b_Scndry_RFHub_ForcePark
          written-local-variables:
            access WV_VePLTR_b_Scndry_ForceParkFA_write_IRV: accessed-variable=VePLTR_b_Scndry_ForceParkFA_write_IRV
            access WV_RFHUB_ForcePark_Init_PwrOn_1_IRV_IRV: accessed-variable=RFHUB_ForcePark_Init_PwrOn_1_IRV_IRV
        PokePLTR_b_Scndry_RackDetentSensorFA
          written-local-variables:
            access WV_VePLTR_b_Scndry_RackDetentSensorFAFA_write_IRV: accessed-variable=VePLTR_b_Scndry_RackDetentSensorFAFA_write_IRV
        PokePLTR_b_Scndry_ShiftLeverFailSts
          written-local-variables:
            access WV_VePLTR_b_Scndry_ShiftLeverFailStsFA_write_IRV: accessed-variable=VePLTR_b_Scndry_ShiftLeverFailStsFA_write_IRV
        PokePLTR_b_Scndry_ShiftLockFA
          written-local-variables:
            access WV_VePLTR_b_Scndry_ShiftLockFAFA_write_IRV: accessed-variable=VePLTR_b_Scndry_ShiftLockFAFA_write_IRV
        PokePLTR_b_Scndry_ShiftSnsFA
          written-local-variables:
            access WV_VePLTR_b_Scndry_ShiftSnsFAFA_write_IRV: accessed-variable=VePLTR_b_Scndry_ShiftSnsFAFA_write_IRV
        PokePLTR_b_Scndry_ShifterDispFA
          written-local-variables:
            access WV_VePLTR_b_Scndry_ShifterDispFAFA_write_IRV: accessed-variable=VePLTR_b_Scndry_ShifterDispFAFA_write_IRV
        PokePLTR_b_Secure_Idle_Req
          data-send-points:
            access OUT_VePLTR_b_Secure_Idle_Req_Value: accessed-variable=VePLTR_b_Secure_Idle_Req.Value
            access OUT_VePLTR_b_Secure_Idle_Req_FA_Value: accessed-variable=VePLTR_b_Secure_Idle_Req_FA.Value
        PokePLTR_b_SpeedUnit
          written-local-variables:
            access WV_VePLTR_b_SpeedUnit_Init_write_IRV: accessed-variable=VePLTR_b_SpeedUnit_Init_write_IRV
        PokePLTR_b_Worksite_Inverter_Active
          data-send-points:
            access OUT_VePLTR_b_Worksite_Inverter_Active_Value: accessed-variable=VePLTR_b_Worksite_Inverter_Active.Value
            access OUT_VePLTR_b_Worksite_Inverter_Active_FA_Value: accessed-variable=VePLTR_b_Worksite_Inverter_Active_FA.Value
        PokePLTR_b_YawRateFailSts_ORC
          data-send-points:
            access OUT_VePLTR_b_YawRateFailSts_ORC_Value: accessed-variable=VePLTR_b_YawRateFailSts_ORC.Value
        PokePLTR_dphi_LwsSpeed
          data-send-points:
            access OUT_VePLTR_dphi_LwsSpeed_Value: accessed-variable=VePLTR_dphi_LwsSpeed.Value
        PokePLTR_dphi_YawRate_ORC
          data-send-points:
            access OUT_VePLTR_dphi_YawRate_ORC_Value: accessed-variable=VePLTR_dphi_YawRate_ORC.Value
        PokePLTR_e_ACCSystemSts
          data-send-points:
            access OUT_VePLTR_e_ACCSystemSts_Value: accessed-variable=VePLTR_e_ACCSystemSts.Value
            access OUT_VePLTR_b_ACCSystemSts_FA_Value: accessed-variable=VePLTR_b_ACCSystemSts_FA.Value
        PokePLTR_e_AEBSystemSts
          data-send-points:
            access OUT_VePLTR_e_AEBSystemSts_Value: accessed-variable=VePLTR_e_AEBSystemSts.Value
            access OUT_VePLTR_b_AEBSystemSts_FA_Value: accessed-variable=VePLTR_b_AEBSystemSts_FA.Value
        PokePLTR_e_ASCM_Stat
          data-send-points:
            access OUT_VePLTR_e_ASCM_Stat_Value: accessed-variable=VePLTR_e_ASCM_Stat.Value
            access OUT_VePLTR_b_ASCM_Stat_FA_Value: accessed-variable=VePLTR_b_ASCM_Stat_FA.Value
        PokePLTR_e_BSM_AxleTrq_Enbld
          data-send-points:
            access OUT_VePLTR_e_BSM_AxleTrq_Enbld_Value: accessed-variable=VePLTR_e_BSM_AxleTrq_Enbld.Value
        PokePLTR_e_Command_15Sts
          data-send-points:
            access OUT_VePLTR_e_Command_15Sts_Value: accessed-variable=VePLTR_e_Command_15Sts.Value
            access OUT_VePLTR_b_Command_15Sts_FA_Value: accessed-variable=VePLTR_b_Command_15Sts_FA.Value
        PokePLTR_e_DriverDoorOnOffSts
          written-local-variables:
            access WV_VePLTR_b_DriverDoorOnOffSts_FA_IRV: accessed-variable=VePLTR_b_DriverDoorOnOffSts_FA_IRV
            access WV_VePLTR_e_DriverDoorOnOffSts_Init_IRV: accessed-variable=VePLTR_e_DriverDoorOnOffSts_Init_IRV
        PokePLTR_e_DrvrSeatSnsrSts
          written-local-variables:
            access WV_VePLTR_b_DrvrSeatSnsrSts_FA_write_IRV: accessed-variable=VePLTR_b_DrvrSeatSnsrSts_FA_write_IRV
            access WV_DrvrSeatSnsrSts_Init_write_IRV: accessed-variable=DrvrSeatSnsrSts_Init_write_IRV
        PokePLTR_e_ECMVtdFreeze
          written-local-variables:
            access WV_VePLTR_e_ECMVtdFreezeInit_write_IRV: accessed-variable=VePLTR_e_ECMVtdFreezeInit_write_IRV
        PokePLTR_e_EPBHoldSt
          data-send-points:
            access OUT_VePLTR_e_EPBHoldSts_Value: accessed-variable=VePLTR_e_EPBHoldSts.Value
            access OUT_VePLTR_b_EPBHoldStsFA_Value: accessed-variable=VePLTR_b_EPBHoldStsFA.Value
        PokePLTR_e_ERS_SW
          data-send-points:
            access OUT_VePLTR_e_ERS_SW_Value: accessed-variable=VePLTR_e_ERS_SW.Value
            access OUT_VePLTR_b_ERS_SWFA_Value: accessed-variable=VePLTR_b_ERS_SWFA.Value
        PokePLTR_e_GatedParkSw_FaultSts
          written-local-variables:
            access WV_HWIO_GatedParkSWFault_write_IRV: accessed-variable=HWIO_GatedParkSWFault_write_IRV
        PokePLTR_e_HAS_TelltaleSts
          data-send-points:
            access OUT_VePLTR_e_HAS_TelltaleSts_Value: accessed-variable=VePLTR_e_HAS_TelltaleSts.Value
            access OUT_VePLTR_b_HAS_TelltaleSts_FA_Value: accessed-variable=VePLTR_b_HAS_TelltaleSts_FA.Value
        PokePLTR_e_HiBmLvr_Stat
          data-send-points:
            access OUT_VePLTR_e_HiBmLvr_Stat_Value: accessed-variable=VePLTR_e_HiBmLvr_Stat.Value
            access OUT_VePLTR_b_HiBmLvr_Stat_FA_Value: accessed-variable=VePLTR_b_HiBmLvr_Stat_FA.Value
        PokePLTR_e_InvrOprStatus
          data-send-points:
            access OUT_VePLTR_e_InvOprStat_Value: accessed-variable=VePLTR_e_InvOprStat.Value
        PokePLTR_e_LSMDExtReleaseLockReq
          data-send-points:
            access OUT_VePLTR_e_LSMDExtReleaseLockReq_Value: accessed-variable=VePLTR_e_LSMDExtReleaseLockReq.Value
        PokePLTR_e_LwsAngleType
          data-send-points:
            access OUT_VePLTR_e_LwsAngleType_Value: accessed-variable=VePLTR_e_LwsAngleType.Value
        PokePLTR_e_MRM_Status
          data-send-points:
            access OUT_VePLTR_e_MRM_Status_Value: accessed-variable=VePLTR_e_MRM_Status.Value
            access OUT_VePLTR_b_MRM_Status_FA_Value: accessed-variable=VePLTR_b_MRM_Status_FA.Value
        PokePLTR_e_MRM_Status_C2
          data-send-points:
            access OUT_VePLTR_e_MRM_Status_C2_Value: accessed-variable=VePLTR_e_MRM_Status_C2.Value
            access OUT_VePLTR_e_MRM_Status_C2_FA_Value: accessed-variable=VePLTR_e_MRM_Status_C2_FA.Value
        PokePLTR_e_ParkingGearShiftReq_BSM
          data-send-points:
            access OUT_VePLTR_e_ParkingGearShiftReq_BSM_Value: accessed-variable=VePLTR_e_ParkingGearShiftReq_BSM.Value
            access OUT_VePLTR_b_ParkingGearShiftReq_BSM_FA_Value: accessed-variable=VePLTR_b_ParkingGearShiftReq_BSM_FA.Value
        PokePLTR_e_Prmry_AutoPosCorrMd
          written-local-variables:
            access WV_VePLTR_b_Prmry_AutoPosCorrMdFA_write_IRV: accessed-variable=VePLTR_b_Prmry_AutoPosCorrMdFA_write_IRV
            access WV_AutoPosCorrMd_Init_write_IRV: accessed-variable=AutoPosCorrMd_Init_write_IRV
        PokePLTR_e_Prmry_PRND_ValidatePstn
          written-local-variables:
            access WV_VePLTR_b_Prmry_PRND_ValidatePstnFA_write_IRV: accessed-variable=VePLTR_b_Prmry_PRND_ValidatePstnFA_write_IRV
            access WV_PRND_ValidatePstn_Init_write_IRV: accessed-variable=PRND_ValidatePstn_Init_write_IRV
        PokePLTR_e_Prmry_ShiftLeverPositionReq
          written-local-variables:
            access WV_VePLTR_b_Prmry_ShiftLeverPositionReqFA_write_IRV: accessed-variable=VePLTR_b_Prmry_ShiftLeverPositionReqFA_write_IRV
            access WV_ShiftLeverPositionReq_Init_write_IRV: accessed-variable=ShiftLeverPositionReq_Init_write_IRV
        PokePLTR_e_Prmry_TransShiftPstn
          data-send-points:
            access OUT_VePLTR_e_Prmry_TransShiftPstn_Value: accessed-variable=VePLTR_e_Prmry_TransShiftPstn.Value
            access OUT_VePLTR_b_Prmry_TransShiftPstnFA_Value: accessed-variable=VePLTR_b_Prmry_TransShiftPstnFA.Value
          written-local-variables:
            access WV_VePLTR_b_Prmry_TransShiftPstnFA_write_IRV: accessed-variable=VePLTR_b_Prmry_TransShiftPstnFA_write_IRV
            access WV_TransShiftPosInitMSG_write_IRV: accessed-variable=TransShiftPosInitMSG_write_IRV
        PokePLTR_e_Scndry_AutoPosCorrMd
          written-local-variables:
            access WV_VePLTR_b_Scndry_AutoPosCorrMdFA_write_IRV: accessed-variable=VePLTR_b_Scndry_AutoPosCorrMdFA_write_IRV
            access WV_AutoPosCorrMd_Ini_write_IRV: accessed-variable=AutoPosCorrMd_Ini_write_IRV
        PokePLTR_e_Scndry_PRND_ValidatePstn
          written-local-variables:
            access WV_VePLTR_b_Scndry_PRND_ValidatePstnFA_write_IRV: accessed-variable=VePLTR_b_Scndry_PRND_ValidatePstnFA_write_IRV
            access WV_PRND_ValidatePstn_InitSndry_write_IRV: accessed-variable=PRND_ValidatePstn_InitSndry_write_IRV
        PokePLTR_e_Scndry_ShiftLeverPositionReq
          written-local-variables:
            access WV_VePLTR_b_Scndry_ShiftLeverPositionReqFA_write_IRV: accessed-variable=VePLTR_b_Scndry_ShiftLeverPositionReqFA_write_IRV
            access WV_ShiftLeverPositionReq_Ini_write_IRV: accessed-variable=ShiftLeverPositionReq_Ini_write_IRV
        PokePLTR_e_Scndry_TransShiftPstn
          data-send-points:
            access OUT_VePLTR_e_Scndry_TransShiftPstn_Value: accessed-variable=VePLTR_e_Scndry_TransShiftPstn.Value
            access OUT_VePLTR_b_Scndry_TransShiftPstnFA_Value: accessed-variable=VePLTR_b_Scndry_TransShiftPstnFA.Value
          written-local-variables:
            access WV_VePLTR_b_Scndry_TransShiftPstnFA_write_IRV: accessed-variable=VePLTR_b_Scndry_TransShiftPstnFA_write_IRV
            access WV_TransShiftPos_InitMSG_write_IRV: accessed-variable=TransShiftPos_InitMSG_write_IRV
        PokePLTR_e_SelectSpdSts
          data-send-points:
            access OUT_VePLTR_e_SelectSpdSts_Value: accessed-variable=VePLTR_e_SelectSpdSts.Value
            access OUT_VePLTR_b_SelectSpdSts_FA_Value: accessed-variable=VePLTR_b_SelectSpdSts_FA.Value
        PokePLTR_e_ShipingMode
          data-send-points:
            access OUT_VePLTR_i_ShippingModeRaw_Value: accessed-variable=VePLTR_i_ShippingModeRaw.Value
          written-local-variables:
            access WV_VePLTI_e_ShippingMode_write_IRV: accessed-variable=VePLTI_e_ShippingMode_write_IRV
        PokePLTR_e_TowHaulMode
          data-send-points:
            access OUT_VePLTR_e_TowHaulMode_Value: accessed-variable=VePLTR_e_TowHaulMode.Value
        PokePLTR_e_V2GOprStat
          data-send-points:
            access OUT_VePLTR_e_V2GOprStat_Value: accessed-variable=VePLTR_e_V2GOprStat.Value
        PokePLTR_e_VehCfgSt
          data-send-points:
            access OUT_VePLTR_e_VehCfgSt_Value: accessed-variable=VePLTR_e_VehCfgSt.Value
        PokePLTR_e_Worksite_Inverter_Sts
          data-send-points:
            access OUT_VePLTR_e_Worksite_Inverter_Sts_Value: accessed-variable=VePLTR_e_Worksite_Inverter_Sts.Value
        PokePLTR_e_eBurn_Stages
          data-send-points:
            access OUT_VePLTR_e_eBurn_Stages_Value: accessed-variable=VePLTR_e_eBurn_Stages.Value
            access OUT_VePLTR_b_eBurn_Stages_FA_Value: accessed-variable=VePLTR_b_eBurn_Stages_FA.Value
        PokePLTR_l_Odometer_Km
          data-send-points:
            access OUT_VePLTR_kl_Odometer_Km_Value: accessed-variable=VePLTR_kl_Odometer_Km.Value
            access OUT_VePLTR_b_Odometer_KmFA_Value: accessed-variable=VePLTR_b_Odometer_KmFA.Value
          written-local-variables:
            access WV_VePLTI_kl_Odometer_Km_write_IRV: accessed-variable=VePLTI_kl_Odometer_Km_write_IRV
        PokePLTR_l_TravelDistance
          data-send-points:
            access OUT_VePLTR_l_TravelDistance_Value: accessed-variable=VePLTR_l_TravelDistance.Value
            access OUT_VePLTR_b_TravelDistance_FA_Value: accessed-variable=VePLTR_b_TravelDistance_FA.Value
        PokePLTR_p_AmbientAirPrs
          data-send-points:
            access OUT_VePLTR_p_AmbientAirPrs_Value: accessed-variable=VePLTR_p_AmbientAirPrs.Value
            access OUT_VePLTR_b_AmbientAirPrsFA_Value: accessed-variable=VePLTR_b_AmbientAirPrsFA.Value
          written-local-variables:
            access WV_VePLTR_p_AmbientAirPrs_write_IRV: accessed-variable=VePLTR_p_AmbientAirPrs_write_IRV
        PokePLTR_phi_LwsAngle
          data-send-points:
            access OUT_VePLTR_phi_LwsAngle_Value: accessed-variable=VePLTR_phi_LwsAngle.Value
            access OUT_VePLTR_b_LwsAngleFA_Value: accessed-variable=VePLTR_b_LwsAngleFA.Value
        PokePLTR_t_GPS_UTC_Second
          written-local-variables:
            access WV_VePLTR_b_GPS_UTC_SecondFA_write_IRV: accessed-variable=VePLTR_b_GPS_UTC_SecondFA_write_IRV
            access WV_VePLTR_t_GPS_UTC_Second_PwrOn_IRV: accessed-variable=VePLTR_t_GPS_UTC_Second_PwrOn_IRV
        PokePLTR_tdy_GPS_Date_Day
          written-local-variables:
            access WV_VePLTR_b_GPS_Date_DayFA_write_IRV: accessed-variable=VePLTR_b_GPS_Date_DayFA_write_IRV
            access WV_VePLTR_tdy_GPS_Date_Day_PwrOn_IRV: accessed-variable=VePLTR_tdy_GPS_Date_Day_PwrOn_IRV
        PokePLTR_thr_GPS_UTC_Hour
          written-local-variables:
            access WV_VePLTR_b_GPS_UTC_HourFA_write_IRV: accessed-variable=VePLTR_b_GPS_UTC_HourFA_write_IRV
            access WV_VePLTR_thr_GPS_UTC_Hour_PwrOn_IRV: accessed-variable=VePLTR_thr_GPS_UTC_Hour_PwrOn_IRV
        PokePLTR_tmn_GPS_UTC_Minute
          written-local-variables:
            access WV_VePLTR_b_GPS_UTC_MinuteFA_write_IRV: accessed-variable=VePLTR_b_GPS_UTC_MinuteFA_write_IRV
            access WV_VePLTR_tmn_GPS_UTC_Minute_PwrOn_IRV: accessed-variable=VePLTR_tmn_GPS_UTC_Minute_PwrOn_IRV
        PokePLTR_tmt_GPS_Date_Month
          written-local-variables:
            access WV_VePLTR_b_GPS_Date_MonthFA_write_IRV: accessed-variable=VePLTR_b_GPS_Date_MonthFA_write_IRV
            access WV_VePLTR_tmt_GPS_Date_Month_PwrOn_IRV: accessed-variable=VePLTR_tmt_GPS_Date_Month_PwrOn_IRV
        PokePLTR_tyr_GPS_Date_Year
          written-local-variables:
            access WV_VePLTR_b_GPS_Date_YearFA_write_IRV: accessed-variable=VePLTR_b_GPS_Date_YearFA_write_IRV
            access WV_VePLTR_tyr_GPS_Date_Year_PwrOn_IRV: accessed-variable=VePLTR_tyr_GPS_Date_Year_PwrOn_IRV
        PokePLTR_y_AUD_LVL
          data-send-points:
            access OUT_VePLTR_y_AUD_LVL_Value: accessed-variable=VePLTR_y_AUD_LVL.Value
            access OUT_VePLTR_b_AUD_LVL_FA_Value: accessed-variable=VePLTR_b_AUD_LVL_FA.Value
        PokePLTR_y_FobSearchResult
          data-send-points:
            access OUT_VePLTR_y_FobSearchResult_Value: accessed-variable=VePLTR_y_FobSearchResult.Value
            access OUT_VePLTR_b_FobSearchResult_FA_Value: accessed-variable=VePLTR_b_FobSearchResult_FA.Value
        TmotPLTR_b_ChargeReq
          data-send-points:
            access OUT_VePLTR_b_ChargeReqSgnlRcvd_Value: accessed-variable=VePLTR_b_ChargeReqSgnlRcvd.Value
